VERSION ""

NS_ :

BS_:

BU_: SOBDM_BCCM GWM GENERIC BECM TSTR

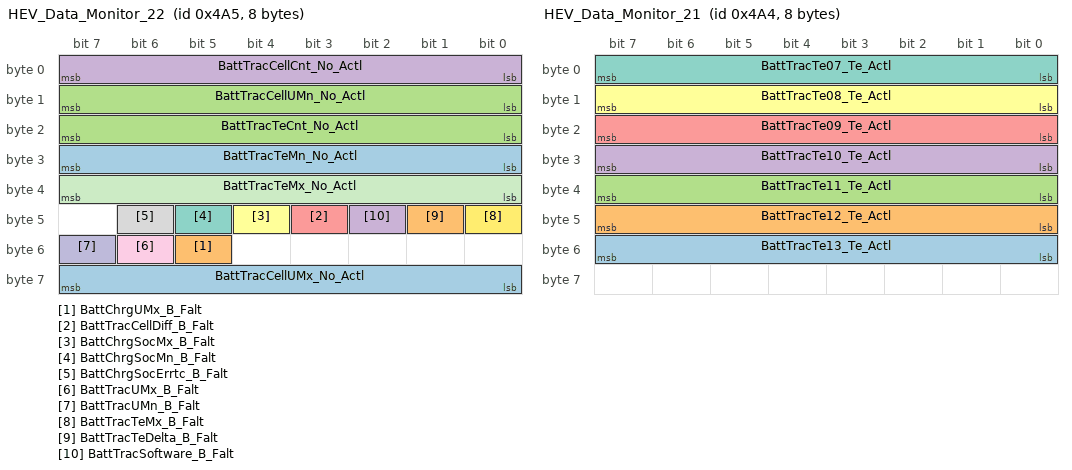
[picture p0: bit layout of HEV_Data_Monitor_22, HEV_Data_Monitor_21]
BO_ 1189 HEV_Data_Monitor_22: 8 BECM
 SG_ BattTracCellUMx_No_Actl : 63|8@0+ (1,0) [0|253] "Unitless"  GWM
 SG_ BattChrgUMx_B_Falt : 53|1@0+ (1,0) [0|1] "SED"  GWM
 SG_ BattTracCellUMn_No_Actl : 15|8@0+ (1,0) [0|253] "Unitless"  GWM
 SG_ BattTracCellCnt_No_Actl : 7|8@0+ (1,0) [0|253] "Unitless"  GWM
 SG_ BattTracCellDiff_B_Falt : 43|1@0+ (1,0) [0|1] "SED"  GWM
 SG_ BattChrgSocMx_B_Falt : 44|1@0+ (1,0) [0|1] "SED"  GWM
 SG_ BattChrgSocMn_B_Falt : 45|1@0+ (1,0) [0|1] "SED"  GWM
 SG_ BattChrgSocErrtc_B_Falt : 46|1@0+ (1,0) [0|1] "SED"  GWM
 SG_ BattTracUMx_B_Falt : 54|1@0+ (1,0) [0|1] "SED"  GWM
 SG_ BattTracUMn_B_Falt : 55|1@0+ (1,0) [0|1] "SED"  GWM
 SG_ BattTracTeMx_No_Actl : 39|8@0+ (1,0) [0|253] "Unitless"  GWM
 SG_ BattTracTeMx_B_Falt : 40|1@0+ (1,0) [0|1] "SED"  GWM
 SG_ BattTracTeMn_No_Actl : 31|8@0+ (1,0) [0|253] "Unitless"  GWM
 SG_ BattTracTeDelta_B_Falt : 41|1@0+ (1,0) [0|1] "SED"  GWM
 SG_ BattTracTeCnt_No_Actl : 23|8@0+ (1,0) [0|253] "Unitless"  GWM
 SG_ BattTracSoftware_B_Falt : 42|1@0+ (1,0) [0|1] "SED"  GWM

BO_ 1188 HEV_Data_Monitor_21: 8 BECM
 SG_ BattTracTe13_Te_Actl : 55|8@0+ (1,-50) [-50|203] "degC"  GWM
 SG_ BattTracTe12_Te_Actl : 47|8@0+ (1,-50) [-50|203] "degC"  GWM
 SG_ BattTracTe11_Te_Actl : 39|8@0+ (1,-50) [-50|203] "degC"  GWM
 SG_ BattTracTe10_Te_Actl : 31|8@0+ (1,-50) [-50|203] "degC"  GWM
 SG_ BattTracTe09_Te_Actl : 23|8@0+ (1,-50) [-50|203] "degC"  GWM
 SG_ BattTracTe08_Te_Actl : 15|8@0+ (1,-50) [-50|203] "degC"  GWM
 SG_ BattTracTe07_Te_Actl : 7|8@0+ (1,-50) [-50|203] "degC"  GWM

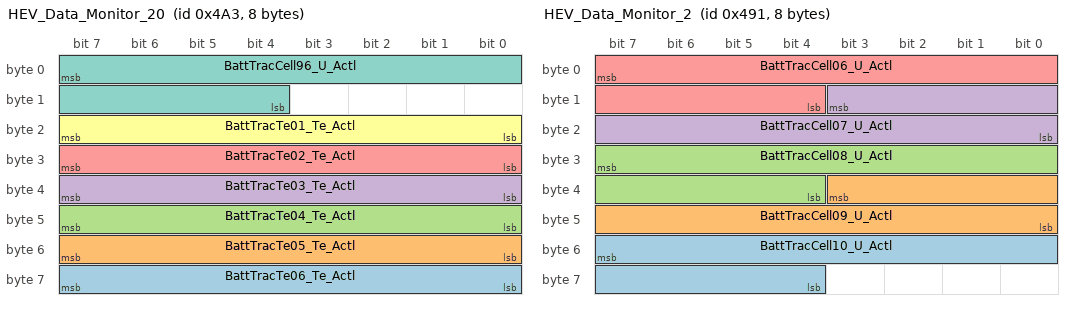
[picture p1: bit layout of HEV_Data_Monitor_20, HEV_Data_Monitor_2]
BO_ 1187 HEV_Data_Monitor_20: 8 BECM
 SG_ BattTracTe06_Te_Actl : 63|8@0+ (1,-50) [-50|203] "degC"  GWM
 SG_ BattTracTe05_Te_Actl : 55|8@0+ (1,-50) [-50|203] "degC"  GWM
 SG_ BattTracTe04_Te_Actl : 47|8@0+ (1,-50) [-50|203] "degC"  GWM
 SG_ BattTracTe03_Te_Actl : 39|8@0+ (1,-50) [-50|203] "degC"  GWM
 SG_ BattTracTe02_Te_Actl : 31|8@0+ (1,-50) [-50|203] "degC"  GWM
 SG_ BattTracTe01_Te_Actl : 23|8@0+ (1,-50) [-50|203] "degC"  GWM
 SG_ BattTracCell96_U_Actl : 7|12@0+ (0.001,1) [1|5.093] "volt"  GWM

BO_ 1169 HEV_Data_Monitor_2: 8 BECM
 SG_ BattTracCell10_U_Actl : 55|12@0+ (0.001,1) [1|5.093] "volt"  GWM
 SG_ BattTracCell09_U_Actl : 35|12@0+ (0.001,1) [1|5.093] "volt"  GWM
 SG_ BattTracCell08_U_Actl : 31|12@0+ (0.001,1) [1|5.093] "volt"  GWM
 SG_ BattTracCell07_U_Actl : 11|12@0+ (0.001,1) [1|5.093] "volt"  GWM
 SG_ BattTracCell06_U_Actl : 7|12@0+ (0.001,1) [1|5.093] "volt"  GWM

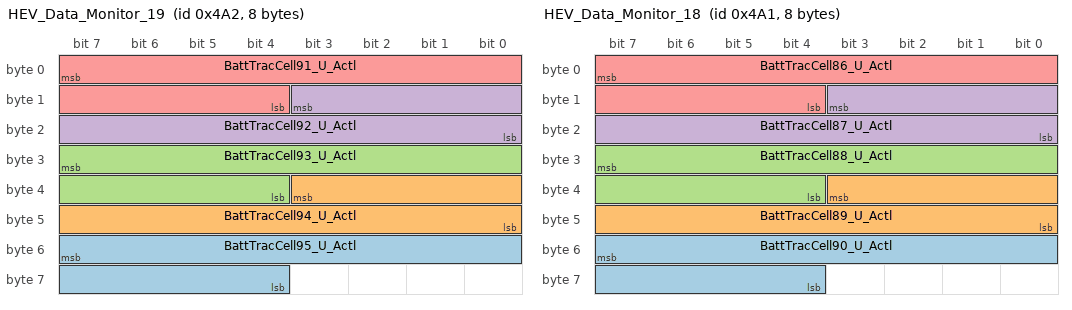
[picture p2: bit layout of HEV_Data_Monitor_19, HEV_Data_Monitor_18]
BO_ 1186 HEV_Data_Monitor_19: 8 BECM
 SG_ BattTracCell95_U_Actl : 55|12@0+ (0.001,1) [1|5.093] "volt"  GWM
 SG_ BattTracCell94_U_Actl : 35|12@0+ (0.001,1) [1|5.093] "volt"  GWM
 SG_ BattTracCell93_U_Actl : 31|12@0+ (0.001,1) [1|5.093] "volt"  GWM
 SG_ BattTracCell92_U_Actl : 11|12@0+ (0.001,1) [1|5.093] "volt"  GWM
 SG_ BattTracCell91_U_Actl : 7|12@0+ (0.001,1) [1|5.093] "volt"  GWM

BO_ 1185 HEV_Data_Monitor_18: 8 BECM
 SG_ BattTracCell90_U_Actl : 55|12@0+ (0.001,1) [1|5.093] "volt"  GWM
 SG_ BattTracCell89_U_Actl : 35|12@0+ (0.001,1) [1|5.093] "volt"  GWM
 SG_ BattTracCell88_U_Actl : 31|12@0+ (0.001,1) [1|5.093] "volt"  GWM
 SG_ BattTracCell87_U_Actl : 11|12@0+ (0.001,1) [1|5.093] "volt"  GWM
 SG_ BattTracCell86_U_Actl : 7|12@0+ (0.001,1) [1|5.093] "volt"  GWM

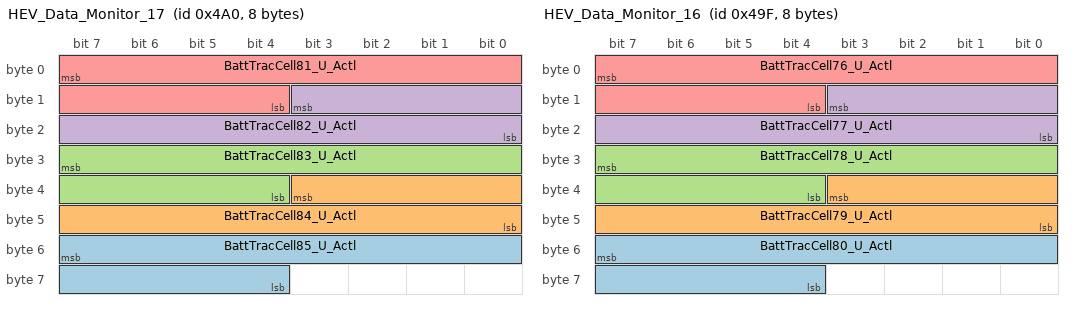
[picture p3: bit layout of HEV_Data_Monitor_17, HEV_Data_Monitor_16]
BO_ 1184 HEV_Data_Monitor_17: 8 BECM
 SG_ BattTracCell85_U_Actl : 55|12@0+ (0.001,1) [1|5.093] "volt"  GWM
 SG_ BattTracCell84_U_Actl : 35|12@0+ (0.001,1) [1|5.093] "volt"  GWM
 SG_ BattTracCell83_U_Actl : 31|12@0+ (0.001,1) [1|5.093] "volt"  GWM
 SG_ BattTracCell82_U_Actl : 11|12@0+ (0.001,1) [1|5.093] "volt"  GWM
 SG_ BattTracCell81_U_Actl : 7|12@0+ (0.001,1) [1|5.093] "volt"  GWM

BO_ 1183 HEV_Data_Monitor_16: 8 BECM
 SG_ BattTracCell80_U_Actl : 55|12@0+ (0.001,1) [1|5.093] "volt"  GWM
 SG_ BattTracCell79_U_Actl : 35|12@0+ (0.001,1) [1|5.093] "volt"  GWM
 SG_ BattTracCell78_U_Actl : 31|12@0+ (0.001,1) [1|5.093] "volt"  GWM
 SG_ BattTracCell77_U_Actl : 11|12@0+ (0.001,1) [1|5.093] "volt"  GWM
 SG_ BattTracCell76_U_Actl : 7|12@0+ (0.001,1) [1|5.093] "volt"  GWM

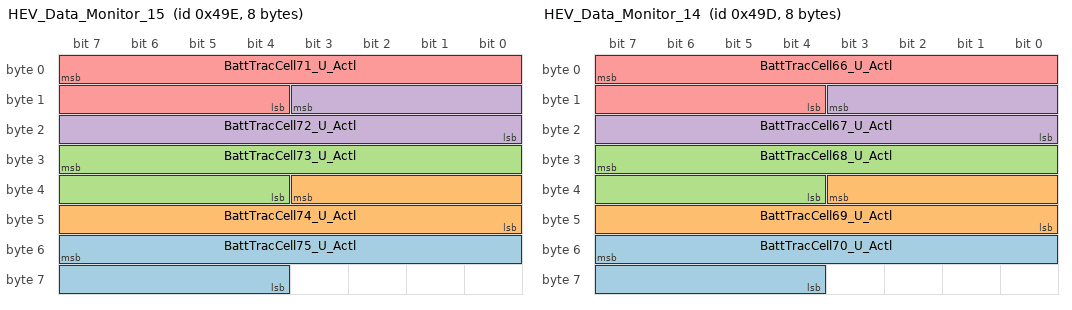
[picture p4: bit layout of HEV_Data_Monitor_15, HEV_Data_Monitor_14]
BO_ 1182 HEV_Data_Monitor_15: 8 BECM
 SG_ BattTracCell75_U_Actl : 55|12@0+ (0.001,1) [1|5.093] "volt"  GWM
 SG_ BattTracCell74_U_Actl : 35|12@0+ (0.001,1) [1|5.093] "volt"  GWM
 SG_ BattTracCell73_U_Actl : 31|12@0+ (0.001,1) [1|5.093] "volt"  GWM
 SG_ BattTracCell72_U_Actl : 11|12@0+ (0.001,1) [1|5.093] "volt"  GWM
 SG_ BattTracCell71_U_Actl : 7|12@0+ (0.001,1) [1|5.093] "volt"  GWM

BO_ 1181 HEV_Data_Monitor_14: 8 BECM
 SG_ BattTracCell70_U_Actl : 55|12@0+ (0.001,1) [1|5.093] "volt"  GWM
 SG_ BattTracCell69_U_Actl : 35|12@0+ (0.001,1) [1|5.093] "volt"  GWM
 SG_ BattTracCell68_U_Actl : 31|12@0+ (0.001,1) [1|5.093] "volt"  GWM
 SG_ BattTracCell67_U_Actl : 11|12@0+ (0.001,1) [1|5.093] "volt"  GWM
 SG_ BattTracCell66_U_Actl : 7|12@0+ (0.001,1) [1|5.093] "volt"  GWM

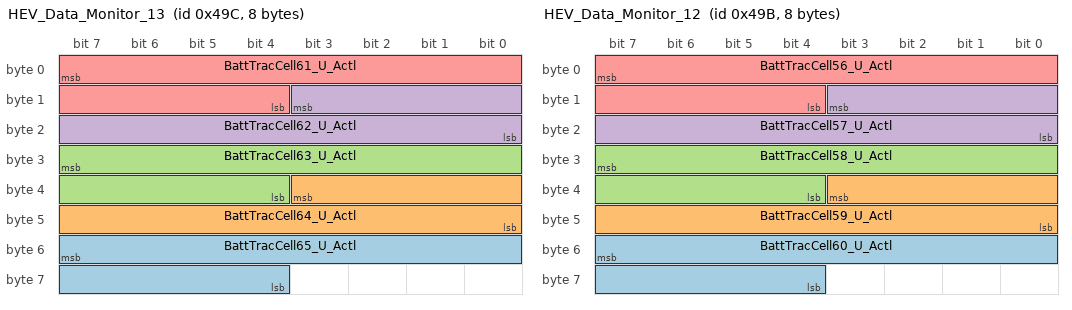
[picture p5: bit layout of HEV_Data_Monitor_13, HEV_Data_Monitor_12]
BO_ 1180 HEV_Data_Monitor_13: 8 BECM
 SG_ BattTracCell65_U_Actl : 55|12@0+ (0.001,1) [1|5.093] "volt"  GWM
 SG_ BattTracCell64_U_Actl : 35|12@0+ (0.001,1) [1|5.093] "volt"  GWM
 SG_ BattTracCell63_U_Actl : 31|12@0+ (0.001,1) [1|5.093] "volt"  GWM
 SG_ BattTracCell62_U_Actl : 11|12@0+ (0.001,1) [1|5.093] "volt"  GWM
 SG_ BattTracCell61_U_Actl : 7|12@0+ (0.001,1) [1|5.093] "volt"  GWM

BO_ 1179 HEV_Data_Monitor_12: 8 BECM
 SG_ BattTracCell60_U_Actl : 55|12@0+ (0.001,1) [1|5.093] "volt"  GWM
 SG_ BattTracCell59_U_Actl : 35|12@0+ (0.001,1) [1|5.093] "volt"  GWM
 SG_ BattTracCell58_U_Actl : 31|12@0+ (0.001,1) [1|5.093] "volt"  GWM
 SG_ BattTracCell57_U_Actl : 11|12@0+ (0.001,1) [1|5.093] "volt"  GWM
 SG_ BattTracCell56_U_Actl : 7|12@0+ (0.001,1) [1|5.093] "volt"  GWM

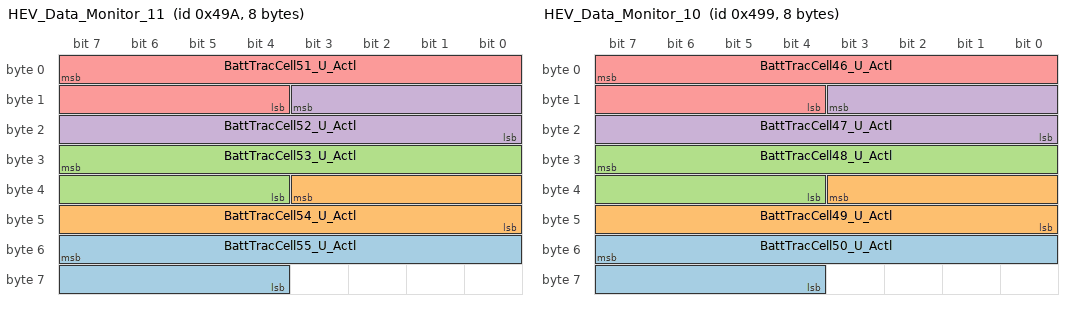
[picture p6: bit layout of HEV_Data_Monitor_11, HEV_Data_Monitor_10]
BO_ 1178 HEV_Data_Monitor_11: 8 BECM
 SG_ BattTracCell55_U_Actl : 55|12@0+ (0.001,1) [1|5.093] "volt"  GWM
 SG_ BattTracCell54_U_Actl : 35|12@0+ (0.001,1) [1|5.093] "volt"  GWM
 SG_ BattTracCell53_U_Actl : 31|12@0+ (0.001,1) [1|5.093] "volt"  GWM
 SG_ BattTracCell52_U_Actl : 11|12@0+ (0.001,1) [1|5.093] "volt"  GWM
 SG_ BattTracCell51_U_Actl : 7|12@0+ (0.001,1) [1|5.093] "volt"  GWM

BO_ 1177 HEV_Data_Monitor_10: 8 BECM
 SG_ BattTracCell50_U_Actl : 55|12@0+ (0.001,1) [1|5.093] "volt"  GWM
 SG_ BattTracCell49_U_Actl : 35|12@0+ (0.001,1) [1|5.093] "volt"  GWM
 SG_ BattTracCell48_U_Actl : 31|12@0+ (0.001,1) [1|5.093] "volt"  GWM
 SG_ BattTracCell47_U_Actl : 11|12@0+ (0.001,1) [1|5.093] "volt"  GWM
 SG_ BattTracCell46_U_Actl : 7|12@0+ (0.001,1) [1|5.093] "volt"  GWM

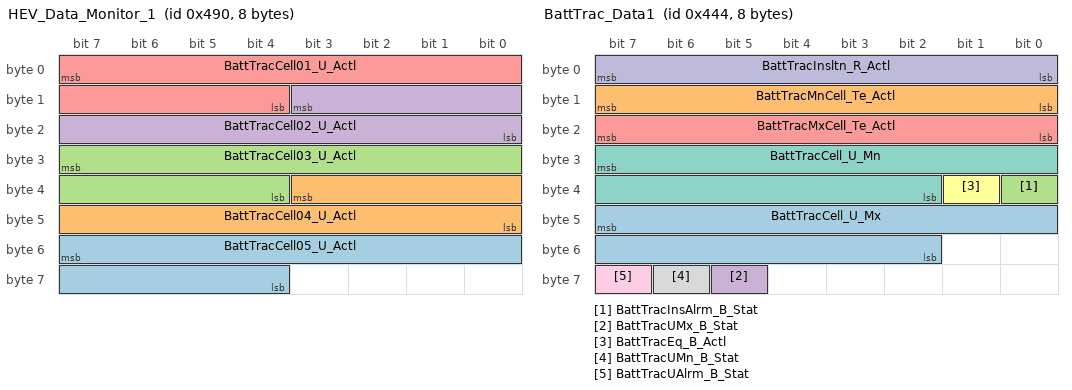
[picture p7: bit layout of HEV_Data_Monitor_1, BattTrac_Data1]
BO_ 1168 HEV_Data_Monitor_1: 8 BECM
 SG_ BattTracCell05_U_Actl : 55|12@0+ (0.001,1) [1|5.093] "volt"  GWM
 SG_ BattTracCell04_U_Actl : 35|12@0+ (0.001,1) [1|5.093] "volt"  GWM
 SG_ BattTracCell03_U_Actl : 31|12@0+ (0.001,1) [1|5.093] "volt"  GWM
 SG_ BattTracCell02_U_Actl : 11|12@0+ (0.001,1) [1|5.093] "volt"  GWM
 SG_ BattTracCell01_U_Actl : 7|12@0+ (0.001,1) [1|5.093] "volt"  GWM

BO_ 1092 BattTrac_Data1: 8 BECM
 SG_ BattTracCell_U_Mx : 47|14@0+ (0.001,0) [0|16.382] "volt"  GWM
 SG_ BattTracMnCell_Te_Actl : 15|8@0+ (1,-40) [-40|213] "degC"  GWM
 SG_ BattTracInsAlrm_B_Stat : 32|1@0+ (1,0) [0|1] "SED"  GWM
 SG_ BattTracUMx_B_Stat : 61|1@0+ (1,0) [0|1] "SED"  GWM
 SG_ BattTracMxCell_Te_Actl : 23|8@0+ (1,-40) [-40|213] "degC"  GWM
 SG_ BattTracEq_B_Actl : 33|1@0+ (1,0) [0|1] "SED"  GWM
 SG_ BattTracCell_U_Mn : 31|14@0+ (0.001,0) [0|16.382] "volt"  GWM
 SG_ BattTracUMn_B_Stat : 62|1@0+ (1,0) [0|1] "SED"  GWM
 SG_ BattTracUAlrm_B_Stat : 63|1@0+ (1,0) [0|1] "SED"  GWM
 SG_ BattTracInsltn_R_Actl : 7|8@0+ (6000,0) [0|1524000] "ohm"  GWM

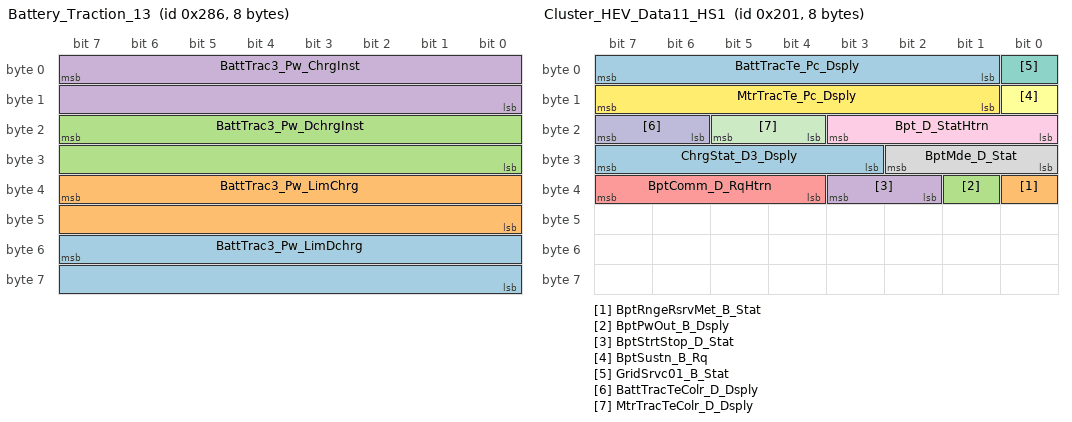
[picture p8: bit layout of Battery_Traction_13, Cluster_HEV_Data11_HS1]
BO_ 646 Battery_Traction_13: 8 BECM
 SG_ BattTrac3_Pw_LimDchrg : 55|16@0+ (50,0) [0|3276750] "watts"  GWM
 SG_ BattTrac3_Pw_LimChrg : 39|16@0+ (50,0) [0|3276750] "watts"  GWM
 SG_ BattTrac3_Pw_DchrgInst : 23|16@0+ (50,0) [0|3276750] "watts"  GWM
 SG_ BattTrac3_Pw_ChrgInst : 7|16@0+ (50,0) [0|3276750] "watts"  GWM

BO_ 513 Cluster_HEV_Data11_HS1: 8 GWM
 SG_ ChrgStat_D3_Dsply : 31|5@0+ (1,0) [0|31] "SED" Vector__XXX
 SG_ BptRngeRsrvMet_B_Stat : 32|1@0+ (1,0) [0|1] "SED" Vector__XXX
 SG_ BptPwOut_B_Dsply : 33|1@0+ (1,0) [0|1] "SED" Vector__XXX
 SG_ BptStrtStop_D_Stat : 35|2@0+ (1,0) [0|3] "SED" Vector__XXX
 SG_ BptComm_D_RqHtrn : 39|4@0+ (1,0) [0|15] "SED" Vector__XXX
 SG_ BptSustn_B_Rq : 8|1@0+ (1,0) [0|1] "SED"  BECM,SOBDM_BCCM
 SG_ GridSrvc01_B_Stat : 0|1@0+ (1,0) [0|1] "SED" Vector__XXX
 SG_ BptMde_D_Stat : 26|3@0+ (1,0) [0|7] "SED" Vector__XXX
 SG_ Bpt_D_StatHtrn : 19|4@0+ (1,0) [0|15] "SED"  BECM,SOBDM_BCCM
 SG_ BattTracTeColr_D_Dsply : 23|2@0+ (1,0) [0|3] "SED" Vector__XXX
 SG_ MtrTracTeColr_D_Dsply : 21|2@0+ (1,0) [0|3] "SED" Vector__XXX
 SG_ MtrTracTe_Pc_Dsply : 15|7@0+ (1,0) [0|127] "percent" Vector__XXX
 SG_ BattTracTe_Pc_Dsply : 7|7@0+ (1,0) [0|127] "percent" Vector__XXX

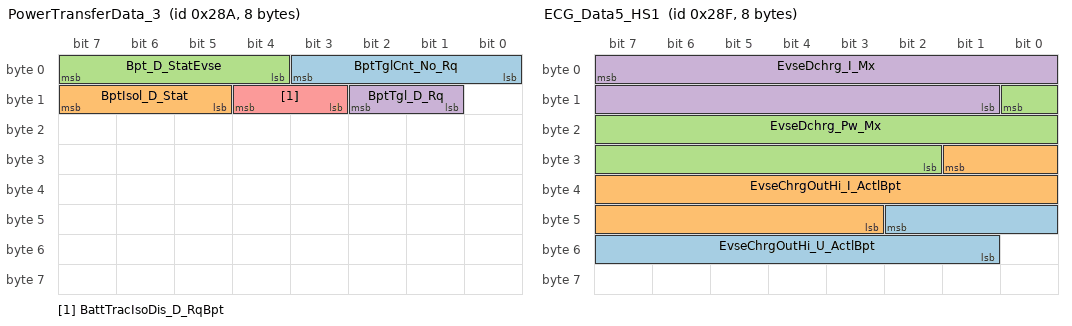
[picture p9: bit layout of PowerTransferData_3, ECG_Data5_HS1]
BO_ 650 PowerTransferData_3: 8 GWM
 SG_ BptTglCnt_No_Rq : 3|4@0+ (1,0) [0|13] "unitless"  SOBDM_BCCM
 SG_ BptIsol_D_Stat : 15|3@0+ (1,0) [0|7] "SED"  BECM
 SG_ Bpt_D_StatEvse : 7|4@0+ (1,0) [0|15] "SED"  BECM
 SG_ BptTgl_D_Rq : 10|2@0+ (1,0) [0|3] "SED"  SOBDM_BCCM
 SG_ BattTracIsoDis_D_RqBpt : 12|2@0+ (1,0) [0|3] "SED"  SOBDM_BCCM,BECM

BO_ 655 ECG_Data5_HS1: 8 GWM
 SG_ EvseChrgOutHi_U_ActlBpt : 42|10@0+ (0.5,0) [0|510.5] "volt"  SOBDM_BCCM
 SG_ EvseChrgOutHi_I_ActlBpt : 25|15@0+ (0.05,-750) [-750|888.25] "ampere"  SOBDM_BCCM
 SG_ EvseDchrg_Pw_Mx : 8|15@0+ (50,0) [0|1638250] "wattS"  SOBDM_BCCM
 SG_ EvseDchrg_I_Mx : 7|15@0+ (0.05,0) [0|1638.25] "ampere"  SOBDM_BCCM

BO_ 599 Battery_Traction_12: 8 BECM
 SG_ Bpt_D_StatBattTrac : 7|3@0+ (1,0) [0|7] "SED"  SOBDM_BCCM,GWM

BO_ 749 BatteryCharge_Data3: 8 SOBDM_BCCM
 SG_ ChrgrSysFalt18_D_Stat : 37|2@0+ (1,0) [0|3] "SED"  BECM,GWM
 SG_ ChrgrSysFalt17_D_Stat : 39|2@0+ (1,0) [0|3] "SED"  BECM,GWM
 SG_ ChrgrSysFalt16_D_Stat : 25|2@0+ (1,0) [0|3] "SED"  BECM,GWM
 SG_ ChrgrSysFalt15_D_Stat : 27|2@0+ (1,0) [0|3] "SED"  BECM,GWM
 SG_ ChrgrSysFalt14_D_Stat : 29|2@0+ (1,0) [0|3] "SED"  BECM,GWM
 SG_ ChrgrSysFalt13_D_Stat : 31|2@0+ (1,0) [0|3] "SED"  BECM,GWM
 SG_ ChrgrSysFalt12_D_Stat : 17|2@0+ (1,0) [0|3] "SED"  BECM,GWM
 SG_ ChrgrSysFalt11_D_Stat : 19|2@0+ (1,0) [0|3] "SED"  BECM,GWM
 SG_ ChrgrSysFalt9_D_Stat : 23|2@0+ (1,0) [0|3] "SED"  BECM,GWM
 SG_ ChrgrSysFalt8_D_Stat : 9|2@0+ (1,0) [0|3] "SED"  BECM,GWM
 SG_ ChrgrSysFalt7_D_Stat : 11|2@0+ (1,0) [0|3] "SED"  BECM,GWM
 SG_ ChrgrSysFalt6_D_Stat : 13|2@0+ (1,0) [0|3] "SED"  BECM,GWM
 SG_ ChrgrSysFalt5_D_Stat : 15|2@0+ (1,0) [0|3] "SED"  BECM,GWM
 SG_ ChrgrSysFalt4_D_Stat : 1|2@0+ (1,0) [0|3] "SED"  BECM,GWM
 SG_ ChrgrSysFalt3_D_Stat : 3|2@0+ (1,0) [0|3] "SED"  BECM,GWM
 SG_ ChrgrSysFalt2_D_Stat : 5|2@0+ (1,0) [0|3] "SED"  BECM,GWM
 SG_ ChrgrSysFalt1_D_Stat : 7|2@0+ (1,0) [0|3] "SED"  BECM,GWM
 SG_ ChrgrSysFalt10_D_Stat : 21|2@0+ (1,0) [0|3] "SED"  BECM,GWM

BO_ 580 Battery_Traction_11: 8 BECM
 SG_ BattTracVrtOck_B_Rq : 7|1@0+ (1,0) [0|1] "SED"  GWM

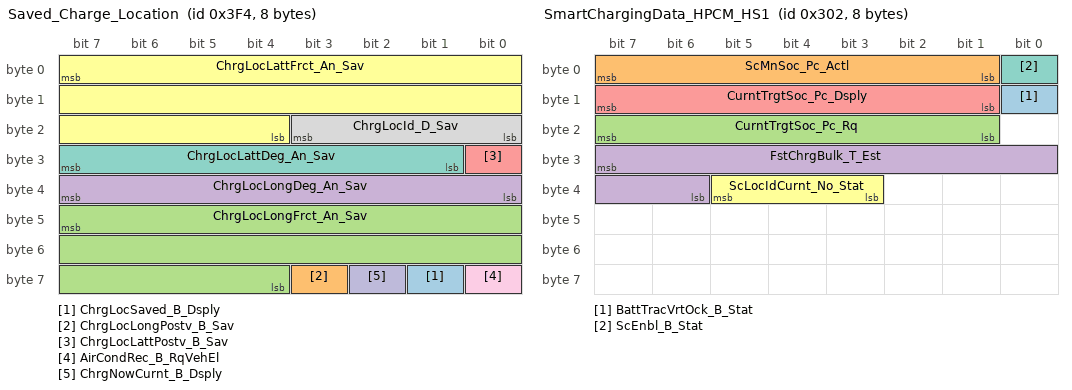
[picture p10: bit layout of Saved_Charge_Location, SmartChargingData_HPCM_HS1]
BO_ 1012 Saved_Charge_Location: 8 GWM
 SG_ ChrgLocSaved_B_Dsply : 57|1@0+ (1,0) [0|1] "SED" Vector__XXX
 SG_ ChrgLocLongPostv_B_Sav : 59|1@0+ (1,0) [0|1] "SED" Vector__XXX
 SG_ ChrgLocLongFrct_An_Sav : 47|20@0+ (1E-006,0) [0|1.048575] "degrees" Vector__XXX
 SG_ ChrgLocLongDeg_An_Sav : 39|8@0+ (1,0) [0|255] "degrees" Vector__XXX
 SG_ ChrgLocLattPostv_B_Sav : 24|1@0+ (1,0) [0|1] "SED" Vector__XXX
 SG_ ChrgLocLattFrct_An_Sav : 7|20@0+ (1E-006,0) [0|1.048575] "degrees" Vector__XXX
 SG_ ChrgLocLattDeg_An_Sav : 31|7@0+ (1,0) [0|127] "unitless" Vector__XXX
 SG_ ChrgLocId_D_Sav : 19|4@0+ (1,0) [0|15] "unitless" Vector__XXX
 SG_ AirCondRec_B_RqVehEl : 56|1@0+ (1,0) [0|1] "SED" Vector__XXX
 SG_ ChrgNowCurnt_B_Dsply : 58|1@0+ (1,0) [0|1] "SED"  SOBDM_BCCM

BO_ 1149 Battery_Traction_10: 8 BECM
 SG_ BattTracPerf_Pc_Dsply : 15|8@0+ (1,0) [0|253] "percent"  GWM
 SG_ BattTracPerf_Pc_Actl : 7|8@0+ (1,0) [0|253] "percent"  GWM

BO_ 1135 Battery_Traction_9: 8 BECM
 SG_ BattChrg_I2_Rq : 23|16@0+ (0.1,0) [0|6553.5] "ampere"  GWM,SOBDM_BCCM
 SG_ BattChrg_I2_Mx : 7|16@0+ (0.1,0) [0|6553.5] "ampere"  GWM

BO_ 770 SmartChargingData_HPCM_HS1: 8 GWM
 SG_ BattTracVrtOck_B_Stat : 8|1@0+ (1,0) [0|1] "SED" Vector__XXX
 SG_ ScMnSoc_Pc_Actl : 7|7@0+ (1,0) [0|127] "percent" Vector__XXX
 SG_ CurntTrgtSoc_Pc_Rq : 23|7@0+ (1,0) [0|127] "percent"  BECM
 SG_ FstChrgBulk_T_Est : 31|10@0+ (1,0) [0|1023] "minute" Vector__XXX
 SG_ CurntTrgtSoc_Pc_Dsply : 15|7@0+ (1,0) [0|127] "percent" Vector__XXX
 SG_ ScLocIdCurnt_No_Stat : 37|3@0+ (1,0) [0|7] "unitless" Vector__XXX
 SG_ ScEnbl_B_Stat : 0|1@0+ (1,0) [0|1] "SED" Vector__XXX

BO_ 123 Battery_Traction_2: 8 BECM
 SG_ BattTrac_U2_Actl : 21|12@0+ (0.5,0) [0|2046.5] "volt"  SOBDM_BCCM,GWM
 SG_ BattTrac_I2_Actl : 7|18@0+ (0.05,-6553.52) [-6553.52|6553.53] "ampere"  SOBDM_BCCM,GWM

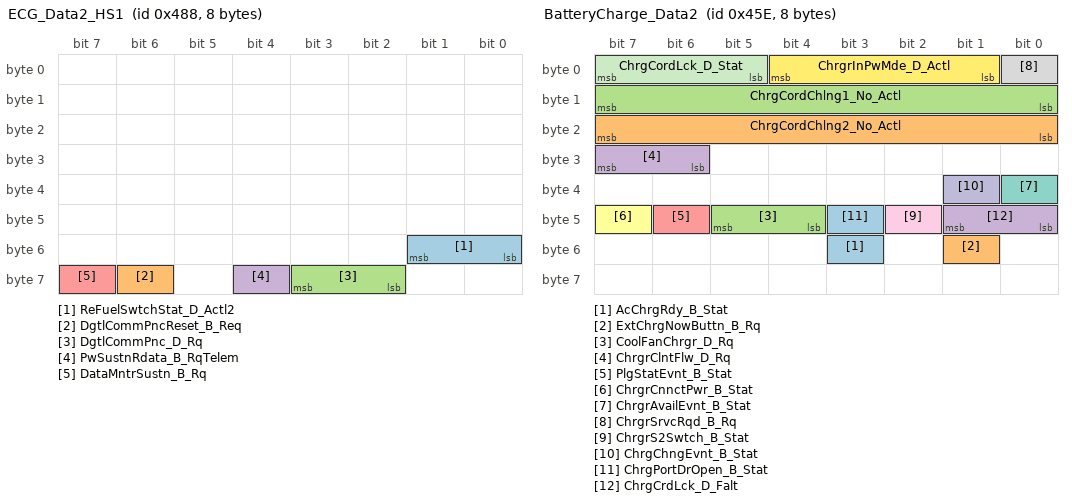
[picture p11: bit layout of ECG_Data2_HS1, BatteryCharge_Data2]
BO_ 1160 ECG_Data2_HS1: 8 GWM
 SG_ ReFuelSwtchStat_D_Actl2 : 49|2@0+ (1,0) [0|3] "SED" Vector__XXX
 SG_ DgtlCommPncReset_B_Req : 62|1@0+ (1,0) [0|1] "SED" Vector__XXX
 SG_ DgtlCommPnc_D_Rq : 59|2@0+ (1,0) [0|3] "SED" Vector__XXX
 SG_ PwSustnRdata_B_RqTelem : 60|1@0+ (1,0) [0|1] "SED"  BECM,SOBDM_BCCM
 SG_ DataMntrSustn_B_Rq : 63|1@0+ (1,0) [0|1] "SED"  BECM,SOBDM_BCCM

BO_ 1119 Voltage_Power_Data2: 8 GWM
 SG_ CoolFanDcdc_D_Rq : 5|2@0+ (1,0) [0|3] "SED"  BECM
 SG_ DcdcClntFlw_D_Rq : 7|2@0+ (1,0) [0|3] "SED"  BECM

BO_ 1152 HEV_Powertrain_Data6_HS1: 8 GWM
 SG_ PwOutlet8EnblScnd_B_Rq : 16|1@0+ (1,0) [0|1] "SED" Vector__XXX
 SG_ PwOutlet8Enbl_B_Rq : 17|1@0+ (1,0) [0|1] "SED" Vector__XXX
 SG_ PwOutlet7EnblScnd_B_Rq : 18|1@0+ (1,0) [0|1] "SED" Vector__XXX
 SG_ PwOutlet7Enbl_B_Rq : 19|1@0+ (1,0) [0|1] "SED" Vector__XXX
 SG_ PwOutlet6EnblScnd_B_Rq : 20|1@0+ (1,0) [0|1] "SED" Vector__XXX
 SG_ PwOutlet6Enbl_B_Rq : 21|1@0+ (1,0) [0|1] "SED" Vector__XXX
 SG_ PwCabinEnblScnd_B_Rq : 28|1@0+ (1,0) [0|1] "SED" Vector__XXX
 SG_ PwCabinEnbl_B_Rq : 29|1@0+ (1,0) [0|1] "SED" Vector__XXX
 SG_ PwTrnkFrntEnblScnd_B_Rq : 30|1@0+ (1,0) [0|1] "SED" Vector__XXX
 SG_ PwTrnkFrntEnbl_B_Rq : 31|1@0+ (1,0) [0|1] "SED" Vector__XXX
 SG_ OnePdlDrvLamp_B_Rq : 23|1@0+ (1,0) [0|1] "SED" Vector__XXX
 SG_ OnePdlDrv_D_Dsply : 4|2@0+ (1,0) [0|3] "SED" Vector__XXX
 SG_ HybPwULoLamp_B_Rq : 22|1@0+ (1,0) [0|1] "SED" Vector__XXX
 SG_ GrdAsstActv_B_Stat : 8|1@0+ (1,0) [0|1] "SED" Vector__XXX
 SG_ StopStrtVThres_D_Stat : 1|2@0+ (1,0) [0|3] "SED" Vector__XXX
 SG_ VehElEff_No_Avg : 15|7@0+ (10,-100) [-100|1150] "watt*hr/km" Vector__XXX
 SG_ EngTeHi_B_Actl : 5|1@0+ (1,0) [0|1] "SED" Vector__XXX
 SG_ DcdcOn_B_Rq : 6|1@0+ (1,0) [0|1] "SED" Vector__XXX
 SG_ BattTracDiagClr_B_Stat : 2|1@0+ (1,0) [0|1] "SED"  BECM
 SG_ ULoBattSpprtSustn_B_Rq : 7|1@0+ (1,0) [0|1] "SED"  BECM,SOBDM_BCCM

BO_ 1118 BatteryCharge_Data2: 8 SOBDM_BCCM
 SG_ AcChrgRdy_B_Stat : 51|1@0+ (1,0) [0|1] "SED"  GWM,BECM
 SG_ ExtChrgNowButtn_B_Rq : 49|1@0+ (1,0) [0|1] "SED"  GWM
 SG_ CoolFanChrgr_D_Rq : 45|2@0+ (1,0) [0|3] "SED"  BECM,GWM
 SG_ ChrgrClntFlw_D_Rq : 31|2@0+ (1,0) [0|3] "SED"  BECM,GWM
 SG_ PlgStatEvnt_B_Stat : 46|1@0+ (1,0) [0|1] "SED"  BECM,GWM
 SG_ ChrgrCnnctPwr_B_Stat : 47|1@0+ (1,0) [0|1] "SED"  BECM,GWM
 SG_ ChrgrAvailEvnt_B_Stat : 32|1@0+ (1,0) [0|1] "SED"  BECM,GWM
 SG_ ChrgrSrvcRqd_B_Rq : 0|1@0+ (1,0) [0|1] "SED"  GWM
 SG_ ChrgrS2Swtch_B_Stat : 42|1@0+ (1,0) [0|1] "SED"  GWM
 SG_ ChrgChngEvnt_B_Stat : 33|1@0+ (1,0) [0|1] "SED"  BECM,GWM
 SG_ ChrgCordLck_D_Stat : 7|3@0+ (1,0) [0|7] "SED"  GWM
 SG_ ChrgrInPwMde_D_Actl : 4|4@0+ (1,0) [0|15] "SED"  BECM,GWM
 SG_ ChrgPortDrOpen_B_Stat : 43|1@0+ (1,0) [0|1] "SED"  GWM
 SG_ ChrgCordChlng2_No_Actl : 23|8@0+ (1,0) [0|255] "unitless"  GWM
 SG_ ChrgCordChlng1_No_Actl : 15|8@0+ (1,0) [0|255] "unitless"  GWM
 SG_ ChrgCrdLck_D_Falt : 41|2@0+ (1,0) [0|3] "SED"  GWM

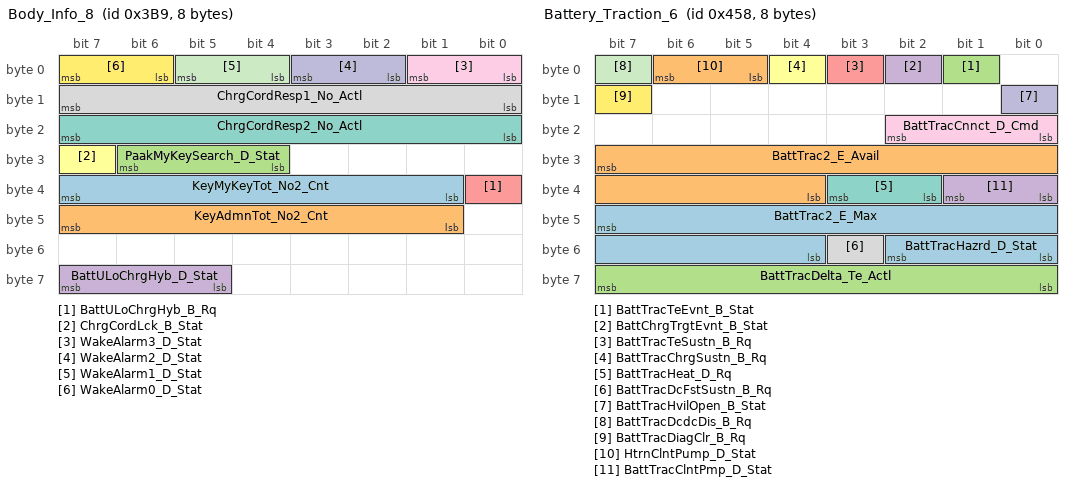
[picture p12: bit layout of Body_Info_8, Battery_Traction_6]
BO_ 953 Body_Info_8: 8 GWM
 SG_ KeyMyKeyTot_No2_Cnt : 39|7@0+ (1,0) [0|127] "unitless" Vector__XXX
 SG_ KeyAdmnTot_No2_Cnt : 47|7@0+ (1,0) [0|127] "unitless" Vector__XXX
 SG_ PaakMyKeySearch_D_Stat : 30|3@0+ (1,0) [0|7] "SED" Vector__XXX
 SG_ BattULoChrgHyb_D_Stat : 63|3@0+ (1,0) [0|7] "SED" Vector__XXX
 SG_ BattULoChrgHyb_B_Rq : 32|1@0+ (1,0) [0|1] "SED" Vector__XXX
 SG_ ChrgCordLck_B_Stat : 31|1@0+ (1,0) [0|1] "SED"  SOBDM_BCCM
 SG_ ChrgCordResp2_No_Actl : 23|8@0+ (1,0) [0|255] "unitless"  SOBDM_BCCM
 SG_ ChrgCordResp1_No_Actl : 15|8@0+ (1,0) [0|255] "unitless"  SOBDM_BCCM
 SG_ WakeAlarm3_D_Stat : 1|2@0+ (1,0) [0|3] "SED" Vector__XXX
 SG_ WakeAlarm2_D_Stat : 3|2@0+ (1,0) [0|3] "SED" Vector__XXX
 SG_ WakeAlarm1_D_Stat : 5|2@0+ (1,0) [0|3] "SED" Vector__XXX
 SG_ WakeAlarm0_D_Stat : 7|2@0+ (1,0) [0|3] "SED" Vector__XXX

BO_ 1112 Battery_Traction_6: 8 BECM
 SG_ BattTrac2_E_Max : 47|12@0+ (50,0) [0|204650] "watt*hour"  GWM
 SG_ BattTrac2_E_Avail : 31|12@0+ (50,0) [0|204650] "watt*hour"  GWM
 SG_ BattTracTeEvnt_B_Stat : 1|1@0+ (1,0) [0|1] "SED"  GWM,SOBDM_BCCM
 SG_ BattChrgTrgtEvnt_B_Stat : 2|1@0+ (1,0) [0|1] "SED"  GWM,SOBDM_BCCM
 SG_ BattTracTeSustn_B_Rq : 3|1@0+ (1,0) [0|1] "SED"  GWM
 SG_ BattTracChrgSustn_B_Rq : 4|1@0+ (1,0) [0|1] "SED"  GWM,SOBDM_BCCM
 SG_ BattTracHeat_D_Rq : 35|2@0+ (1,0) [0|3] "SED"  GWM
 SG_ BattTracDcFstSustn_B_Rq : 51|1@0+ (1,0) [0|1] "SED"  GWM
 SG_ BattTracCnnct_D_Cmd : 18|3@0+ (1,0) [0|7] "SED"  SOBDM_BCCM,GWM
 SG_ BattTracHvilOpen_B_Stat : 8|1@0+ (1,0) [0|1] "SED"  GWM
 SG_ BattTracDcdcDis_B_Rq : 7|1@0+ (1,0) [0|1] "SED"  GWM
 SG_ BattTracDiagClr_B_Rq : 15|1@0+ (1,0) [0|1] "SED"  GWM
 SG_ BattTracHazrd_D_Stat : 50|3@0+ (1,0) [0|7] "SED"  GWM
 SG_ HtrnClntPump_D_Stat : 6|2@0+ (1,0) [0|3] "SED"  GWM,SOBDM_BCCM
 SG_ BattTracDelta_Te_Actl : 63|8@0+ (0.5,-60) [-60|66.5] "degC"  GWM
 SG_ BattTracClntPmp_D_Stat : 33|2@0+ (1,0) [0|3] "SED"  GWM

BO_ 1144 MHT_EV_Wakeup: 8 GWM
 SG_ AwdLckMde_D_Stat : 59|3@0+ (1,0) [0|7] "SED" Vector__XXX
 SG_ BattTracCool_B_Actl : 60|1@0+ (1,0) [0|1] "SED" Vector__XXX
 SG_ BattChrgTrgtSoC_D_Rq : 35|3@0+ (1,0) [0|7] "Percent" Vector__XXX
 SG_ PreCondBatt_B_Actl : 32|1@0+ (1,0) [0|1] "SED" Vector__XXX
 SG_ CabnEvapSovFront_B_Rq : 38|1@0+ (1,0) [0|1] "SED" Vector__XXX
 SG_ HeatCoreSovRear_B_Rq : 36|1@0+ (1,0) [0|1] "SED" Vector__XXX
 SG_ BattChlrSov_B_Rq : 39|1@0+ (1,0) [0|1] "SED" Vector__XXX
 SG_ CabnEvapSovRear_B_Rq : 37|1@0+ (1,0) [0|1] "SED" Vector__XXX
 SG_ BrkAppl_D_RqPt : 25|2@0+ (1,0) [0|3] "SED" Vector__XXX
 SG_ BattClntVlvOvrrd_D_Rq : 31|2@0+ (1,0) [0|3] "SED" Vector__XXX
 SG_ BattTracChillerOn_B_Rq : 27|1@0+ (1,0) [0|1] "SED" Vector__XXX
 SG_ BattTracChiller_D_Stat : 29|2@0+ (1,0) [0|3] "SED" Vector__XXX
 SG_ FstChrgCmplt_T_Est : 41|10@0+ (1,0) [0|1023] "minute" Vector__XXX
 SG_ ULoBattTrnsfrSustn_B_Rq : 43|1@0+ (1,0) [0|1] "SED"  BECM,SOBDM_BCCM
 SG_ ULoBattTransfer_D_Stat : 46|3@0+ (1,0) [0|7] "SED" Vector__XXX
 SG_ HtrnDcdcDis_B_Rq : 26|1@0+ (1,0) [0|1] "SED" Vector__XXX
 SG_ HtrnCnnctPwr_B_Stat : 16|1@0+ (1,0) [0|1] "SED"  BECM,SOBDM_BCCM
 SG_ PtcHtr_D_Stat : 18|2@0+ (1,0) [0|3] "SED" Vector__XXX
 SG_ BattChrgInhbt_D2_Rq : 63|3@0+ (1,0) [0|7] "SED"  SOBDM_BCCM
 SG_ WakeAlarm0_B_Typ : 21|1@0+ (1,0) [0|1] "SED" Vector__XXX
 SG_ WakeAlarm0_T_Rq : 7|15@0+ (1,0) [0|32767] "minute" Vector__XXX
 SG_ BattTracClimtDis_B_Stat : 42|1@0+ (1,0) [0|1] "SED" Vector__XXX
 SG_ HtrnClntFlw_D_Rq : 20|2@0+ (1,0) [0|3] "SED"  BECM
 SG_ BattTracDrvSustn_B_Rq : 8|1@0+ (1,0) [0|1] "SED"  BECM,SOBDM_BCCM
 SG_ CabinDrvSustn_B_Rq : 23|1@0+ (1,0) [0|1] "SED"  BECM,SOBDM_BCCM
 SG_ BattTracClntVlv_B_Rq : 47|1@0+ (1,0) [0|1] "SED" Vector__XXX
 SG_ ChrgNowEvnt_B_Stat : 22|1@0+ (1,0) [0|1] "SED"  BECM,SOBDM_BCCM

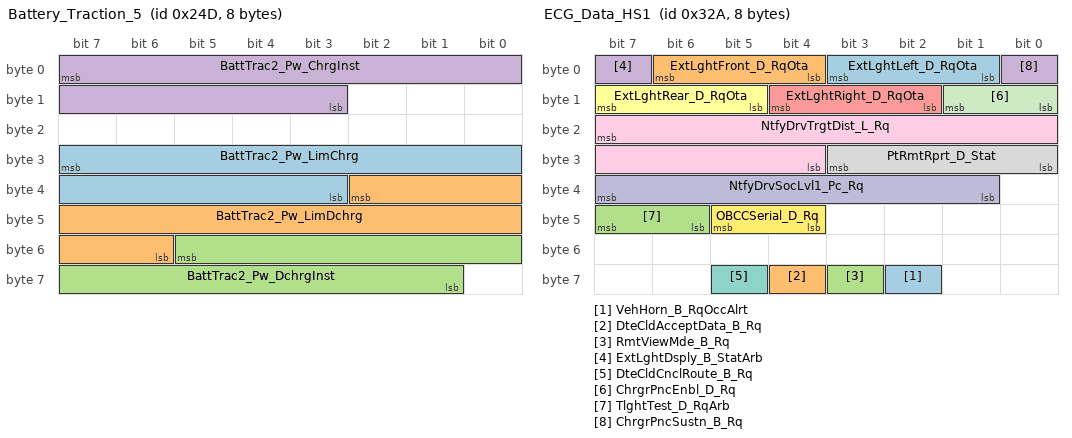
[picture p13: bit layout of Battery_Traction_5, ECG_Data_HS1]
BO_ 589 Battery_Traction_5: 8 BECM
 SG_ BattTrac2_Pw_LimChrg : 31|13@0+ (50,0) [0|409550] "watts"  GWM
 SG_ BattTrac2_Pw_LimDchrg : 34|13@0+ (50,0) [0|409550] "watts"  GWM
 SG_ BattTrac2_Pw_DchrgInst : 53|13@0+ (50,0) [0|409550] "watts"  GWM
 SG_ BattTrac2_Pw_ChrgInst : 7|13@0+ (50,0) [0|409550] "watts"  GWM

BO_ 1081 GatewayData7_HS1: 8 GWM
 SG_ ChirpRq_No_ActlTrlr_UB : 35|1@0+ (1,0) [0|1] "SED" Vector__XXX
 SG_ ChirpRq_No_ActlTrlr : 39|4@0+ (1,0) [0|15] "unitless" Vector__XXX
 SG_ Chirp_D_RqTrlr_UB : 24|1@0+ (1,0) [0|1] "SED" Vector__XXX
 SG_ Chirp_D_RqTrlr : 26|2@0+ (1,0) [0|3] "SED" Vector__XXX
 SG_ RearPassWindowPos_UB : 8|1@0+ (1,0) [0|1] "SED" Vector__XXX
 SG_ RearPassWindowPos : 11|3@0+ (1,0) [0|7] "SED" Vector__XXX
 SG_ RearDriverWindowPos_UB : 12|1@0+ (1,0) [0|1] "SED" Vector__XXX
 SG_ RearDriverWindowPos : 15|3@0+ (1,0) [0|7] "SED" Vector__XXX
 SG_ PassWindowPosition_UB : 0|1@0+ (1,0) [0|1] "SED" Vector__XXX
 SG_ PassWindowPosition : 3|3@0+ (1,0) [0|7] "SED" Vector__XXX
 SG_ DriverWindowPosition_UB : 4|1@0+ (1,0) [0|1] "SED" Vector__XXX
 SG_ DriverWindowPosition : 7|3@0+ (1,0) [0|7] "SED" Vector__XXX
 SG_ ChrgCrdLckEnbl_B_Stat : 21|1@0+ (1,0) [0|1] "SED"  SOBDM_BCCM
 SG_ ChrgCrdLckEnbl_B_Stat_UB : 23|1@0+ (1,0) [0|1] "SED"  SOBDM_BCCM
 SG_ EcoInhbt_B_RqHvac_UB : 30|1@0+ (1,0) [0|1] "SED" Vector__XXX
 SG_ EmgcyAsstActv_D_Stat_UB : 61|1@0+ (1,0) [0|1] "SED" Vector__XXX
 SG_ EmgcyAsstActv_D_Stat : 63|2@0+ (1,0) [0|3] "SED" Vector__XXX
 SG_ TrlrHitchLamp_D_Rq2_UB : 46|1@0+ (1,0) [0|1] "SED" Vector__XXX
 SG_ TrlrHitchLamp_D_Rq2 : 47|1@0+ (1,0) [0|1] "SED" Vector__XXX
 SG_ EcoInhbt_B_RqHvac : 31|1@0+ (1,0) [0|1] "SED" Vector__XXX

BO_ 810 ECG_Data_HS1: 8 GWM
 SG_ VehHorn_B_RqOccAlrt : 58|1@0+ (1,0) [0|1] "SED" Vector__XXX
 SG_ DteCldAcceptData_B_Rq : 60|1@0+ (1,0) [0|1] "SED" Vector__XXX
 SG_ RmtViewMde_B_Rq : 59|1@0+ (1,0) [0|1] "SED" Vector__XXX
 SG_ ExtLghtDsply_B_StatArb : 7|1@0+ (1,0) [0|1] "SED" Vector__XXX
 SG_ ExtLghtRight_D_RqOta : 12|3@0+ (1,0) [0|7] "SED" Vector__XXX
 SG_ ExtLghtRear_D_RqOta : 15|3@0+ (1,0) [0|7] "SED" Vector__XXX
 SG_ DteCldCnclRoute_B_Rq : 61|1@0+ (1,0) [0|1] "SED" Vector__XXX
 SG_ PtRmtRprt_D_Stat : 27|4@0+ (1,0) [0|15] "SED" Vector__XXX
 SG_ NtfyDrvTrgtDist_L_Rq : 23|12@0+ (0.1,0) [0|409.5] "Km" Vector__XXX
 SG_ NtfyDrvSocLvl1_Pc_Rq : 39|7@0+ (1,0) [0|127] "%" Vector__XXX
 SG_ ChrgrPncEnbl_D_Rq : 9|2@0+ (1,0) [0|3] "SED"  SOBDM_BCCM
 SG_ OBCCSerial_D_Rq : 45|2@0+ (1,0) [0|3] "SED" Vector__XXX
 SG_ ExtLghtLeft_D_RqOta : 3|3@0+ (1,0) [0|7] "SED" Vector__XXX
 SG_ ExtLghtFront_D_RqOta : 6|3@0+ (1,0) [0|7] "SED" Vector__XXX
 SG_ TlghtTest_D_RqArb : 47|2@0+ (1,0) [0|3] "SED" Vector__XXX
 SG_ ChrgrPncSustn_B_Rq : 0|1@0+ (1,0) [0|1] "SED"  SOBDM_BCCM

BO_ 1082 GatewayData3_HS1: 8 GWM
 SG_ VdmSustnActv_B_Rq_UB : 8|1@0+ (1,0) [0|1] "SED" Vector__XXX
 SG_ VdmSustnActv_B_Rq : 9|1@0+ (1,0) [0|1] "SED" Vector__XXX
 SG_ ChrgStatDsply_D_Rq_UB : 48|1@0+ (1,0) [0|1] "SED"  SOBDM_BCCM
 SG_ ChrgStatDsply_D_Rq : 63|2@0+ (1,0) [0|3] "SED"  SOBDM_BCCM
 SG_ ChrgCordUnlock_B_Rq_UB : 39|1@0+ (1,0) [0|1] "SED"  SOBDM_BCCM
 SG_ ChrgCordUnlock_B_Rq : 24|1@0+ (1,0) [0|1] "SED"  SOBDM_BCCM
 SG_ FldngSeatPwOffOk_B_Stat_UB : 47|1@0+ (1,0) [0|1] "SED" Vector__XXX
 SG_ FldngSeatPwOffOk_B_Stat : 32|1@0+ (1,0) [0|1] "SED" Vector__XXX
 SG_ EngAirFilt_B_RqReset_UB : 33|1@0+ (1,0) [0|1] "SED" Vector__XXX
 SG_ EngAirFilt_B_RqReset : 34|1@0+ (1,0) [0|1] "SED" Vector__XXX
 SG_ TrailCtl_D_Stat_UB : 49|1@0+ (1,0) [0|1] "SED" Vector__XXX
 SG_ TrailCtl_D_Stat : 52|3@0+ (1,0) [0|7] "SED" Vector__XXX
 SG_ DrLckActv_B_RqBalrr_UB : 53|1@0+ (1,0) [0|1] "SED" Vector__XXX
 SG_ DrLckActv_B_RqBalrl_UB : 54|1@0+ (1,0) [0|1] "SED" Vector__XXX
 SG_ DrLckCnt_No_ActlBalrr : 42|3@0+ (1,0) [0|7] "unitless" Vector__XXX
 SG_ DrLckCnt_No_ActlBalrl : 45|3@0+ (1,0) [0|7] "unitless" Vector__XXX
 SG_ DrLckActv_B_RqBalrr : 55|1@0+ (1,0) [0|1] "SED" Vector__XXX
 SG_ DrLckActv_B_RqBalrl : 46|1@0+ (1,0) [0|1] "SED" Vector__XXX
 SG_ EmgcyCall_D_Stat : 38|3@0+ (1,0) [0|7] "SED" Vector__XXX
 SG_ EmgcyCall_D_Stat_UB : 35|1@0+ (1,0) [0|1] "SED" Vector__XXX
 SG_ EmPrflNo_D_Rq_UB : 10|1@0+ (1,0) [0|1] "SED" Vector__XXX
 SG_ EmPrflKeyAssoc_D_Rq_UB : 11|1@0+ (1,0) [0|1] "SED" Vector__XXX
 SG_ EmPrflNo_D_Rq : 2|3@0+ (1,0) [0|7] "SED" Vector__XXX
 SG_ EmPrflKeyAssoc_D_Rq : 5|3@0+ (1,0) [0|7] "SED" Vector__XXX
 SG_ CamraViewSplit_B_Rq_UB : 6|1@0+ (1,0) [0|1] "SED" Vector__XXX
 SG_ HMI_HMIMode_St : 15|3@0+ (1,0) [0|7] "SED" Vector__XXX
 SG_ CamraViewSplit_B_Rq : 7|1@0+ (1,0) [0|1] "SED" Vector__XXX
 SG_ HMI_HMIMode_St_UB : 12|1@0+ (1,0) [0|1] "SED" Vector__XXX

CM_ BO_ 1160 "some signals from HS4 0x22A TCU_EM in CGEA1.3";
CM_ SG_ 1112 BattTracClntPmp_D_Stat "48V mHEV: ECM_HEVDSL is Tx,  MHT HEV: PCM_HEV is Tx,  Powersplit HEV: SOBDMC_HPCM is Tx";
CM_ SG_ 810 PtRmtRprt_D_Stat "Object.RemoteDataReport_St
";
CM_ SG_ 810 NtfyDrvTrgtDist_L_Rq "Object.SetTripRangeAlert_Rq
This signal is meant to provide the customer settings for the target distance remote notification";
CM_ SG_ 810 NtfyDrvSocLvl1_Pc_Rq "Object.SetCustomerLevelAlert_Rq
This signal is meant to provide the customer settings for the SOC remote notification.";
CM_ SG_ 1082 HMI_HMIMode_St "Object ACU System Master.HMIMode
OR
Object NAV System Master.HMIMode

Refer Method HMIAudioMode in the SPSS";
BA_DEF_ BO_  "FrameRouting" STRING ;
BA_DEF_ BO_  "FrameGatewayNetwork" STRING ;
BA_DEF_ BO_  "NetworkInitialization" ENUM  "No","Yes";
BA_DEF_ BO_  "FrameGatewayId" HEX 0 1407;
BA_DEF_ BO_  "EventRateOfChange" INT 10 10000;
BA_DEF_ BO_  "GenMsgNrOfRepetition" INT 0 100;
BA_DEF_ BO_  "GenMsgDelayTime" INT 0 1000;
BA_DEF_ BO_  "GenMsgCycleTime" INT 0 100000;
BA_DEF_ BO_  "GenMsgSendType" ENUM  "FixedPeriodic","Event","EnabledPeriodic","NotUsed","NotUsed","EventPeriodic","NotUsed","NotUsed","NoMsgSendType";
BA_DEF_ SG_  "U_CD764_MY2022_Tx" ENUM  "No","Yes";
BA_DEF_ SG_  "U_U55X_MY2022_Tx" ENUM  "No","Yes";
BA_DEF_ SG_  "U_CD542_MY2021_Tx" ENUM  "No","Yes";
BA_DEF_ SG_  "ECGUsedTxSignal" ENUM  "No","Yes";
BA_DEF_ SG_  "U_T6_MCA_MY2020_Tx" ENUM  "No","Yes";
BA_DEF_ SG_  "U_P702_MY2021_Tx" ENUM  "No","Yes";
BA_DEF_ SG_  "U_CX727_MY2021_Tx" ENUM  "No","Yes";
BA_DEF_ SG_  "U_CD764_MY2022_Rx" ENUM  "No","Yes";
BA_DEF_ SG_  "U_U55X_MY2022_Rx" ENUM  "No","Yes";
BA_DEF_ SG_  "U_CD542_MY2021_Rx" ENUM  "No","Yes";
BA_DEF_ SG_  "ECGUsedRxSignal" ENUM  "No","Yes";
BA_DEF_ SG_  "U_T6_MCA_MY2020_Rx" ENUM  "No","Yes";
BA_DEF_ SG_  "U_P702_MY2021_Rx" ENUM  "No","Yes";
BA_DEF_ SG_  "U_CX727_MY2021_Rx" ENUM  "No","Yes";
BA_DEF_ SG_  "GenSigStartValue" HEX 0 268435455;
BA_DEF_ SG_  "MetaData" ENUM  "No","Yes";
BA_DEF_ SG_  "ContentDependant" ENUM  "No","Yes";
BA_DEF_ SG_  "GenSigStartValueInteger" INT 0 1000000000;
BA_DEF_ SG_  "UsedOnPgmDBC" ENUM  "No","Yes";
BA_DEF_ SG_  "WakeupSignal" ENUM  "No","Yes";
BA_DEF_ SG_  "GenSigInactiveValue" INT 0 100000;
BA_DEF_ SG_  "GenSigSendType" ENUM  "Cyclic","OnWrite","vector_leerstring","OnChange","vector_leerstring","IfActive","vector_leerstring","NoSigSendType";
BA_DEF_ BO_  "SCP_FreshnessValueLength" INT 0 512;
BA_DEF_ BO_  "SCP_FreshnessValueTxLength" INT 0 512;
BA_DEF_ BO_  "SCP_AuthInfoTxLength" INT 0 512;
BA_DEF_ BO_  "NmAsrMessage" ENUM  "No","Yes";
BA_DEF_ BO_  "DiagState" ENUM  "No","Yes";
BA_DEF_ BO_  "DiagRequest" ENUM  "No","Yes";
BA_DEF_ BO_  "DiagResponse" ENUM  "No","Yes";
BA_DEF_ BO_  "GenMsgILSupport" ENUM  "No","Yes";
BA_DEF_DEF_  "FrameRouting" "";
BA_DEF_DEF_  "FrameGatewayNetwork" "NONE";
BA_DEF_DEF_  "NetworkInitialization" "Yes";
BA_DEF_DEF_  "FrameGatewayId" 0;
BA_DEF_DEF_  "EventRateOfChange" 10000;
BA_DEF_DEF_  "GenMsgNrOfRepetition" 1;
BA_DEF_DEF_  "GenMsgDelayTime" 20;
BA_DEF_DEF_  "GenMsgCycleTime" 0;
BA_DEF_DEF_  "GenMsgSendType" "NoMsgSendType";
BA_DEF_DEF_  "U_CD764_MY2022_Tx" "No";
BA_DEF_DEF_  "U_U55X_MY2022_Tx" "No";
BA_DEF_DEF_  "U_CD542_MY2021_Tx" "No";
BA_DEF_DEF_  "ECGUsedTxSignal" "No";
BA_DEF_DEF_  "U_T6_MCA_MY2020_Tx" "No";
BA_DEF_DEF_  "U_P702_MY2021_Tx" "No";
BA_DEF_DEF_  "U_CX727_MY2021_Tx" "No";
BA_DEF_DEF_  "U_CD764_MY2022_Rx" "No";
BA_DEF_DEF_  "U_U55X_MY2022_Rx" "No";
BA_DEF_DEF_  "U_CD542_MY2021_Rx" "No";
BA_DEF_DEF_  "ECGUsedRxSignal" "No";
BA_DEF_DEF_  "U_T6_MCA_MY2020_Rx" "No";
BA_DEF_DEF_  "U_P702_MY2021_Rx" "No";
BA_DEF_DEF_  "U_CX727_MY2021_Rx" "No";
BA_DEF_DEF_  "GenSigStartValue" 0;
BA_DEF_DEF_  "MetaData" "No";
BA_DEF_DEF_  "ContentDependant" "No";
BA_DEF_DEF_  "GenSigStartValueInteger" 0;
BA_DEF_DEF_  "UsedOnPgmDBC" "Yes";
BA_DEF_DEF_  "WakeupSignal" "No";
BA_DEF_DEF_  "GenSigInactiveValue" 0;
BA_DEF_DEF_  "GenSigSendType" "NoSigSendType";
BA_DEF_DEF_  "SCP_FreshnessValueLength" 64;
BA_DEF_DEF_  "SCP_FreshnessValueTxLength" 11;
BA_DEF_DEF_  "SCP_AuthInfoTxLength" 53;
BA_DEF_DEF_  "NmAsrMessage" "No";
BA_DEF_DEF_  "DiagState" "No";
BA_DEF_DEF_  "DiagRequest" "No";
BA_DEF_DEF_  "DiagResponse" "No";
BA_DEF_DEF_  "GenMsgILSupport" "Yes";
BA_ "GenMsgCycleTime" BO_ 1189 1000;
BA_ "GenMsgSendType" BO_ 1189 0;
BA_ "GenMsgCycleTime" BO_ 1188 1000;
BA_ "GenMsgSendType" BO_ 1188 0;
BA_ "GenMsgCycleTime" BO_ 1187 1000;
BA_ "GenMsgSendType" BO_ 1187 0;
BA_ "GenMsgCycleTime" BO_ 1169 1000;
BA_ "GenMsgSendType" BO_ 1169 0;
BA_ "GenMsgCycleTime" BO_ 1186 1000;
BA_ "GenMsgSendType" BO_ 1186 0;
BA_ "GenMsgCycleTime" BO_ 1185 1000;
BA_ "GenMsgSendType" BO_ 1185 0;
BA_ "GenMsgCycleTime" BO_ 1184 1000;
BA_ "GenMsgSendType" BO_ 1184 0;
BA_ "GenMsgCycleTime" BO_ 1183 1000;
BA_ "GenMsgSendType" BO_ 1183 0;
BA_ "GenMsgCycleTime" BO_ 1182 1000;
BA_ "GenMsgSendType" BO_ 1182 0;
BA_ "GenMsgCycleTime" BO_ 1181 1000;
BA_ "GenMsgSendType" BO_ 1181 0;
BA_ "GenMsgCycleTime" BO_ 1180 1000;
BA_ "GenMsgSendType" BO_ 1180 0;
BA_ "GenMsgCycleTime" BO_ 1179 1000;
BA_ "GenMsgSendType" BO_ 1179 0;
BA_ "GenMsgCycleTime" BO_ 1178 1000;
BA_ "GenMsgSendType" BO_ 1178 0;
BA_ "GenMsgCycleTime" BO_ 1177 1000;
BA_ "GenMsgSendType" BO_ 1177 0;
BA_ "GenMsgCycleTime" BO_ 1168 1000;
BA_ "GenMsgSendType" BO_ 1168 0;
BA_ "GenMsgCycleTime" BO_ 1092 1000;
BA_ "GenMsgSendType" BO_ 1092 0;
BA_ "GenMsgSendType" BO_ 646 0;
BA_ "GenMsgCycleTime" BO_ 646 100;
BA_ "FrameGatewayId" BO_ 513 513;
BA_ "FrameGatewayNetwork" BO_ 513 "FD1_CAN";
BA_ "FrameRouting" BO_ 513 "FD1_CAN,0x201;";
BA_ "GenMsgSendType" BO_ 650 5;
BA_ "GenMsgCycleTime" BO_ 650 500;
BA_ "GenMsgSendType" BO_ 655 0;
BA_ "GenMsgCycleTime" BO_ 655 500;
BA_ "GenMsgSendType" BO_ 599 5;
BA_ "GenMsgCycleTime" BO_ 599 1000;
BA_ "GenMsgSendType" BO_ 749 5;
BA_ "GenMsgCycleTime" BO_ 749 1000;
BA_ "GenMsgSendType" BO_ 580 5;
BA_ "GenMsgCycleTime" BO_ 580 1000;
BA_ "FrameGatewayId" BO_ 1012 1012;
BA_ "FrameGatewayNetwork" BO_ 1012 "FD1_CAN";
BA_ "FrameRouting" BO_ 1012 "FD1_CAN,0x3F4;";
BA_ "GenMsgSendType" BO_ 1149 0;
BA_ "GenMsgCycleTime" BO_ 1149 1000;
BA_ "GenMsgSendType" BO_ 1135 0;
BA_ "GenMsgCycleTime" BO_ 1135 100;
BA_ "FrameGatewayId" BO_ 770 770;
BA_ "FrameGatewayNetwork" BO_ 770 "FD1_CAN";
BA_ "FrameRouting" BO_ 770 "FD1_CAN,0x302;";
BA_ "GenMsgSendType" BO_ 123 0;
BA_ "GenMsgCycleTime" BO_ 123 10;
BA_ "GenMsgDelayTime" BO_ 123 0;
BA_ "GenMsgSendType" BO_ 1160 5;
BA_ "GenMsgCycleTime" BO_ 1160 1000;
BA_ "FrameRouting" BO_ 1119 "HS1_CAN,0x45F";
BA_ "FrameGatewayId" BO_ 1119 1119;
BA_ "FrameGatewayNetwork" BO_ 1119 "HS1_CAN";
BA_ "FrameGatewayId" BO_ 1152 1152;
BA_ "FrameGatewayNetwork" BO_ 1152 "FD1_CAN";
BA_ "FrameRouting" BO_ 1152 "FD1_CAN,0x480;";
BA_ "GenMsgSendType" BO_ 1118 5;
BA_ "GenMsgCycleTime" BO_ 1118 1000;
BA_ "FrameRouting" BO_ 953 "HS1_CAN,0x3B9";
BA_ "FrameGatewayId" BO_ 953 953;
BA_ "FrameGatewayNetwork" BO_ 953 "HS1_CAN";
BA_ "GenMsgSendType" BO_ 1112 5;
BA_ "GenMsgCycleTime" BO_ 1112 1000;
BA_ "FrameGatewayId" BO_ 1144 1144;
BA_ "FrameGatewayNetwork" BO_ 1144 "FD1_CAN";
BA_ "FrameRouting" BO_ 1144 "FD1_CAN,0x478;";
BA_ "GenMsgSendType" BO_ 589 0;
BA_ "GenMsgCycleTime" BO_ 589 100;
BA_ "GenMsgSendType" BO_ 1081 5;
BA_ "GenMsgCycleTime" BO_ 1081 1000;
BA_ "GenMsgSendType" BO_ 810 5;
BA_ "GenMsgCycleTime" BO_ 810 1000;
BA_ "GenMsgSendType" BO_ 1082 5;
BA_ "GenMsgCycleTime" BO_ 1082 1000;
BA_ "U_CD542_MY2021_Tx" SG_ 1189 BattTracCellUMx_No_Actl 1;
BA_ "U_CX727_MY2021_Tx" SG_ 1189 BattTracCellUMx_No_Actl 1;
BA_ "U_U55X_MY2022_Rx" SG_ 1189 BattTracCellUMx_No_Actl 1;
BA_ "U_CD542_MY2021_Rx" SG_ 1189 BattTracCellUMx_No_Actl 1;
BA_ "ECGUsedRxSignal" SG_ 1189 BattTracCellUMx_No_Actl 1;
BA_ "GenSigStartValue" SG_ 1189 BattTracCellUMx_No_Actl 254;
BA_ "GenSigStartValueInteger" SG_ 1189 BattTracCellUMx_No_Actl 254;
BA_ "U_CD542_MY2021_Tx" SG_ 1189 BattChrgUMx_B_Falt 1;
BA_ "U_CX727_MY2021_Tx" SG_ 1189 BattChrgUMx_B_Falt 1;
BA_ "U_U55X_MY2022_Rx" SG_ 1189 BattChrgUMx_B_Falt 1;
BA_ "U_CD542_MY2021_Rx" SG_ 1189 BattChrgUMx_B_Falt 1;
BA_ "ECGUsedRxSignal" SG_ 1189 BattChrgUMx_B_Falt 1;
BA_ "U_CD542_MY2021_Tx" SG_ 1189 BattTracCellUMn_No_Actl 1;
BA_ "U_CX727_MY2021_Tx" SG_ 1189 BattTracCellUMn_No_Actl 1;
BA_ "U_U55X_MY2022_Rx" SG_ 1189 BattTracCellUMn_No_Actl 1;
BA_ "U_CD542_MY2021_Rx" SG_ 1189 BattTracCellUMn_No_Actl 1;
BA_ "ECGUsedRxSignal" SG_ 1189 BattTracCellUMn_No_Actl 1;
BA_ "GenSigStartValue" SG_ 1189 BattTracCellUMn_No_Actl 254;
BA_ "GenSigStartValueInteger" SG_ 1189 BattTracCellUMn_No_Actl 254;
BA_ "U_CD542_MY2021_Tx" SG_ 1189 BattTracCellCnt_No_Actl 1;
BA_ "U_CX727_MY2021_Tx" SG_ 1189 BattTracCellCnt_No_Actl 1;
BA_ "U_U55X_MY2022_Rx" SG_ 1189 BattTracCellCnt_No_Actl 1;
BA_ "U_CD542_MY2021_Rx" SG_ 1189 BattTracCellCnt_No_Actl 1;
BA_ "ECGUsedRxSignal" SG_ 1189 BattTracCellCnt_No_Actl 1;
BA_ "GenSigStartValue" SG_ 1189 BattTracCellCnt_No_Actl 254;
BA_ "GenSigStartValueInteger" SG_ 1189 BattTracCellCnt_No_Actl 254;
BA_ "U_CD542_MY2021_Tx" SG_ 1189 BattTracCellDiff_B_Falt 1;
BA_ "U_CX727_MY2021_Tx" SG_ 1189 BattTracCellDiff_B_Falt 1;
BA_ "U_U55X_MY2022_Rx" SG_ 1189 BattTracCellDiff_B_Falt 1;
BA_ "U_CD542_MY2021_Rx" SG_ 1189 BattTracCellDiff_B_Falt 1;
BA_ "ECGUsedRxSignal" SG_ 1189 BattTracCellDiff_B_Falt 1;
BA_ "U_CD542_MY2021_Tx" SG_ 1189 BattChrgSocMx_B_Falt 1;
BA_ "U_CX727_MY2021_Tx" SG_ 1189 BattChrgSocMx_B_Falt 1;
BA_ "U_U55X_MY2022_Rx" SG_ 1189 BattChrgSocMx_B_Falt 1;
BA_ "U_CD542_MY2021_Rx" SG_ 1189 BattChrgSocMx_B_Falt 1;
BA_ "ECGUsedRxSignal" SG_ 1189 BattChrgSocMx_B_Falt 1;
BA_ "U_CD542_MY2021_Tx" SG_ 1189 BattChrgSocMn_B_Falt 1;
BA_ "U_CX727_MY2021_Tx" SG_ 1189 BattChrgSocMn_B_Falt 1;
BA_ "U_U55X_MY2022_Rx" SG_ 1189 BattChrgSocMn_B_Falt 1;
BA_ "U_CD542_MY2021_Rx" SG_ 1189 BattChrgSocMn_B_Falt 1;
BA_ "ECGUsedRxSignal" SG_ 1189 BattChrgSocMn_B_Falt 1;
BA_ "U_CD542_MY2021_Tx" SG_ 1189 BattChrgSocErrtc_B_Falt 1;
BA_ "U_CX727_MY2021_Tx" SG_ 1189 BattChrgSocErrtc_B_Falt 1;
BA_ "U_U55X_MY2022_Rx" SG_ 1189 BattChrgSocErrtc_B_Falt 1;
BA_ "U_CD542_MY2021_Rx" SG_ 1189 BattChrgSocErrtc_B_Falt 1;
BA_ "ECGUsedRxSignal" SG_ 1189 BattChrgSocErrtc_B_Falt 1;
BA_ "U_CD542_MY2021_Tx" SG_ 1189 BattTracUMx_B_Falt 1;
BA_ "U_CX727_MY2021_Tx" SG_ 1189 BattTracUMx_B_Falt 1;
BA_ "U_U55X_MY2022_Rx" SG_ 1189 BattTracUMx_B_Falt 1;
BA_ "U_CD542_MY2021_Rx" SG_ 1189 BattTracUMx_B_Falt 1;
BA_ "ECGUsedRxSignal" SG_ 1189 BattTracUMx_B_Falt 1;
BA_ "U_CD542_MY2021_Tx" SG_ 1189 BattTracUMn_B_Falt 1;
BA_ "U_CX727_MY2021_Tx" SG_ 1189 BattTracUMn_B_Falt 1;
BA_ "U_U55X_MY2022_Rx" SG_ 1189 BattTracUMn_B_Falt 1;
BA_ "U_CD542_MY2021_Rx" SG_ 1189 BattTracUMn_B_Falt 1;
BA_ "ECGUsedRxSignal" SG_ 1189 BattTracUMn_B_Falt 1;
BA_ "U_CD542_MY2021_Tx" SG_ 1189 BattTracTeMx_No_Actl 1;
BA_ "U_CX727_MY2021_Tx" SG_ 1189 BattTracTeMx_No_Actl 1;
BA_ "U_U55X_MY2022_Rx" SG_ 1189 BattTracTeMx_No_Actl 1;
BA_ "U_CD542_MY2021_Rx" SG_ 1189 BattTracTeMx_No_Actl 1;
BA_ "ECGUsedRxSignal" SG_ 1189 BattTracTeMx_No_Actl 1;
BA_ "GenSigStartValue" SG_ 1189 BattTracTeMx_No_Actl 254;
BA_ "GenSigStartValueInteger" SG_ 1189 BattTracTeMx_No_Actl 254;
BA_ "U_CD542_MY2021_Tx" SG_ 1189 BattTracTeMx_B_Falt 1;
BA_ "U_CX727_MY2021_Tx" SG_ 1189 BattTracTeMx_B_Falt 1;
BA_ "U_U55X_MY2022_Rx" SG_ 1189 BattTracTeMx_B_Falt 1;
BA_ "U_CD542_MY2021_Rx" SG_ 1189 BattTracTeMx_B_Falt 1;
BA_ "ECGUsedRxSignal" SG_ 1189 BattTracTeMx_B_Falt 1;
BA_ "U_CD542_MY2021_Tx" SG_ 1189 BattTracTeMn_No_Actl 1;
BA_ "U_CX727_MY2021_Tx" SG_ 1189 BattTracTeMn_No_Actl 1;
BA_ "U_U55X_MY2022_Rx" SG_ 1189 BattTracTeMn_No_Actl 1;
BA_ "U_CD542_MY2021_Rx" SG_ 1189 BattTracTeMn_No_Actl 1;
BA_ "ECGUsedRxSignal" SG_ 1189 BattTracTeMn_No_Actl 1;
BA_ "GenSigStartValue" SG_ 1189 BattTracTeMn_No_Actl 254;
BA_ "GenSigStartValueInteger" SG_ 1189 BattTracTeMn_No_Actl 254;
BA_ "U_CD542_MY2021_Tx" SG_ 1189 BattTracTeDelta_B_Falt 1;
BA_ "U_CX727_MY2021_Tx" SG_ 1189 BattTracTeDelta_B_Falt 1;
BA_ "U_U55X_MY2022_Rx" SG_ 1189 BattTracTeDelta_B_Falt 1;
BA_ "U_CD542_MY2021_Rx" SG_ 1189 BattTracTeDelta_B_Falt 1;
BA_ "ECGUsedRxSignal" SG_ 1189 BattTracTeDelta_B_Falt 1;
BA_ "U_CD542_MY2021_Tx" SG_ 1189 BattTracTeCnt_No_Actl 1;
BA_ "U_CX727_MY2021_Tx" SG_ 1189 BattTracTeCnt_No_Actl 1;
BA_ "U_U55X_MY2022_Rx" SG_ 1189 BattTracTeCnt_No_Actl 1;
BA_ "U_CD542_MY2021_Rx" SG_ 1189 BattTracTeCnt_No_Actl 1;
BA_ "ECGUsedRxSignal" SG_ 1189 BattTracTeCnt_No_Actl 1;
BA_ "GenSigStartValue" SG_ 1189 BattTracTeCnt_No_Actl 254;
BA_ "GenSigStartValueInteger" SG_ 1189 BattTracTeCnt_No_Actl 254;
BA_ "U_CD542_MY2021_Tx" SG_ 1189 BattTracSoftware_B_Falt 1;
BA_ "U_CX727_MY2021_Tx" SG_ 1189 BattTracSoftware_B_Falt 1;
BA_ "U_U55X_MY2022_Rx" SG_ 1189 BattTracSoftware_B_Falt 1;
BA_ "U_CD542_MY2021_Rx" SG_ 1189 BattTracSoftware_B_Falt 1;
BA_ "ECGUsedRxSignal" SG_ 1189 BattTracSoftware_B_Falt 1;
BA_ "U_CD542_MY2021_Tx" SG_ 1188 BattTracTe13_Te_Actl 1;
BA_ "U_CX727_MY2021_Tx" SG_ 1188 BattTracTe13_Te_Actl 1;
BA_ "U_U55X_MY2022_Rx" SG_ 1188 BattTracTe13_Te_Actl 1;
BA_ "U_CD542_MY2021_Rx" SG_ 1188 BattTracTe13_Te_Actl 1;
BA_ "ECGUsedRxSignal" SG_ 1188 BattTracTe13_Te_Actl 1;
BA_ "GenSigStartValue" SG_ 1188 BattTracTe13_Te_Actl 254;
BA_ "GenSigStartValueInteger" SG_ 1188 BattTracTe13_Te_Actl 254;
BA_ "U_CD542_MY2021_Tx" SG_ 1188 BattTracTe12_Te_Actl 1;
BA_ "U_CX727_MY2021_Tx" SG_ 1188 BattTracTe12_Te_Actl 1;
BA_ "U_U55X_MY2022_Rx" SG_ 1188 BattTracTe12_Te_Actl 1;
BA_ "U_CD542_MY2021_Rx" SG_ 1188 BattTracTe12_Te_Actl 1;
BA_ "ECGUsedRxSignal" SG_ 1188 BattTracTe12_Te_Actl 1;
BA_ "GenSigStartValue" SG_ 1188 BattTracTe12_Te_Actl 254;
BA_ "GenSigStartValueInteger" SG_ 1188 BattTracTe12_Te_Actl 254;
BA_ "U_CD542_MY2021_Tx" SG_ 1188 BattTracTe11_Te_Actl 1;
BA_ "U_CX727_MY2021_Tx" SG_ 1188 BattTracTe11_Te_Actl 1;
BA_ "U_U55X_MY2022_Rx" SG_ 1188 BattTracTe11_Te_Actl 1;
BA_ "U_CD542_MY2021_Rx" SG_ 1188 BattTracTe11_Te_Actl 1;
BA_ "ECGUsedRxSignal" SG_ 1188 BattTracTe11_Te_Actl 1;
BA_ "GenSigStartValue" SG_ 1188 BattTracTe11_Te_Actl 254;
BA_ "GenSigStartValueInteger" SG_ 1188 BattTracTe11_Te_Actl 254;
BA_ "U_CD542_MY2021_Tx" SG_ 1188 BattTracTe10_Te_Actl 1;
BA_ "U_CX727_MY2021_Tx" SG_ 1188 BattTracTe10_Te_Actl 1;
BA_ "U_U55X_MY2022_Rx" SG_ 1188 BattTracTe10_Te_Actl 1;
BA_ "U_CD542_MY2021_Rx" SG_ 1188 BattTracTe10_Te_Actl 1;
BA_ "ECGUsedRxSignal" SG_ 1188 BattTracTe10_Te_Actl 1;
BA_ "GenSigStartValue" SG_ 1188 BattTracTe10_Te_Actl 254;
BA_ "GenSigStartValueInteger" SG_ 1188 BattTracTe10_Te_Actl 254;
BA_ "U_CD542_MY2021_Tx" SG_ 1188 BattTracTe09_Te_Actl 1;
BA_ "U_CX727_MY2021_Tx" SG_ 1188 BattTracTe09_Te_Actl 1;
BA_ "U_U55X_MY2022_Rx" SG_ 1188 BattTracTe09_Te_Actl 1;
BA_ "U_CD542_MY2021_Rx" SG_ 1188 BattTracTe09_Te_Actl 1;
BA_ "ECGUsedRxSignal" SG_ 1188 BattTracTe09_Te_Actl 1;
BA_ "GenSigStartValue" SG_ 1188 BattTracTe09_Te_Actl 254;
BA_ "GenSigStartValueInteger" SG_ 1188 BattTracTe09_Te_Actl 254;
BA_ "U_CD542_MY2021_Tx" SG_ 1188 BattTracTe08_Te_Actl 1;
BA_ "U_CX727_MY2021_Tx" SG_ 1188 BattTracTe08_Te_Actl 1;
BA_ "U_U55X_MY2022_Rx" SG_ 1188 BattTracTe08_Te_Actl 1;
BA_ "U_CD542_MY2021_Rx" SG_ 1188 BattTracTe08_Te_Actl 1;
BA_ "ECGUsedRxSignal" SG_ 1188 BattTracTe08_Te_Actl 1;
BA_ "GenSigStartValue" SG_ 1188 BattTracTe08_Te_Actl 254;
BA_ "GenSigStartValueInteger" SG_ 1188 BattTracTe08_Te_Actl 254;
BA_ "U_CD542_MY2021_Tx" SG_ 1188 BattTracTe07_Te_Actl 1;
BA_ "U_CX727_MY2021_Tx" SG_ 1188 BattTracTe07_Te_Actl 1;
BA_ "U_U55X_MY2022_Rx" SG_ 1188 BattTracTe07_Te_Actl 1;
BA_ "U_CD542_MY2021_Rx" SG_ 1188 BattTracTe07_Te_Actl 1;
BA_ "ECGUsedRxSignal" SG_ 1188 BattTracTe07_Te_Actl 1;
BA_ "GenSigStartValue" SG_ 1188 BattTracTe07_Te_Actl 254;
BA_ "GenSigStartValueInteger" SG_ 1188 BattTracTe07_Te_Actl 254;
BA_ "U_CD542_MY2021_Tx" SG_ 1187 BattTracTe06_Te_Actl 1;
BA_ "U_CX727_MY2021_Tx" SG_ 1187 BattTracTe06_Te_Actl 1;
BA_ "U_U55X_MY2022_Rx" SG_ 1187 BattTracTe06_Te_Actl 1;
BA_ "U_CD542_MY2021_Rx" SG_ 1187 BattTracTe06_Te_Actl 1;
BA_ "ECGUsedRxSignal" SG_ 1187 BattTracTe06_Te_Actl 1;
BA_ "GenSigStartValue" SG_ 1187 BattTracTe06_Te_Actl 254;
BA_ "GenSigStartValueInteger" SG_ 1187 BattTracTe06_Te_Actl 254;
BA_ "U_CD542_MY2021_Tx" SG_ 1187 BattTracTe05_Te_Actl 1;
BA_ "U_CX727_MY2021_Tx" SG_ 1187 BattTracTe05_Te_Actl 1;
BA_ "U_U55X_MY2022_Rx" SG_ 1187 BattTracTe05_Te_Actl 1;
BA_ "U_CD542_MY2021_Rx" SG_ 1187 BattTracTe05_Te_Actl 1;
BA_ "ECGUsedRxSignal" SG_ 1187 BattTracTe05_Te_Actl 1;
BA_ "GenSigStartValue" SG_ 1187 BattTracTe05_Te_Actl 254;
BA_ "GenSigStartValueInteger" SG_ 1187 BattTracTe05_Te_Actl 254;
BA_ "U_CD542_MY2021_Tx" SG_ 1187 BattTracTe04_Te_Actl 1;
BA_ "U_CX727_MY2021_Tx" SG_ 1187 BattTracTe04_Te_Actl 1;
BA_ "U_U55X_MY2022_Rx" SG_ 1187 BattTracTe04_Te_Actl 1;
BA_ "U_CD542_MY2021_Rx" SG_ 1187 BattTracTe04_Te_Actl 1;
BA_ "ECGUsedRxSignal" SG_ 1187 BattTracTe04_Te_Actl 1;
BA_ "GenSigStartValue" SG_ 1187 BattTracTe04_Te_Actl 254;
BA_ "GenSigStartValueInteger" SG_ 1187 BattTracTe04_Te_Actl 254;
BA_ "U_CD542_MY2021_Tx" SG_ 1187 BattTracTe03_Te_Actl 1;
BA_ "U_CX727_MY2021_Tx" SG_ 1187 BattTracTe03_Te_Actl 1;
BA_ "U_U55X_MY2022_Rx" SG_ 1187 BattTracTe03_Te_Actl 1;
BA_ "U_CD542_MY2021_Rx" SG_ 1187 BattTracTe03_Te_Actl 1;
BA_ "ECGUsedRxSignal" SG_ 1187 BattTracTe03_Te_Actl 1;
BA_ "GenSigStartValue" SG_ 1187 BattTracTe03_Te_Actl 254;
BA_ "GenSigStartValueInteger" SG_ 1187 BattTracTe03_Te_Actl 254;
BA_ "U_CD542_MY2021_Tx" SG_ 1187 BattTracTe02_Te_Actl 1;
BA_ "U_CX727_MY2021_Tx" SG_ 1187 BattTracTe02_Te_Actl 1;
BA_ "U_U55X_MY2022_Rx" SG_ 1187 BattTracTe02_Te_Actl 1;
BA_ "U_CD542_MY2021_Rx" SG_ 1187 BattTracTe02_Te_Actl 1;
BA_ "ECGUsedRxSignal" SG_ 1187 BattTracTe02_Te_Actl 1;
BA_ "GenSigStartValue" SG_ 1187 BattTracTe02_Te_Actl 254;
BA_ "GenSigStartValueInteger" SG_ 1187 BattTracTe02_Te_Actl 254;
BA_ "U_CD542_MY2021_Tx" SG_ 1187 BattTracTe01_Te_Actl 1;
BA_ "U_CX727_MY2021_Tx" SG_ 1187 BattTracTe01_Te_Actl 1;
BA_ "U_U55X_MY2022_Rx" SG_ 1187 BattTracTe01_Te_Actl 1;
BA_ "U_CD542_MY2021_Rx" SG_ 1187 BattTracTe01_Te_Actl 1;
BA_ "ECGUsedRxSignal" SG_ 1187 BattTracTe01_Te_Actl 1;
BA_ "GenSigStartValue" SG_ 1187 BattTracTe01_Te_Actl 254;
BA_ "GenSigStartValueInteger" SG_ 1187 BattTracTe01_Te_Actl 254;
BA_ "U_CD542_MY2021_Tx" SG_ 1187 BattTracCell96_U_Actl 1;
BA_ "U_CX727_MY2021_Tx" SG_ 1187 BattTracCell96_U_Actl 1;
BA_ "U_U55X_MY2022_Rx" SG_ 1187 BattTracCell96_U_Actl 1;
BA_ "U_CD542_MY2021_Rx" SG_ 1187 BattTracCell96_U_Actl 1;
BA_ "ECGUsedRxSignal" SG_ 1187 BattTracCell96_U_Actl 1;
BA_ "GenSigStartValue" SG_ 1187 BattTracCell96_U_Actl 4094;
BA_ "GenSigStartValueInteger" SG_ 1187 BattTracCell96_U_Actl 4094;
BA_ "U_CD542_MY2021_Tx" SG_ 1169 BattTracCell10_U_Actl 1;
BA_ "U_CX727_MY2021_Tx" SG_ 1169 BattTracCell10_U_Actl 1;
BA_ "U_U55X_MY2022_Rx" SG_ 1169 BattTracCell10_U_Actl 1;
BA_ "U_CD542_MY2021_Rx" SG_ 1169 BattTracCell10_U_Actl 1;
BA_ "ECGUsedRxSignal" SG_ 1169 BattTracCell10_U_Actl 1;
BA_ "GenSigStartValue" SG_ 1169 BattTracCell10_U_Actl 4094;
BA_ "GenSigStartValueInteger" SG_ 1169 BattTracCell10_U_Actl 4094;
BA_ "U_CD542_MY2021_Tx" SG_ 1169 BattTracCell09_U_Actl 1;
BA_ "U_CX727_MY2021_Tx" SG_ 1169 BattTracCell09_U_Actl 1;
BA_ "U_U55X_MY2022_Rx" SG_ 1169 BattTracCell09_U_Actl 1;
BA_ "U_CD542_MY2021_Rx" SG_ 1169 BattTracCell09_U_Actl 1;
BA_ "ECGUsedRxSignal" SG_ 1169 BattTracCell09_U_Actl 1;
BA_ "GenSigStartValue" SG_ 1169 BattTracCell09_U_Actl 4094;
BA_ "GenSigStartValueInteger" SG_ 1169 BattTracCell09_U_Actl 4094;
BA_ "U_CD542_MY2021_Tx" SG_ 1169 BattTracCell08_U_Actl 1;
BA_ "U_CX727_MY2021_Tx" SG_ 1169 BattTracCell08_U_Actl 1;
BA_ "U_U55X_MY2022_Rx" SG_ 1169 BattTracCell08_U_Actl 1;
BA_ "U_CD542_MY2021_Rx" SG_ 1169 BattTracCell08_U_Actl 1;
BA_ "ECGUsedRxSignal" SG_ 1169 BattTracCell08_U_Actl 1;
BA_ "GenSigStartValue" SG_ 1169 BattTracCell08_U_Actl 4094;
BA_ "GenSigStartValueInteger" SG_ 1169 BattTracCell08_U_Actl 4094;
BA_ "U_CD542_MY2021_Tx" SG_ 1169 BattTracCell07_U_Actl 1;
BA_ "U_CX727_MY2021_Tx" SG_ 1169 BattTracCell07_U_Actl 1;
BA_ "U_U55X_MY2022_Rx" SG_ 1169 BattTracCell07_U_Actl 1;
BA_ "U_CD542_MY2021_Rx" SG_ 1169 BattTracCell07_U_Actl 1;
BA_ "ECGUsedRxSignal" SG_ 1169 BattTracCell07_U_Actl 1;
BA_ "GenSigStartValue" SG_ 1169 BattTracCell07_U_Actl 4094;
BA_ "GenSigStartValueInteger" SG_ 1169 BattTracCell07_U_Actl 4094;
BA_ "U_CD542_MY2021_Tx" SG_ 1169 BattTracCell06_U_Actl 1;
BA_ "U_CX727_MY2021_Tx" SG_ 1169 BattTracCell06_U_Actl 1;
BA_ "U_U55X_MY2022_Rx" SG_ 1169 BattTracCell06_U_Actl 1;
BA_ "U_CD542_MY2021_Rx" SG_ 1169 BattTracCell06_U_Actl 1;
BA_ "ECGUsedRxSignal" SG_ 1169 BattTracCell06_U_Actl 1;
BA_ "GenSigStartValue" SG_ 1169 BattTracCell06_U_Actl 4094;
BA_ "GenSigStartValueInteger" SG_ 1169 BattTracCell06_U_Actl 4094;
BA_ "U_CD542_MY2021_Tx" SG_ 1186 BattTracCell95_U_Actl 1;
BA_ "U_CX727_MY2021_Tx" SG_ 1186 BattTracCell95_U_Actl 1;
BA_ "U_U55X_MY2022_Rx" SG_ 1186 BattTracCell95_U_Actl 1;
BA_ "U_CD542_MY2021_Rx" SG_ 1186 BattTracCell95_U_Actl 1;
BA_ "ECGUsedRxSignal" SG_ 1186 BattTracCell95_U_Actl 1;
BA_ "GenSigStartValue" SG_ 1186 BattTracCell95_U_Actl 4094;
BA_ "GenSigStartValueInteger" SG_ 1186 BattTracCell95_U_Actl 4094;
BA_ "U_CD542_MY2021_Tx" SG_ 1186 BattTracCell94_U_Actl 1;
BA_ "U_CX727_MY2021_Tx" SG_ 1186 BattTracCell94_U_Actl 1;
BA_ "U_U55X_MY2022_Rx" SG_ 1186 BattTracCell94_U_Actl 1;
BA_ "U_CD542_MY2021_Rx" SG_ 1186 BattTracCell94_U_Actl 1;
BA_ "ECGUsedRxSignal" SG_ 1186 BattTracCell94_U_Actl 1;
BA_ "GenSigStartValue" SG_ 1186 BattTracCell94_U_Actl 4094;
BA_ "GenSigStartValueInteger" SG_ 1186 BattTracCell94_U_Actl 4094;
BA_ "U_CD542_MY2021_Tx" SG_ 1186 BattTracCell93_U_Actl 1;
BA_ "U_CX727_MY2021_Tx" SG_ 1186 BattTracCell93_U_Actl 1;
BA_ "U_U55X_MY2022_Rx" SG_ 1186 BattTracCell93_U_Actl 1;
BA_ "U_CD542_MY2021_Rx" SG_ 1186 BattTracCell93_U_Actl 1;
BA_ "ECGUsedRxSignal" SG_ 1186 BattTracCell93_U_Actl 1;
BA_ "GenSigStartValue" SG_ 1186 BattTracCell93_U_Actl 4094;
BA_ "GenSigStartValueInteger" SG_ 1186 BattTracCell93_U_Actl 4094;
BA_ "U_CD542_MY2021_Tx" SG_ 1186 BattTracCell92_U_Actl 1;
BA_ "U_CX727_MY2021_Tx" SG_ 1186 BattTracCell92_U_Actl 1;
BA_ "U_U55X_MY2022_Rx" SG_ 1186 BattTracCell92_U_Actl 1;
BA_ "U_CD542_MY2021_Rx" SG_ 1186 BattTracCell92_U_Actl 1;
BA_ "ECGUsedRxSignal" SG_ 1186 BattTracCell92_U_Actl 1;
BA_ "GenSigStartValue" SG_ 1186 BattTracCell92_U_Actl 4094;
BA_ "GenSigStartValueInteger" SG_ 1186 BattTracCell92_U_Actl 4094;
BA_ "U_CD542_MY2021_Tx" SG_ 1186 BattTracCell91_U_Actl 1;
BA_ "U_CX727_MY2021_Tx" SG_ 1186 BattTracCell91_U_Actl 1;
BA_ "U_U55X_MY2022_Rx" SG_ 1186 BattTracCell91_U_Actl 1;
BA_ "U_CD542_MY2021_Rx" SG_ 1186 BattTracCell91_U_Actl 1;
BA_ "ECGUsedRxSignal" SG_ 1186 BattTracCell91_U_Actl 1;
BA_ "GenSigStartValue" SG_ 1186 BattTracCell91_U_Actl 4094;
BA_ "GenSigStartValueInteger" SG_ 1186 BattTracCell91_U_Actl 4094;
BA_ "U_CD542_MY2021_Tx" SG_ 1185 BattTracCell90_U_Actl 1;
BA_ "U_CX727_MY2021_Tx" SG_ 1185 BattTracCell90_U_Actl 1;
BA_ "U_U55X_MY2022_Rx" SG_ 1185 BattTracCell90_U_Actl 1;
BA_ "U_CD542_MY2021_Rx" SG_ 1185 BattTracCell90_U_Actl 1;
BA_ "ECGUsedRxSignal" SG_ 1185 BattTracCell90_U_Actl 1;
BA_ "GenSigStartValue" SG_ 1185 BattTracCell90_U_Actl 4094;
BA_ "GenSigStartValueInteger" SG_ 1185 BattTracCell90_U_Actl 4094;
BA_ "U_CD542_MY2021_Tx" SG_ 1185 BattTracCell89_U_Actl 1;
BA_ "U_CX727_MY2021_Tx" SG_ 1185 BattTracCell89_U_Actl 1;
BA_ "U_U55X_MY2022_Rx" SG_ 1185 BattTracCell89_U_Actl 1;
BA_ "U_CD542_MY2021_Rx" SG_ 1185 BattTracCell89_U_Actl 1;
BA_ "ECGUsedRxSignal" SG_ 1185 BattTracCell89_U_Actl 1;
BA_ "GenSigStartValue" SG_ 1185 BattTracCell89_U_Actl 4094;
BA_ "GenSigStartValueInteger" SG_ 1185 BattTracCell89_U_Actl 4094;
BA_ "U_CD542_MY2021_Tx" SG_ 1185 BattTracCell88_U_Actl 1;
BA_ "U_CX727_MY2021_Tx" SG_ 1185 BattTracCell88_U_Actl 1;
BA_ "U_U55X_MY2022_Rx" SG_ 1185 BattTracCell88_U_Actl 1;
BA_ "U_CD542_MY2021_Rx" SG_ 1185 BattTracCell88_U_Actl 1;
BA_ "ECGUsedRxSignal" SG_ 1185 BattTracCell88_U_Actl 1;
BA_ "GenSigStartValue" SG_ 1185 BattTracCell88_U_Actl 4094;
BA_ "GenSigStartValueInteger" SG_ 1185 BattTracCell88_U_Actl 4094;
BA_ "U_CD542_MY2021_Tx" SG_ 1185 BattTracCell87_U_Actl 1;
BA_ "U_CX727_MY2021_Tx" SG_ 1185 BattTracCell87_U_Actl 1;
BA_ "U_U55X_MY2022_Rx" SG_ 1185 BattTracCell87_U_Actl 1;
BA_ "U_CD542_MY2021_Rx" SG_ 1185 BattTracCell87_U_Actl 1;
BA_ "ECGUsedRxSignal" SG_ 1185 BattTracCell87_U_Actl 1;
BA_ "GenSigStartValue" SG_ 1185 BattTracCell87_U_Actl 4094;
BA_ "GenSigStartValueInteger" SG_ 1185 BattTracCell87_U_Actl 4094;
BA_ "U_CD542_MY2021_Tx" SG_ 1185 BattTracCell86_U_Actl 1;
BA_ "U_CX727_MY2021_Tx" SG_ 1185 BattTracCell86_U_Actl 1;
BA_ "U_U55X_MY2022_Rx" SG_ 1185 BattTracCell86_U_Actl 1;
BA_ "U_CD542_MY2021_Rx" SG_ 1185 BattTracCell86_U_Actl 1;
BA_ "ECGUsedRxSignal" SG_ 1185 BattTracCell86_U_Actl 1;
BA_ "GenSigStartValue" SG_ 1185 BattTracCell86_U_Actl 4094;
BA_ "GenSigStartValueInteger" SG_ 1185 BattTracCell86_U_Actl 4094;
BA_ "U_CD542_MY2021_Tx" SG_ 1184 BattTracCell85_U_Actl 1;
BA_ "U_CX727_MY2021_Tx" SG_ 1184 BattTracCell85_U_Actl 1;
BA_ "U_U55X_MY2022_Rx" SG_ 1184 BattTracCell85_U_Actl 1;
BA_ "U_CD542_MY2021_Rx" SG_ 1184 BattTracCell85_U_Actl 1;
BA_ "ECGUsedRxSignal" SG_ 1184 BattTracCell85_U_Actl 1;
BA_ "GenSigStartValue" SG_ 1184 BattTracCell85_U_Actl 4094;
BA_ "GenSigStartValueInteger" SG_ 1184 BattTracCell85_U_Actl 4094;
BA_ "U_CD542_MY2021_Tx" SG_ 1184 BattTracCell84_U_Actl 1;
BA_ "U_CX727_MY2021_Tx" SG_ 1184 BattTracCell84_U_Actl 1;
BA_ "U_U55X_MY2022_Rx" SG_ 1184 BattTracCell84_U_Actl 1;
BA_ "U_CD542_MY2021_Rx" SG_ 1184 BattTracCell84_U_Actl 1;
BA_ "ECGUsedRxSignal" SG_ 1184 BattTracCell84_U_Actl 1;
BA_ "GenSigStartValue" SG_ 1184 BattTracCell84_U_Actl 4094;
BA_ "GenSigStartValueInteger" SG_ 1184 BattTracCell84_U_Actl 4094;
BA_ "U_CD542_MY2021_Tx" SG_ 1184 BattTracCell83_U_Actl 1;
BA_ "U_CX727_MY2021_Tx" SG_ 1184 BattTracCell83_U_Actl 1;
BA_ "U_U55X_MY2022_Rx" SG_ 1184 BattTracCell83_U_Actl 1;
BA_ "U_CD542_MY2021_Rx" SG_ 1184 BattTracCell83_U_Actl 1;
BA_ "ECGUsedRxSignal" SG_ 1184 BattTracCell83_U_Actl 1;
BA_ "GenSigStartValue" SG_ 1184 BattTracCell83_U_Actl 4094;
BA_ "GenSigStartValueInteger" SG_ 1184 BattTracCell83_U_Actl 4094;
BA_ "U_CD542_MY2021_Tx" SG_ 1184 BattTracCell82_U_Actl 1;
BA_ "U_CX727_MY2021_Tx" SG_ 1184 BattTracCell82_U_Actl 1;
BA_ "U_U55X_MY2022_Rx" SG_ 1184 BattTracCell82_U_Actl 1;
BA_ "U_CD542_MY2021_Rx" SG_ 1184 BattTracCell82_U_Actl 1;
BA_ "ECGUsedRxSignal" SG_ 1184 BattTracCell82_U_Actl 1;
BA_ "GenSigStartValue" SG_ 1184 BattTracCell82_U_Actl 4094;
BA_ "GenSigStartValueInteger" SG_ 1184 BattTracCell82_U_Actl 4094;
BA_ "U_CD542_MY2021_Tx" SG_ 1184 BattTracCell81_U_Actl 1;
BA_ "U_CX727_MY2021_Tx" SG_ 1184 BattTracCell81_U_Actl 1;
BA_ "U_U55X_MY2022_Rx" SG_ 1184 BattTracCell81_U_Actl 1;
BA_ "U_CD542_MY2021_Rx" SG_ 1184 BattTracCell81_U_Actl 1;
BA_ "ECGUsedRxSignal" SG_ 1184 BattTracCell81_U_Actl 1;
BA_ "GenSigStartValue" SG_ 1184 BattTracCell81_U_Actl 4094;
BA_ "GenSigStartValueInteger" SG_ 1184 BattTracCell81_U_Actl 4094;
BA_ "U_CD542_MY2021_Tx" SG_ 1183 BattTracCell80_U_Actl 1;
BA_ "U_CX727_MY2021_Tx" SG_ 1183 BattTracCell80_U_Actl 1;
BA_ "U_U55X_MY2022_Rx" SG_ 1183 BattTracCell80_U_Actl 1;
BA_ "U_CD542_MY2021_Rx" SG_ 1183 BattTracCell80_U_Actl 1;
BA_ "ECGUsedRxSignal" SG_ 1183 BattTracCell80_U_Actl 1;
BA_ "GenSigStartValue" SG_ 1183 BattTracCell80_U_Actl 4094;
BA_ "GenSigStartValueInteger" SG_ 1183 BattTracCell80_U_Actl 4094;
BA_ "U_CD542_MY2021_Tx" SG_ 1183 BattTracCell79_U_Actl 1;
BA_ "U_CX727_MY2021_Tx" SG_ 1183 BattTracCell79_U_Actl 1;
BA_ "U_U55X_MY2022_Rx" SG_ 1183 BattTracCell79_U_Actl 1;
BA_ "U_CD542_MY2021_Rx" SG_ 1183 BattTracCell79_U_Actl 1;
BA_ "ECGUsedRxSignal" SG_ 1183 BattTracCell79_U_Actl 1;
BA_ "GenSigStartValue" SG_ 1183 BattTracCell79_U_Actl 4094;
BA_ "GenSigStartValueInteger" SG_ 1183 BattTracCell79_U_Actl 4094;
BA_ "U_CD542_MY2021_Tx" SG_ 1183 BattTracCell78_U_Actl 1;
BA_ "U_CX727_MY2021_Tx" SG_ 1183 BattTracCell78_U_Actl 1;
BA_ "U_U55X_MY2022_Rx" SG_ 1183 BattTracCell78_U_Actl 1;
BA_ "U_CD542_MY2021_Rx" SG_ 1183 BattTracCell78_U_Actl 1;
BA_ "ECGUsedRxSignal" SG_ 1183 BattTracCell78_U_Actl 1;
BA_ "GenSigStartValue" SG_ 1183 BattTracCell78_U_Actl 4094;
BA_ "GenSigStartValueInteger" SG_ 1183 BattTracCell78_U_Actl 4094;
BA_ "U_CD542_MY2021_Tx" SG_ 1183 BattTracCell77_U_Actl 1;
BA_ "U_CX727_MY2021_Tx" SG_ 1183 BattTracCell77_U_Actl 1;
BA_ "U_U55X_MY2022_Rx" SG_ 1183 BattTracCell77_U_Actl 1;
BA_ "U_CD542_MY2021_Rx" SG_ 1183 BattTracCell77_U_Actl 1;
BA_ "ECGUsedRxSignal" SG_ 1183 BattTracCell77_U_Actl 1;
BA_ "GenSigStartValue" SG_ 1183 BattTracCell77_U_Actl 4094;
BA_ "GenSigStartValueInteger" SG_ 1183 BattTracCell77_U_Actl 4094;
BA_ "U_CD542_MY2021_Tx" SG_ 1183 BattTracCell76_U_Actl 1;
BA_ "U_CX727_MY2021_Tx" SG_ 1183 BattTracCell76_U_Actl 1;
BA_ "U_U55X_MY2022_Rx" SG_ 1183 BattTracCell76_U_Actl 1;
BA_ "U_CD542_MY2021_Rx" SG_ 1183 BattTracCell76_U_Actl 1;
BA_ "ECGUsedRxSignal" SG_ 1183 BattTracCell76_U_Actl 1;
BA_ "GenSigStartValue" SG_ 1183 BattTracCell76_U_Actl 4094;
BA_ "GenSigStartValueInteger" SG_ 1183 BattTracCell76_U_Actl 4094;
BA_ "U_CD542_MY2021_Tx" SG_ 1182 BattTracCell75_U_Actl 1;
BA_ "U_CX727_MY2021_Tx" SG_ 1182 BattTracCell75_U_Actl 1;
BA_ "U_U55X_MY2022_Rx" SG_ 1182 BattTracCell75_U_Actl 1;
BA_ "U_CD542_MY2021_Rx" SG_ 1182 BattTracCell75_U_Actl 1;
BA_ "ECGUsedRxSignal" SG_ 1182 BattTracCell75_U_Actl 1;
BA_ "GenSigStartValue" SG_ 1182 BattTracCell75_U_Actl 4094;
BA_ "GenSigStartValueInteger" SG_ 1182 BattTracCell75_U_Actl 4094;
BA_ "U_CD542_MY2021_Tx" SG_ 1182 BattTracCell74_U_Actl 1;
BA_ "U_CX727_MY2021_Tx" SG_ 1182 BattTracCell74_U_Actl 1;
BA_ "U_U55X_MY2022_Rx" SG_ 1182 BattTracCell74_U_Actl 1;
BA_ "U_CD542_MY2021_Rx" SG_ 1182 BattTracCell74_U_Actl 1;
BA_ "ECGUsedRxSignal" SG_ 1182 BattTracCell74_U_Actl 1;
BA_ "GenSigStartValue" SG_ 1182 BattTracCell74_U_Actl 4094;
BA_ "GenSigStartValueInteger" SG_ 1182 BattTracCell74_U_Actl 4094;
BA_ "U_CD542_MY2021_Tx" SG_ 1182 BattTracCell73_U_Actl 1;
BA_ "U_CX727_MY2021_Tx" SG_ 1182 BattTracCell73_U_Actl 1;
BA_ "U_U55X_MY2022_Rx" SG_ 1182 BattTracCell73_U_Actl 1;
BA_ "U_CD542_MY2021_Rx" SG_ 1182 BattTracCell73_U_Actl 1;
BA_ "ECGUsedRxSignal" SG_ 1182 BattTracCell73_U_Actl 1;
BA_ "GenSigStartValue" SG_ 1182 BattTracCell73_U_Actl 4094;
BA_ "GenSigStartValueInteger" SG_ 1182 BattTracCell73_U_Actl 4094;
BA_ "U_CD542_MY2021_Tx" SG_ 1182 BattTracCell72_U_Actl 1;
BA_ "U_CX727_MY2021_Tx" SG_ 1182 BattTracCell72_U_Actl 1;
BA_ "U_U55X_MY2022_Rx" SG_ 1182 BattTracCell72_U_Actl 1;
BA_ "U_CD542_MY2021_Rx" SG_ 1182 BattTracCell72_U_Actl 1;
BA_ "ECGUsedRxSignal" SG_ 1182 BattTracCell72_U_Actl 1;
BA_ "GenSigStartValue" SG_ 1182 BattTracCell72_U_Actl 4094;
BA_ "GenSigStartValueInteger" SG_ 1182 BattTracCell72_U_Actl 4094;
BA_ "U_CD542_MY2021_Tx" SG_ 1182 BattTracCell71_U_Actl 1;
BA_ "U_CX727_MY2021_Tx" SG_ 1182 BattTracCell71_U_Actl 1;
BA_ "U_U55X_MY2022_Rx" SG_ 1182 BattTracCell71_U_Actl 1;
BA_ "U_CD542_MY2021_Rx" SG_ 1182 BattTracCell71_U_Actl 1;
BA_ "ECGUsedRxSignal" SG_ 1182 BattTracCell71_U_Actl 1;
BA_ "GenSigStartValue" SG_ 1182 BattTracCell71_U_Actl 4094;
BA_ "GenSigStartValueInteger" SG_ 1182 BattTracCell71_U_Actl 4094;
BA_ "U_CD542_MY2021_Tx" SG_ 1181 BattTracCell70_U_Actl 1;
BA_ "U_CX727_MY2021_Tx" SG_ 1181 BattTracCell70_U_Actl 1;
BA_ "U_U55X_MY2022_Rx" SG_ 1181 BattTracCell70_U_Actl 1;
BA_ "U_CD542_MY2021_Rx" SG_ 1181 BattTracCell70_U_Actl 1;
BA_ "ECGUsedRxSignal" SG_ 1181 BattTracCell70_U_Actl 1;
BA_ "GenSigStartValue" SG_ 1181 BattTracCell70_U_Actl 4094;
BA_ "GenSigStartValueInteger" SG_ 1181 BattTracCell70_U_Actl 4094;
BA_ "U_CD542_MY2021_Tx" SG_ 1181 BattTracCell69_U_Actl 1;
BA_ "U_CX727_MY2021_Tx" SG_ 1181 BattTracCell69_U_Actl 1;
BA_ "U_U55X_MY2022_Rx" SG_ 1181 BattTracCell69_U_Actl 1;
BA_ "U_CD542_MY2021_Rx" SG_ 1181 BattTracCell69_U_Actl 1;
BA_ "ECGUsedRxSignal" SG_ 1181 BattTracCell69_U_Actl 1;
BA_ "GenSigStartValue" SG_ 1181 BattTracCell69_U_Actl 4094;
BA_ "GenSigStartValueInteger" SG_ 1181 BattTracCell69_U_Actl 4094;
BA_ "U_CD542_MY2021_Tx" SG_ 1181 BattTracCell68_U_Actl 1;
BA_ "U_CX727_MY2021_Tx" SG_ 1181 BattTracCell68_U_Actl 1;
BA_ "U_U55X_MY2022_Rx" SG_ 1181 BattTracCell68_U_Actl 1;
BA_ "U_CD542_MY2021_Rx" SG_ 1181 BattTracCell68_U_Actl 1;
BA_ "ECGUsedRxSignal" SG_ 1181 BattTracCell68_U_Actl 1;
BA_ "GenSigStartValue" SG_ 1181 BattTracCell68_U_Actl 4094;
BA_ "GenSigStartValueInteger" SG_ 1181 BattTracCell68_U_Actl 4094;
BA_ "U_CD542_MY2021_Tx" SG_ 1181 BattTracCell67_U_Actl 1;
BA_ "U_CX727_MY2021_Tx" SG_ 1181 BattTracCell67_U_Actl 1;
BA_ "U_U55X_MY2022_Rx" SG_ 1181 BattTracCell67_U_Actl 1;
BA_ "U_CD542_MY2021_Rx" SG_ 1181 BattTracCell67_U_Actl 1;
BA_ "ECGUsedRxSignal" SG_ 1181 BattTracCell67_U_Actl 1;
BA_ "GenSigStartValue" SG_ 1181 BattTracCell67_U_Actl 4094;
BA_ "GenSigStartValueInteger" SG_ 1181 BattTracCell67_U_Actl 4094;
BA_ "U_CD542_MY2021_Tx" SG_ 1181 BattTracCell66_U_Actl 1;
BA_ "U_CX727_MY2021_Tx" SG_ 1181 BattTracCell66_U_Actl 1;
BA_ "U_U55X_MY2022_Rx" SG_ 1181 BattTracCell66_U_Actl 1;
BA_ "U_CD542_MY2021_Rx" SG_ 1181 BattTracCell66_U_Actl 1;
BA_ "ECGUsedRxSignal" SG_ 1181 BattTracCell66_U_Actl 1;
BA_ "GenSigStartValue" SG_ 1181 BattTracCell66_U_Actl 4094;
BA_ "GenSigStartValueInteger" SG_ 1181 BattTracCell66_U_Actl 4094;
BA_ "U_CD542_MY2021_Tx" SG_ 1180 BattTracCell65_U_Actl 1;
BA_ "U_CX727_MY2021_Tx" SG_ 1180 BattTracCell65_U_Actl 1;
BA_ "U_U55X_MY2022_Rx" SG_ 1180 BattTracCell65_U_Actl 1;
BA_ "U_CD542_MY2021_Rx" SG_ 1180 BattTracCell65_U_Actl 1;
BA_ "ECGUsedRxSignal" SG_ 1180 BattTracCell65_U_Actl 1;
BA_ "GenSigStartValue" SG_ 1180 BattTracCell65_U_Actl 4094;
BA_ "GenSigStartValueInteger" SG_ 1180 BattTracCell65_U_Actl 4094;
BA_ "U_CD542_MY2021_Tx" SG_ 1180 BattTracCell64_U_Actl 1;
BA_ "U_CX727_MY2021_Tx" SG_ 1180 BattTracCell64_U_Actl 1;
BA_ "U_U55X_MY2022_Rx" SG_ 1180 BattTracCell64_U_Actl 1;
BA_ "U_CD542_MY2021_Rx" SG_ 1180 BattTracCell64_U_Actl 1;
BA_ "ECGUsedRxSignal" SG_ 1180 BattTracCell64_U_Actl 1;
BA_ "GenSigStartValue" SG_ 1180 BattTracCell64_U_Actl 4094;
BA_ "GenSigStartValueInteger" SG_ 1180 BattTracCell64_U_Actl 4094;
BA_ "U_CD542_MY2021_Tx" SG_ 1180 BattTracCell63_U_Actl 1;
BA_ "U_CX727_MY2021_Tx" SG_ 1180 BattTracCell63_U_Actl 1;
BA_ "U_U55X_MY2022_Rx" SG_ 1180 BattTracCell63_U_Actl 1;
BA_ "U_CD542_MY2021_Rx" SG_ 1180 BattTracCell63_U_Actl 1;
BA_ "ECGUsedRxSignal" SG_ 1180 BattTracCell63_U_Actl 1;
BA_ "GenSigStartValue" SG_ 1180 BattTracCell63_U_Actl 4094;
BA_ "GenSigStartValueInteger" SG_ 1180 BattTracCell63_U_Actl 4094;
BA_ "U_CD542_MY2021_Tx" SG_ 1180 BattTracCell62_U_Actl 1;
BA_ "U_CX727_MY2021_Tx" SG_ 1180 BattTracCell62_U_Actl 1;
BA_ "U_U55X_MY2022_Rx" SG_ 1180 BattTracCell62_U_Actl 1;
BA_ "U_CD542_MY2021_Rx" SG_ 1180 BattTracCell62_U_Actl 1;
BA_ "ECGUsedRxSignal" SG_ 1180 BattTracCell62_U_Actl 1;
BA_ "GenSigStartValue" SG_ 1180 BattTracCell62_U_Actl 4094;
BA_ "GenSigStartValueInteger" SG_ 1180 BattTracCell62_U_Actl 4094;
BA_ "U_CD542_MY2021_Tx" SG_ 1180 BattTracCell61_U_Actl 1;
BA_ "U_CX727_MY2021_Tx" SG_ 1180 BattTracCell61_U_Actl 1;
BA_ "U_U55X_MY2022_Rx" SG_ 1180 BattTracCell61_U_Actl 1;
BA_ "U_CD542_MY2021_Rx" SG_ 1180 BattTracCell61_U_Actl 1;
BA_ "ECGUsedRxSignal" SG_ 1180 BattTracCell61_U_Actl 1;
BA_ "GenSigStartValue" SG_ 1180 BattTracCell61_U_Actl 4094;
BA_ "GenSigStartValueInteger" SG_ 1180 BattTracCell61_U_Actl 4094;
BA_ "U_CD542_MY2021_Tx" SG_ 1179 BattTracCell60_U_Actl 1;
BA_ "U_CX727_MY2021_Tx" SG_ 1179 BattTracCell60_U_Actl 1;
BA_ "U_U55X_MY2022_Rx" SG_ 1179 BattTracCell60_U_Actl 1;
BA_ "U_CD542_MY2021_Rx" SG_ 1179 BattTracCell60_U_Actl 1;
BA_ "ECGUsedRxSignal" SG_ 1179 BattTracCell60_U_Actl 1;
BA_ "GenSigStartValue" SG_ 1179 BattTracCell60_U_Actl 4094;
BA_ "GenSigStartValueInteger" SG_ 1179 BattTracCell60_U_Actl 4094;
BA_ "U_CD542_MY2021_Tx" SG_ 1179 BattTracCell59_U_Actl 1;
BA_ "U_CX727_MY2021_Tx" SG_ 1179 BattTracCell59_U_Actl 1;
BA_ "U_U55X_MY2022_Rx" SG_ 1179 BattTracCell59_U_Actl 1;
BA_ "U_CD542_MY2021_Rx" SG_ 1179 BattTracCell59_U_Actl 1;
BA_ "ECGUsedRxSignal" SG_ 1179 BattTracCell59_U_Actl 1;
BA_ "GenSigStartValue" SG_ 1179 BattTracCell59_U_Actl 4094;
BA_ "GenSigStartValueInteger" SG_ 1179 BattTracCell59_U_Actl 4094;
BA_ "U_CD542_MY2021_Tx" SG_ 1179 BattTracCell58_U_Actl 1;
BA_ "U_CX727_MY2021_Tx" SG_ 1179 BattTracCell58_U_Actl 1;
BA_ "U_U55X_MY2022_Rx" SG_ 1179 BattTracCell58_U_Actl 1;
BA_ "U_CD542_MY2021_Rx" SG_ 1179 BattTracCell58_U_Actl 1;
BA_ "ECGUsedRxSignal" SG_ 1179 BattTracCell58_U_Actl 1;
BA_ "GenSigStartValue" SG_ 1179 BattTracCell58_U_Actl 4094;
BA_ "GenSigStartValueInteger" SG_ 1179 BattTracCell58_U_Actl 4094;
BA_ "U_CD542_MY2021_Tx" SG_ 1179 BattTracCell57_U_Actl 1;
BA_ "U_CX727_MY2021_Tx" SG_ 1179 BattTracCell57_U_Actl 1;
BA_ "U_U55X_MY2022_Rx" SG_ 1179 BattTracCell57_U_Actl 1;
BA_ "U_CD542_MY2021_Rx" SG_ 1179 BattTracCell57_U_Actl 1;
BA_ "ECGUsedRxSignal" SG_ 1179 BattTracCell57_U_Actl 1;
BA_ "GenSigStartValue" SG_ 1179 BattTracCell57_U_Actl 4094;
BA_ "GenSigStartValueInteger" SG_ 1179 BattTracCell57_U_Actl 4094;
BA_ "U_CD542_MY2021_Tx" SG_ 1179 BattTracCell56_U_Actl 1;
BA_ "U_CX727_MY2021_Tx" SG_ 1179 BattTracCell56_U_Actl 1;
BA_ "U_U55X_MY2022_Rx" SG_ 1179 BattTracCell56_U_Actl 1;
BA_ "U_CD542_MY2021_Rx" SG_ 1179 BattTracCell56_U_Actl 1;
BA_ "ECGUsedRxSignal" SG_ 1179 BattTracCell56_U_Actl 1;
BA_ "GenSigStartValue" SG_ 1179 BattTracCell56_U_Actl 4094;
BA_ "GenSigStartValueInteger" SG_ 1179 BattTracCell56_U_Actl 4094;
BA_ "U_CD542_MY2021_Tx" SG_ 1178 BattTracCell55_U_Actl 1;
BA_ "U_CX727_MY2021_Tx" SG_ 1178 BattTracCell55_U_Actl 1;
BA_ "U_U55X_MY2022_Rx" SG_ 1178 BattTracCell55_U_Actl 1;
BA_ "U_CD542_MY2021_Rx" SG_ 1178 BattTracCell55_U_Actl 1;
BA_ "ECGUsedRxSignal" SG_ 1178 BattTracCell55_U_Actl 1;
BA_ "GenSigStartValue" SG_ 1178 BattTracCell55_U_Actl 4094;
BA_ "GenSigStartValueInteger" SG_ 1178 BattTracCell55_U_Actl 4094;
BA_ "U_CD542_MY2021_Tx" SG_ 1178 BattTracCell54_U_Actl 1;
BA_ "U_CX727_MY2021_Tx" SG_ 1178 BattTracCell54_U_Actl 1;
BA_ "U_U55X_MY2022_Rx" SG_ 1178 BattTracCell54_U_Actl 1;
BA_ "U_CD542_MY2021_Rx" SG_ 1178 BattTracCell54_U_Actl 1;
BA_ "ECGUsedRxSignal" SG_ 1178 BattTracCell54_U_Actl 1;
BA_ "GenSigStartValue" SG_ 1178 BattTracCell54_U_Actl 4094;
BA_ "GenSigStartValueInteger" SG_ 1178 BattTracCell54_U_Actl 4094;
BA_ "U_CD542_MY2021_Tx" SG_ 1178 BattTracCell53_U_Actl 1;
BA_ "U_CX727_MY2021_Tx" SG_ 1178 BattTracCell53_U_Actl 1;
BA_ "U_U55X_MY2022_Rx" SG_ 1178 BattTracCell53_U_Actl 1;
BA_ "U_CD542_MY2021_Rx" SG_ 1178 BattTracCell53_U_Actl 1;
BA_ "ECGUsedRxSignal" SG_ 1178 BattTracCell53_U_Actl 1;
BA_ "GenSigStartValue" SG_ 1178 BattTracCell53_U_Actl 4094;
BA_ "GenSigStartValueInteger" SG_ 1178 BattTracCell53_U_Actl 4094;
BA_ "U_CD542_MY2021_Tx" SG_ 1178 BattTracCell52_U_Actl 1;
BA_ "U_CX727_MY2021_Tx" SG_ 1178 BattTracCell52_U_Actl 1;
BA_ "U_U55X_MY2022_Rx" SG_ 1178 BattTracCell52_U_Actl 1;
BA_ "U_CD542_MY2021_Rx" SG_ 1178 BattTracCell52_U_Actl 1;
BA_ "ECGUsedRxSignal" SG_ 1178 BattTracCell52_U_Actl 1;
BA_ "GenSigStartValue" SG_ 1178 BattTracCell52_U_Actl 4094;
BA_ "GenSigStartValueInteger" SG_ 1178 BattTracCell52_U_Actl 4094;
BA_ "U_CD542_MY2021_Tx" SG_ 1178 BattTracCell51_U_Actl 1;
BA_ "U_CX727_MY2021_Tx" SG_ 1178 BattTracCell51_U_Actl 1;
BA_ "U_U55X_MY2022_Rx" SG_ 1178 BattTracCell51_U_Actl 1;
BA_ "U_CD542_MY2021_Rx" SG_ 1178 BattTracCell51_U_Actl 1;
BA_ "ECGUsedRxSignal" SG_ 1178 BattTracCell51_U_Actl 1;
BA_ "GenSigStartValue" SG_ 1178 BattTracCell51_U_Actl 4094;
BA_ "GenSigStartValueInteger" SG_ 1178 BattTracCell51_U_Actl 4094;
BA_ "U_CD542_MY2021_Tx" SG_ 1177 BattTracCell50_U_Actl 1;
BA_ "U_CX727_MY2021_Tx" SG_ 1177 BattTracCell50_U_Actl 1;
BA_ "U_U55X_MY2022_Rx" SG_ 1177 BattTracCell50_U_Actl 1;
BA_ "U_CD542_MY2021_Rx" SG_ 1177 BattTracCell50_U_Actl 1;
BA_ "ECGUsedRxSignal" SG_ 1177 BattTracCell50_U_Actl 1;
BA_ "GenSigStartValue" SG_ 1177 BattTracCell50_U_Actl 4094;
BA_ "GenSigStartValueInteger" SG_ 1177 BattTracCell50_U_Actl 4094;
BA_ "U_CD542_MY2021_Tx" SG_ 1177 BattTracCell49_U_Actl 1;
BA_ "U_CX727_MY2021_Tx" SG_ 1177 BattTracCell49_U_Actl 1;
BA_ "U_U55X_MY2022_Rx" SG_ 1177 BattTracCell49_U_Actl 1;
BA_ "U_CD542_MY2021_Rx" SG_ 1177 BattTracCell49_U_Actl 1;
BA_ "ECGUsedRxSignal" SG_ 1177 BattTracCell49_U_Actl 1;
BA_ "GenSigStartValue" SG_ 1177 BattTracCell49_U_Actl 4094;
BA_ "GenSigStartValueInteger" SG_ 1177 BattTracCell49_U_Actl 4094;
BA_ "U_CD542_MY2021_Tx" SG_ 1177 BattTracCell48_U_Actl 1;
BA_ "U_CX727_MY2021_Tx" SG_ 1177 BattTracCell48_U_Actl 1;
BA_ "U_U55X_MY2022_Rx" SG_ 1177 BattTracCell48_U_Actl 1;
BA_ "U_CD542_MY2021_Rx" SG_ 1177 BattTracCell48_U_Actl 1;
BA_ "ECGUsedRxSignal" SG_ 1177 BattTracCell48_U_Actl 1;
BA_ "GenSigStartValue" SG_ 1177 BattTracCell48_U_Actl 4094;
BA_ "GenSigStartValueInteger" SG_ 1177 BattTracCell48_U_Actl 4094;
BA_ "U_CD542_MY2021_Tx" SG_ 1177 BattTracCell47_U_Actl 1;
BA_ "U_CX727_MY2021_Tx" SG_ 1177 BattTracCell47_U_Actl 1;
BA_ "U_U55X_MY2022_Rx" SG_ 1177 BattTracCell47_U_Actl 1;
BA_ "U_CD542_MY2021_Rx" SG_ 1177 BattTracCell47_U_Actl 1;
BA_ "ECGUsedRxSignal" SG_ 1177 BattTracCell47_U_Actl 1;
BA_ "GenSigStartValue" SG_ 1177 BattTracCell47_U_Actl 4094;
BA_ "GenSigStartValueInteger" SG_ 1177 BattTracCell47_U_Actl 4094;
BA_ "U_CD542_MY2021_Tx" SG_ 1177 BattTracCell46_U_Actl 1;
BA_ "U_CX727_MY2021_Tx" SG_ 1177 BattTracCell46_U_Actl 1;
BA_ "U_U55X_MY2022_Rx" SG_ 1177 BattTracCell46_U_Actl 1;
BA_ "U_CD542_MY2021_Rx" SG_ 1177 BattTracCell46_U_Actl 1;
BA_ "ECGUsedRxSignal" SG_ 1177 BattTracCell46_U_Actl 1;
BA_ "GenSigStartValue" SG_ 1177 BattTracCell46_U_Actl 4094;
BA_ "GenSigStartValueInteger" SG_ 1177 BattTracCell46_U_Actl 4094;
BA_ "U_CD542_MY2021_Tx" SG_ 1168 BattTracCell05_U_Actl 1;
BA_ "U_CX727_MY2021_Tx" SG_ 1168 BattTracCell05_U_Actl 1;
BA_ "U_U55X_MY2022_Rx" SG_ 1168 BattTracCell05_U_Actl 1;
BA_ "U_CD542_MY2021_Rx" SG_ 1168 BattTracCell05_U_Actl 1;
BA_ "ECGUsedRxSignal" SG_ 1168 BattTracCell05_U_Actl 1;
BA_ "GenSigStartValue" SG_ 1168 BattTracCell05_U_Actl 4094;
BA_ "GenSigStartValueInteger" SG_ 1168 BattTracCell05_U_Actl 4094;
BA_ "U_CD542_MY2021_Tx" SG_ 1168 BattTracCell04_U_Actl 1;
BA_ "U_CX727_MY2021_Tx" SG_ 1168 BattTracCell04_U_Actl 1;
BA_ "U_U55X_MY2022_Rx" SG_ 1168 BattTracCell04_U_Actl 1;
BA_ "U_CD542_MY2021_Rx" SG_ 1168 BattTracCell04_U_Actl 1;
BA_ "ECGUsedRxSignal" SG_ 1168 BattTracCell04_U_Actl 1;
BA_ "GenSigStartValue" SG_ 1168 BattTracCell04_U_Actl 4094;
BA_ "GenSigStartValueInteger" SG_ 1168 BattTracCell04_U_Actl 4094;
BA_ "U_CD542_MY2021_Tx" SG_ 1168 BattTracCell03_U_Actl 1;
BA_ "U_CX727_MY2021_Tx" SG_ 1168 BattTracCell03_U_Actl 1;
BA_ "U_U55X_MY2022_Rx" SG_ 1168 BattTracCell03_U_Actl 1;
BA_ "U_CD542_MY2021_Rx" SG_ 1168 BattTracCell03_U_Actl 1;
BA_ "ECGUsedRxSignal" SG_ 1168 BattTracCell03_U_Actl 1;
BA_ "GenSigStartValue" SG_ 1168 BattTracCell03_U_Actl 4094;
BA_ "GenSigStartValueInteger" SG_ 1168 BattTracCell03_U_Actl 4094;
BA_ "U_CD542_MY2021_Tx" SG_ 1168 BattTracCell02_U_Actl 1;
BA_ "U_CX727_MY2021_Tx" SG_ 1168 BattTracCell02_U_Actl 1;
BA_ "U_U55X_MY2022_Rx" SG_ 1168 BattTracCell02_U_Actl 1;
BA_ "U_CD542_MY2021_Rx" SG_ 1168 BattTracCell02_U_Actl 1;
BA_ "ECGUsedRxSignal" SG_ 1168 BattTracCell02_U_Actl 1;
BA_ "GenSigStartValue" SG_ 1168 BattTracCell02_U_Actl 4094;
BA_ "GenSigStartValueInteger" SG_ 1168 BattTracCell02_U_Actl 4094;
BA_ "U_CD542_MY2021_Tx" SG_ 1168 BattTracCell01_U_Actl 1;
BA_ "U_CX727_MY2021_Tx" SG_ 1168 BattTracCell01_U_Actl 1;
BA_ "U_U55X_MY2022_Rx" SG_ 1168 BattTracCell01_U_Actl 1;
BA_ "U_CD542_MY2021_Rx" SG_ 1168 BattTracCell01_U_Actl 1;
BA_ "ECGUsedRxSignal" SG_ 1168 BattTracCell01_U_Actl 1;
BA_ "GenSigStartValue" SG_ 1168 BattTracCell01_U_Actl 4094;
BA_ "GenSigStartValueInteger" SG_ 1168 BattTracCell01_U_Actl 4094;
BA_ "U_CD542_MY2021_Tx" SG_ 1092 BattTracCell_U_Mx 1;
BA_ "U_CX727_MY2021_Tx" SG_ 1092 BattTracCell_U_Mx 1;
BA_ "U_U55X_MY2022_Rx" SG_ 1092 BattTracCell_U_Mx 1;
BA_ "U_CD542_MY2021_Rx" SG_ 1092 BattTracCell_U_Mx 1;
BA_ "ECGUsedRxSignal" SG_ 1092 BattTracCell_U_Mx 1;
BA_ "U_CD542_MY2021_Tx" SG_ 1092 BattTracMnCell_Te_Actl 1;
BA_ "U_CX727_MY2021_Tx" SG_ 1092 BattTracMnCell_Te_Actl 1;
BA_ "U_U55X_MY2022_Rx" SG_ 1092 BattTracMnCell_Te_Actl 1;
BA_ "U_CD542_MY2021_Rx" SG_ 1092 BattTracMnCell_Te_Actl 1;
BA_ "ECGUsedRxSignal" SG_ 1092 BattTracMnCell_Te_Actl 1;
BA_ "GenSigStartValue" SG_ 1092 BattTracMnCell_Te_Actl 254;
BA_ "GenSigStartValueInteger" SG_ 1092 BattTracMnCell_Te_Actl 254;
BA_ "U_CD542_MY2021_Tx" SG_ 1092 BattTracInsAlrm_B_Stat 1;
BA_ "U_CX727_MY2021_Tx" SG_ 1092 BattTracInsAlrm_B_Stat 1;
BA_ "U_U55X_MY2022_Rx" SG_ 1092 BattTracInsAlrm_B_Stat 1;
BA_ "U_CD542_MY2021_Rx" SG_ 1092 BattTracInsAlrm_B_Stat 1;
BA_ "ECGUsedRxSignal" SG_ 1092 BattTracInsAlrm_B_Stat 1;
BA_ "U_CD542_MY2021_Tx" SG_ 1092 BattTracUMx_B_Stat 1;
BA_ "U_CX727_MY2021_Tx" SG_ 1092 BattTracUMx_B_Stat 1;
BA_ "U_U55X_MY2022_Rx" SG_ 1092 BattTracUMx_B_Stat 1;
BA_ "U_CD542_MY2021_Rx" SG_ 1092 BattTracUMx_B_Stat 1;
BA_ "ECGUsedRxSignal" SG_ 1092 BattTracUMx_B_Stat 1;
BA_ "U_CD542_MY2021_Tx" SG_ 1092 BattTracMxCell_Te_Actl 1;
BA_ "U_CX727_MY2021_Tx" SG_ 1092 BattTracMxCell_Te_Actl 1;
BA_ "U_U55X_MY2022_Rx" SG_ 1092 BattTracMxCell_Te_Actl 1;
BA_ "U_CD542_MY2021_Rx" SG_ 1092 BattTracMxCell_Te_Actl 1;
BA_ "ECGUsedRxSignal" SG_ 1092 BattTracMxCell_Te_Actl 1;
BA_ "GenSigStartValue" SG_ 1092 BattTracMxCell_Te_Actl 254;
BA_ "GenSigStartValueInteger" SG_ 1092 BattTracMxCell_Te_Actl 254;
BA_ "U_CD542_MY2021_Tx" SG_ 1092 BattTracEq_B_Actl 1;
BA_ "U_CX727_MY2021_Tx" SG_ 1092 BattTracEq_B_Actl 1;
BA_ "U_U55X_MY2022_Rx" SG_ 1092 BattTracEq_B_Actl 1;
BA_ "U_CD542_MY2021_Rx" SG_ 1092 BattTracEq_B_Actl 1;
BA_ "ECGUsedRxSignal" SG_ 1092 BattTracEq_B_Actl 1;
BA_ "U_CD542_MY2021_Tx" SG_ 1092 BattTracCell_U_Mn 1;
BA_ "U_CX727_MY2021_Tx" SG_ 1092 BattTracCell_U_Mn 1;
BA_ "U_U55X_MY2022_Rx" SG_ 1092 BattTracCell_U_Mn 1;
BA_ "U_CD542_MY2021_Rx" SG_ 1092 BattTracCell_U_Mn 1;
BA_ "ECGUsedRxSignal" SG_ 1092 BattTracCell_U_Mn 1;
BA_ "U_CD542_MY2021_Tx" SG_ 1092 BattTracUMn_B_Stat 1;
BA_ "U_CX727_MY2021_Tx" SG_ 1092 BattTracUMn_B_Stat 1;
BA_ "U_U55X_MY2022_Rx" SG_ 1092 BattTracUMn_B_Stat 1;
BA_ "U_CD542_MY2021_Rx" SG_ 1092 BattTracUMn_B_Stat 1;
BA_ "ECGUsedRxSignal" SG_ 1092 BattTracUMn_B_Stat 1;
BA_ "U_CD542_MY2021_Tx" SG_ 1092 BattTracUAlrm_B_Stat 1;
BA_ "U_CX727_MY2021_Tx" SG_ 1092 BattTracUAlrm_B_Stat 1;
BA_ "U_U55X_MY2022_Rx" SG_ 1092 BattTracUAlrm_B_Stat 1;
BA_ "U_CD542_MY2021_Rx" SG_ 1092 BattTracUAlrm_B_Stat 1;
BA_ "ECGUsedRxSignal" SG_ 1092 BattTracUAlrm_B_Stat 1;
BA_ "U_CD542_MY2021_Tx" SG_ 1092 BattTracInsltn_R_Actl 1;
BA_ "U_CX727_MY2021_Tx" SG_ 1092 BattTracInsltn_R_Actl 1;
BA_ "U_U55X_MY2022_Rx" SG_ 1092 BattTracInsltn_R_Actl 1;
BA_ "U_CD542_MY2021_Rx" SG_ 1092 BattTracInsltn_R_Actl 1;
BA_ "ECGUsedRxSignal" SG_ 1092 BattTracInsltn_R_Actl 1;
BA_ "GenSigStartValue" SG_ 1092 BattTracInsltn_R_Actl 255;
BA_ "GenSigStartValueInteger" SG_ 1092 BattTracInsltn_R_Actl 255;
BA_ "WakeupSignal" SG_ 513 ChrgStat_D3_Dsply 1;
BA_ "GenSigStartValue" SG_ 650 BptTglCnt_No_Rq 14;
BA_ "GenSigSendType" SG_ 650 BptTglCnt_No_Rq 3;
BA_ "ECGUsedTxSignal" SG_ 650 BptTglCnt_No_Rq 1;
BA_ "GenSigStartValueInteger" SG_ 650 BptIsol_D_Stat 6;
BA_ "GenSigStartValue" SG_ 650 BptIsol_D_Stat 6;
BA_ "GenSigSendType" SG_ 650 BptIsol_D_Stat 3;
BA_ "ECGUsedTxSignal" SG_ 650 BptIsol_D_Stat 1;
BA_ "GenSigSendType" SG_ 650 Bpt_D_StatEvse 3;
BA_ "ECGUsedTxSignal" SG_ 650 Bpt_D_StatEvse 1;
BA_ "GenSigStartValue" SG_ 650 BptTgl_D_Rq 2;
BA_ "GenSigSendType" SG_ 650 BptTgl_D_Rq 3;
BA_ "ECGUsedTxSignal" SG_ 650 BptTgl_D_Rq 1;
BA_ "GenSigStartValue" SG_ 650 BattTracIsoDis_D_RqBpt 2;
BA_ "GenSigSendType" SG_ 650 BattTracIsoDis_D_RqBpt 3;
BA_ "ECGUsedTxSignal" SG_ 650 BattTracIsoDis_D_RqBpt 1;
BA_ "GenSigStartValue" SG_ 655 EvseChrgOutHi_U_ActlBpt 1022;
BA_ "ECGUsedTxSignal" SG_ 655 EvseChrgOutHi_U_ActlBpt 1;
BA_ "GenSigStartValue" SG_ 655 EvseChrgOutHi_I_ActlBpt 32766;
BA_ "ECGUsedTxSignal" SG_ 655 EvseChrgOutHi_I_ActlBpt 1;
BA_ "GenSigStartValue" SG_ 655 EvseDchrg_Pw_Mx 32766;
BA_ "ECGUsedTxSignal" SG_ 655 EvseDchrg_Pw_Mx 1;
BA_ "GenSigStartValue" SG_ 655 EvseDchrg_I_Mx 32766;
BA_ "ECGUsedTxSignal" SG_ 655 EvseDchrg_I_Mx 1;
BA_ "GenSigSendType" SG_ 599 Bpt_D_StatBattTrac 3;
BA_ "GenSigSendType" SG_ 749 ChrgrSysFalt18_D_Stat 3;
BA_ "U_CX727_MY2021_Rx" SG_ 749 ChrgrSysFalt18_D_Stat 1;
BA_ "U_CD542_MY2021_Rx" SG_ 749 ChrgrSysFalt18_D_Stat 1;
BA_ "U_CX727_MY2021_Tx" SG_ 749 ChrgrSysFalt18_D_Stat 1;
BA_ "U_CD542_MY2021_Tx" SG_ 749 ChrgrSysFalt18_D_Stat 1;
BA_ "GenSigSendType" SG_ 749 ChrgrSysFalt17_D_Stat 3;
BA_ "U_CX727_MY2021_Rx" SG_ 749 ChrgrSysFalt17_D_Stat 1;
BA_ "U_CD542_MY2021_Rx" SG_ 749 ChrgrSysFalt17_D_Stat 1;
BA_ "U_CX727_MY2021_Tx" SG_ 749 ChrgrSysFalt17_D_Stat 1;
BA_ "U_CD542_MY2021_Tx" SG_ 749 ChrgrSysFalt17_D_Stat 1;
BA_ "GenSigSendType" SG_ 749 ChrgrSysFalt16_D_Stat 3;
BA_ "U_CX727_MY2021_Rx" SG_ 749 ChrgrSysFalt16_D_Stat 1;
BA_ "U_CD542_MY2021_Rx" SG_ 749 ChrgrSysFalt16_D_Stat 1;
BA_ "U_CX727_MY2021_Tx" SG_ 749 ChrgrSysFalt16_D_Stat 1;
BA_ "U_CD542_MY2021_Tx" SG_ 749 ChrgrSysFalt16_D_Stat 1;
BA_ "GenSigSendType" SG_ 749 ChrgrSysFalt15_D_Stat 3;
BA_ "U_CX727_MY2021_Rx" SG_ 749 ChrgrSysFalt15_D_Stat 1;
BA_ "U_CD542_MY2021_Rx" SG_ 749 ChrgrSysFalt15_D_Stat 1;
BA_ "U_CX727_MY2021_Tx" SG_ 749 ChrgrSysFalt15_D_Stat 1;
BA_ "U_CD542_MY2021_Tx" SG_ 749 ChrgrSysFalt15_D_Stat 1;
BA_ "GenSigSendType" SG_ 749 ChrgrSysFalt14_D_Stat 3;
BA_ "U_CX727_MY2021_Rx" SG_ 749 ChrgrSysFalt14_D_Stat 1;
BA_ "U_CD542_MY2021_Rx" SG_ 749 ChrgrSysFalt14_D_Stat 1;
BA_ "U_CX727_MY2021_Tx" SG_ 749 ChrgrSysFalt14_D_Stat 1;
BA_ "U_CD542_MY2021_Tx" SG_ 749 ChrgrSysFalt14_D_Stat 1;
BA_ "GenSigSendType" SG_ 749 ChrgrSysFalt13_D_Stat 3;
BA_ "U_CX727_MY2021_Rx" SG_ 749 ChrgrSysFalt13_D_Stat 1;
BA_ "U_CD542_MY2021_Rx" SG_ 749 ChrgrSysFalt13_D_Stat 1;
BA_ "U_CX727_MY2021_Tx" SG_ 749 ChrgrSysFalt13_D_Stat 1;
BA_ "U_CD542_MY2021_Tx" SG_ 749 ChrgrSysFalt13_D_Stat 1;
BA_ "GenSigSendType" SG_ 749 ChrgrSysFalt12_D_Stat 3;
BA_ "U_CX727_MY2021_Rx" SG_ 749 ChrgrSysFalt12_D_Stat 1;
BA_ "U_CD542_MY2021_Rx" SG_ 749 ChrgrSysFalt12_D_Stat 1;
BA_ "U_CX727_MY2021_Tx" SG_ 749 ChrgrSysFalt12_D_Stat 1;
BA_ "U_CD542_MY2021_Tx" SG_ 749 ChrgrSysFalt12_D_Stat 1;
BA_ "GenSigSendType" SG_ 749 ChrgrSysFalt11_D_Stat 3;
BA_ "U_CX727_MY2021_Rx" SG_ 749 ChrgrSysFalt11_D_Stat 1;
BA_ "U_CD542_MY2021_Rx" SG_ 749 ChrgrSysFalt11_D_Stat 1;
BA_ "U_CX727_MY2021_Tx" SG_ 749 ChrgrSysFalt11_D_Stat 1;
BA_ "U_CD542_MY2021_Tx" SG_ 749 ChrgrSysFalt11_D_Stat 1;
BA_ "GenSigSendType" SG_ 749 ChrgrSysFalt9_D_Stat 3;
BA_ "U_CX727_MY2021_Rx" SG_ 749 ChrgrSysFalt9_D_Stat 1;
BA_ "U_CD542_MY2021_Rx" SG_ 749 ChrgrSysFalt9_D_Stat 1;
BA_ "U_CX727_MY2021_Tx" SG_ 749 ChrgrSysFalt9_D_Stat 1;
BA_ "U_CD542_MY2021_Tx" SG_ 749 ChrgrSysFalt9_D_Stat 1;
BA_ "GenSigSendType" SG_ 749 ChrgrSysFalt8_D_Stat 3;
BA_ "U_CX727_MY2021_Rx" SG_ 749 ChrgrSysFalt8_D_Stat 1;
BA_ "U_CD542_MY2021_Rx" SG_ 749 ChrgrSysFalt8_D_Stat 1;
BA_ "U_CX727_MY2021_Tx" SG_ 749 ChrgrSysFalt8_D_Stat 1;
BA_ "U_CD542_MY2021_Tx" SG_ 749 ChrgrSysFalt8_D_Stat 1;
BA_ "GenSigSendType" SG_ 749 ChrgrSysFalt7_D_Stat 3;
BA_ "U_CX727_MY2021_Rx" SG_ 749 ChrgrSysFalt7_D_Stat 1;
BA_ "U_CD542_MY2021_Rx" SG_ 749 ChrgrSysFalt7_D_Stat 1;
BA_ "U_CX727_MY2021_Tx" SG_ 749 ChrgrSysFalt7_D_Stat 1;
BA_ "U_CD542_MY2021_Tx" SG_ 749 ChrgrSysFalt7_D_Stat 1;
BA_ "GenSigSendType" SG_ 749 ChrgrSysFalt6_D_Stat 3;
BA_ "U_CX727_MY2021_Rx" SG_ 749 ChrgrSysFalt6_D_Stat 1;
BA_ "U_CD542_MY2021_Rx" SG_ 749 ChrgrSysFalt6_D_Stat 1;
BA_ "U_CX727_MY2021_Tx" SG_ 749 ChrgrSysFalt6_D_Stat 1;
BA_ "U_CD542_MY2021_Tx" SG_ 749 ChrgrSysFalt6_D_Stat 1;
BA_ "GenSigSendType" SG_ 749 ChrgrSysFalt5_D_Stat 3;
BA_ "U_CX727_MY2021_Rx" SG_ 749 ChrgrSysFalt5_D_Stat 1;
BA_ "U_CD542_MY2021_Rx" SG_ 749 ChrgrSysFalt5_D_Stat 1;
BA_ "U_CX727_MY2021_Tx" SG_ 749 ChrgrSysFalt5_D_Stat 1;
BA_ "U_CD542_MY2021_Tx" SG_ 749 ChrgrSysFalt5_D_Stat 1;
BA_ "GenSigSendType" SG_ 749 ChrgrSysFalt4_D_Stat 3;
BA_ "U_CX727_MY2021_Rx" SG_ 749 ChrgrSysFalt4_D_Stat 1;
BA_ "U_CD542_MY2021_Rx" SG_ 749 ChrgrSysFalt4_D_Stat 1;
BA_ "U_CX727_MY2021_Tx" SG_ 749 ChrgrSysFalt4_D_Stat 1;
BA_ "U_CD542_MY2021_Tx" SG_ 749 ChrgrSysFalt4_D_Stat 1;
BA_ "GenSigSendType" SG_ 749 ChrgrSysFalt3_D_Stat 3;
BA_ "U_CX727_MY2021_Rx" SG_ 749 ChrgrSysFalt3_D_Stat 1;
BA_ "U_CD542_MY2021_Rx" SG_ 749 ChrgrSysFalt3_D_Stat 1;
BA_ "U_CX727_MY2021_Tx" SG_ 749 ChrgrSysFalt3_D_Stat 1;
BA_ "U_CD542_MY2021_Tx" SG_ 749 ChrgrSysFalt3_D_Stat 1;
BA_ "GenSigSendType" SG_ 749 ChrgrSysFalt2_D_Stat 3;
BA_ "U_CX727_MY2021_Rx" SG_ 749 ChrgrSysFalt2_D_Stat 1;
BA_ "U_CD542_MY2021_Rx" SG_ 749 ChrgrSysFalt2_D_Stat 1;
BA_ "U_CX727_MY2021_Tx" SG_ 749 ChrgrSysFalt2_D_Stat 1;
BA_ "U_CD542_MY2021_Tx" SG_ 749 ChrgrSysFalt2_D_Stat 1;
BA_ "GenSigSendType" SG_ 749 ChrgrSysFalt1_D_Stat 3;
BA_ "U_CX727_MY2021_Rx" SG_ 749 ChrgrSysFalt1_D_Stat 1;
BA_ "U_CD542_MY2021_Rx" SG_ 749 ChrgrSysFalt1_D_Stat 1;
BA_ "U_CD542_MY2021_Tx" SG_ 749 ChrgrSysFalt1_D_Stat 1;
BA_ "GenSigSendType" SG_ 749 ChrgrSysFalt10_D_Stat 3;
BA_ "U_CX727_MY2021_Rx" SG_ 749 ChrgrSysFalt10_D_Stat 1;
BA_ "U_CD542_MY2021_Rx" SG_ 749 ChrgrSysFalt10_D_Stat 1;
BA_ "U_CX727_MY2021_Tx" SG_ 749 ChrgrSysFalt10_D_Stat 1;
BA_ "U_CD542_MY2021_Tx" SG_ 749 ChrgrSysFalt10_D_Stat 1;
BA_ "GenSigSendType" SG_ 580 BattTracVrtOck_B_Rq 3;
BA_ "GenSigStartValueInteger" SG_ 1012 ChrgLocLongFrct_An_Sav 1048575;
BA_ "GenSigStartValue" SG_ 1012 ChrgLocLongFrct_An_Sav 1048575;
BA_ "GenSigStartValueInteger" SG_ 1012 ChrgLocLattFrct_An_Sav 1048575;
BA_ "GenSigStartValue" SG_ 1012 ChrgLocLattFrct_An_Sav 1048575;
BA_ "U_CX727_MY2021_Rx" SG_ 1012 ChrgNowCurnt_B_Dsply 1;
BA_ "U_CD542_MY2021_Rx" SG_ 1012 ChrgNowCurnt_B_Dsply 1;
BA_ "GenSigStartValue" SG_ 1149 BattTracPerf_Pc_Dsply 254;
BA_ "GenSigStartValue" SG_ 1149 BattTracPerf_Pc_Actl 254;
BA_ "GenSigStartValue" SG_ 770 ScMnSoc_Pc_Actl 100;
BA_ "GenSigStartValue" SG_ 770 CurntTrgtSoc_Pc_Rq 100;
BA_ "GenSigStartValue" SG_ 770 CurntTrgtSoc_Pc_Dsply 100;
BA_ "GenSigStartValueInteger" SG_ 123 BattTrac_U2_Actl 1022;
BA_ "GenSigStartValue" SG_ 123 BattTrac_U2_Actl 4094;
BA_ "ECGUsedRxSignal" SG_ 123 BattTrac_U2_Actl 1;
BA_ "U_CD542_MY2021_Rx" SG_ 123 BattTrac_U2_Actl 1;
BA_ "U_U55X_MY2022_Rx" SG_ 123 BattTrac_U2_Actl 1;
BA_ "GenSigStartValueInteger" SG_ 123 BattTrac_I2_Actl 15000;
BA_ "GenSigStartValue" SG_ 123 BattTrac_I2_Actl 262142;
BA_ "ECGUsedRxSignal" SG_ 123 BattTrac_I2_Actl 1;
BA_ "U_CD542_MY2021_Rx" SG_ 123 BattTrac_I2_Actl 1;
BA_ "U_U55X_MY2022_Rx" SG_ 123 BattTrac_I2_Actl 1;
BA_ "WakeupSignal" SG_ 1160 ReFuelSwtchStat_D_Actl2 1;
BA_ "GenSigSendType" SG_ 1160 ReFuelSwtchStat_D_Actl2 3;
BA_ "ECGUsedTxSignal" SG_ 1160 ReFuelSwtchStat_D_Actl2 1;
BA_ "U_CD764_MY2022_Tx" SG_ 1160 ReFuelSwtchStat_D_Actl2 1;
BA_ "GenSigSendType" SG_ 1160 DgtlCommPncReset_B_Req 3;
BA_ "ECGUsedTxSignal" SG_ 1160 DgtlCommPncReset_B_Req 1;
BA_ "U_CD542_MY2021_Tx" SG_ 1160 DgtlCommPncReset_B_Req 1;
BA_ "U_U55X_MY2022_Tx" SG_ 1160 DgtlCommPncReset_B_Req 1;
BA_ "U_CD764_MY2022_Tx" SG_ 1160 DgtlCommPncReset_B_Req 1;
BA_ "GenSigSendType" SG_ 1160 DgtlCommPnc_D_Rq 3;
BA_ "ECGUsedTxSignal" SG_ 1160 DgtlCommPnc_D_Rq 1;
BA_ "U_CD542_MY2021_Tx" SG_ 1160 DgtlCommPnc_D_Rq 1;
BA_ "U_U55X_MY2022_Tx" SG_ 1160 DgtlCommPnc_D_Rq 1;
BA_ "U_CD764_MY2022_Tx" SG_ 1160 DgtlCommPnc_D_Rq 1;
BA_ "GenSigSendType" SG_ 1160 PwSustnRdata_B_RqTelem 3;
BA_ "U_CD542_MY2021_Rx" SG_ 1160 PwSustnRdata_B_RqTelem 1;
BA_ "ECGUsedTxSignal" SG_ 1160 PwSustnRdata_B_RqTelem 1;
BA_ "U_CD542_MY2021_Tx" SG_ 1160 PwSustnRdata_B_RqTelem 1;
BA_ "U_U55X_MY2022_Tx" SG_ 1160 PwSustnRdata_B_RqTelem 1;
BA_ "U_CD764_MY2022_Tx" SG_ 1160 PwSustnRdata_B_RqTelem 1;
BA_ "GenSigSendType" SG_ 1160 DataMntrSustn_B_Rq 3;
BA_ "U_CD542_MY2021_Rx" SG_ 1160 DataMntrSustn_B_Rq 1;
BA_ "ECGUsedTxSignal" SG_ 1160 DataMntrSustn_B_Rq 1;
BA_ "U_CD542_MY2021_Tx" SG_ 1160 DataMntrSustn_B_Rq 1;
BA_ "U_U55X_MY2022_Tx" SG_ 1160 DataMntrSustn_B_Rq 1;
BA_ "U_CD764_MY2022_Tx" SG_ 1160 DataMntrSustn_B_Rq 1;
BA_ "GenSigSendType" SG_ 1119 CoolFanDcdc_D_Rq 3;
BA_ "U_CX727_MY2021_Rx" SG_ 1119 CoolFanDcdc_D_Rq 1;
BA_ "U_P702_MY2021_Rx" SG_ 1119 CoolFanDcdc_D_Rq 1;
BA_ "U_CD542_MY2021_Rx" SG_ 1119 CoolFanDcdc_D_Rq 1;
BA_ "U_CX727_MY2021_Tx" SG_ 1119 CoolFanDcdc_D_Rq 1;
BA_ "U_P702_MY2021_Tx" SG_ 1119 CoolFanDcdc_D_Rq 1;
BA_ "U_CD542_MY2021_Tx" SG_ 1119 CoolFanDcdc_D_Rq 1;
BA_ "GenSigSendType" SG_ 1119 DcdcClntFlw_D_Rq 3;
BA_ "U_CX727_MY2021_Rx" SG_ 1119 DcdcClntFlw_D_Rq 1;
BA_ "U_P702_MY2021_Rx" SG_ 1119 DcdcClntFlw_D_Rq 1;
BA_ "U_CD542_MY2021_Rx" SG_ 1119 DcdcClntFlw_D_Rq 1;
BA_ "U_CX727_MY2021_Tx" SG_ 1119 DcdcClntFlw_D_Rq 1;
BA_ "U_P702_MY2021_Tx" SG_ 1119 DcdcClntFlw_D_Rq 1;
BA_ "U_CD542_MY2021_Tx" SG_ 1119 DcdcClntFlw_D_Rq 1;
BA_ "GenSigStartValueInteger" SG_ 1152 StopStrtVThres_D_Stat 1;
BA_ "GenSigStartValue" SG_ 1152 StopStrtVThres_D_Stat 1;
BA_ "GenSigStartValueInteger" SG_ 1152 VehElEff_No_Avg 126;
BA_ "GenSigStartValue" SG_ 1152 VehElEff_No_Avg 126;
BA_ "U_CX727_MY2021_Rx" SG_ 1152 DcdcOn_B_Rq 1;
BA_ "U_P702_MY2021_Rx" SG_ 1152 DcdcOn_B_Rq 1;
BA_ "U_CD542_MY2021_Rx" SG_ 1152 DcdcOn_B_Rq 1;
BA_ "U_P702_MY2021_Rx" SG_ 1152 BattTracDiagClr_B_Stat 1;
BA_ "U_CD542_MY2021_Rx" SG_ 1152 BattTracDiagClr_B_Stat 1;
BA_ "U_CX727_MY2021_Rx" SG_ 1152 ULoBattSpprtSustn_B_Rq 1;
BA_ "U_CD542_MY2021_Rx" SG_ 1152 ULoBattSpprtSustn_B_Rq 1;
BA_ "U_P702_MY2021_Rx" SG_ 1152 ULoBattSpprtSustn_B_Rq 1;
BA_ "U_T6_MCA_MY2020_Rx" SG_ 1152 ULoBattSpprtSustn_B_Rq 1;
BA_ "U_U55X_MY2022_Rx" SG_ 1152 ULoBattSpprtSustn_B_Rq 1;
BA_ "U_CD764_MY2022_Rx" SG_ 1152 ULoBattSpprtSustn_B_Rq 1;
BA_ "GenSigSendType" SG_ 1118 AcChrgRdy_B_Stat 3;
BA_ "GenSigSendType" SG_ 1118 ExtChrgNowButtn_B_Rq 3;
BA_ "U_CX727_MY2021_Tx" SG_ 1118 ExtChrgNowButtn_B_Rq 1;
BA_ "U_CD542_MY2021_Tx" SG_ 1118 ExtChrgNowButtn_B_Rq 1;
BA_ "GenSigSendType" SG_ 1118 CoolFanChrgr_D_Rq 3;
BA_ "U_CX727_MY2021_Rx" SG_ 1118 CoolFanChrgr_D_Rq 1;
BA_ "U_CD542_MY2021_Rx" SG_ 1118 CoolFanChrgr_D_Rq 1;
BA_ "U_CX727_MY2021_Tx" SG_ 1118 CoolFanChrgr_D_Rq 1;
BA_ "U_CD542_MY2021_Tx" SG_ 1118 CoolFanChrgr_D_Rq 1;
BA_ "GenSigSendType" SG_ 1118 ChrgrClntFlw_D_Rq 3;
BA_ "U_CX727_MY2021_Rx" SG_ 1118 ChrgrClntFlw_D_Rq 1;
BA_ "U_CD542_MY2021_Rx" SG_ 1118 ChrgrClntFlw_D_Rq 1;
BA_ "U_CX727_MY2021_Tx" SG_ 1118 ChrgrClntFlw_D_Rq 1;
BA_ "U_CD542_MY2021_Tx" SG_ 1118 ChrgrClntFlw_D_Rq 1;
BA_ "GenSigSendType" SG_ 1118 PlgStatEvnt_B_Stat 3;
BA_ "U_CX727_MY2021_Rx" SG_ 1118 PlgStatEvnt_B_Stat 1;
BA_ "U_CD542_MY2021_Rx" SG_ 1118 PlgStatEvnt_B_Stat 1;
BA_ "U_CX727_MY2021_Tx" SG_ 1118 PlgStatEvnt_B_Stat 1;
BA_ "U_CD542_MY2021_Tx" SG_ 1118 PlgStatEvnt_B_Stat 1;
BA_ "GenSigSendType" SG_ 1118 ChrgrCnnctPwr_B_Stat 3;
BA_ "U_CX727_MY2021_Rx" SG_ 1118 ChrgrCnnctPwr_B_Stat 1;
BA_ "U_CD542_MY2021_Rx" SG_ 1118 ChrgrCnnctPwr_B_Stat 1;
BA_ "U_CX727_MY2021_Tx" SG_ 1118 ChrgrCnnctPwr_B_Stat 1;
BA_ "U_CD542_MY2021_Tx" SG_ 1118 ChrgrCnnctPwr_B_Stat 1;
BA_ "GenSigSendType" SG_ 1118 ChrgrAvailEvnt_B_Stat 3;
BA_ "U_CX727_MY2021_Rx" SG_ 1118 ChrgrAvailEvnt_B_Stat 1;
BA_ "U_CD542_MY2021_Rx" SG_ 1118 ChrgrAvailEvnt_B_Stat 1;
BA_ "U_CX727_MY2021_Tx" SG_ 1118 ChrgrAvailEvnt_B_Stat 1;
BA_ "U_CD542_MY2021_Tx" SG_ 1118 ChrgrAvailEvnt_B_Stat 1;
BA_ "GenSigSendType" SG_ 1118 ChrgrSrvcRqd_B_Rq 3;
BA_ "ECGUsedRxSignal" SG_ 1118 ChrgrSrvcRqd_B_Rq 1;
BA_ "U_CD542_MY2021_Rx" SG_ 1118 ChrgrSrvcRqd_B_Rq 1;
BA_ "U_CD764_MY2022_Rx" SG_ 1118 ChrgrSrvcRqd_B_Rq 1;
BA_ "U_CX727_MY2021_Tx" SG_ 1118 ChrgrSrvcRqd_B_Rq 1;
BA_ "U_CD542_MY2021_Tx" SG_ 1118 ChrgrSrvcRqd_B_Rq 1;
BA_ "GenSigSendType" SG_ 1118 ChrgrS2Swtch_B_Stat 3;
BA_ "U_CX727_MY2021_Tx" SG_ 1118 ChrgrS2Swtch_B_Stat 1;
BA_ "U_CD542_MY2021_Tx" SG_ 1118 ChrgrS2Swtch_B_Stat 1;
BA_ "GenSigSendType" SG_ 1118 ChrgChngEvnt_B_Stat 3;
BA_ "U_CX727_MY2021_Rx" SG_ 1118 ChrgChngEvnt_B_Stat 1;
BA_ "U_CD542_MY2021_Rx" SG_ 1118 ChrgChngEvnt_B_Stat 1;
BA_ "U_CX727_MY2021_Tx" SG_ 1118 ChrgChngEvnt_B_Stat 1;
BA_ "U_CD542_MY2021_Tx" SG_ 1118 ChrgChngEvnt_B_Stat 1;
BA_ "GenSigSendType" SG_ 1118 ChrgCordLck_D_Stat 3;
BA_ "U_CX727_MY2021_Tx" SG_ 1118 ChrgCordLck_D_Stat 1;
BA_ "U_CD542_MY2021_Tx" SG_ 1118 ChrgCordLck_D_Stat 1;
BA_ "GenSigSendType" SG_ 1118 ChrgrInPwMde_D_Actl 3;
BA_ "U_CX727_MY2021_Rx" SG_ 1118 ChrgrInPwMde_D_Actl 1;
BA_ "U_CD542_MY2021_Rx" SG_ 1118 ChrgrInPwMde_D_Actl 1;
BA_ "ECGUsedRxSignal" SG_ 1118 ChrgrInPwMde_D_Actl 1;
BA_ "U_CD764_MY2022_Rx" SG_ 1118 ChrgrInPwMde_D_Actl 1;
BA_ "U_CX727_MY2021_Tx" SG_ 1118 ChrgrInPwMde_D_Actl 1;
BA_ "U_CD542_MY2021_Tx" SG_ 1118 ChrgrInPwMde_D_Actl 1;
BA_ "GenSigSendType" SG_ 1118 ChrgPortDrOpen_B_Stat 3;
BA_ "U_CX727_MY2021_Tx" SG_ 1118 ChrgPortDrOpen_B_Stat 1;
BA_ "U_CD542_MY2021_Tx" SG_ 1118 ChrgPortDrOpen_B_Stat 1;
BA_ "GenSigSendType" SG_ 1118 ChrgCordChlng2_No_Actl 3;
BA_ "U_CX727_MY2021_Rx" SG_ 1118 ChrgCordChlng2_No_Actl 1;
BA_ "U_P702_MY2021_Rx" SG_ 1118 ChrgCordChlng2_No_Actl 1;
BA_ "U_T6_MCA_MY2020_Rx" SG_ 1118 ChrgCordChlng2_No_Actl 1;
BA_ "U_CD542_MY2021_Rx" SG_ 1118 ChrgCordChlng2_No_Actl 1;
BA_ "U_U55X_MY2022_Rx" SG_ 1118 ChrgCordChlng2_No_Actl 1;
BA_ "U_CD764_MY2022_Rx" SG_ 1118 ChrgCordChlng2_No_Actl 1;
BA_ "U_CX727_MY2021_Tx" SG_ 1118 ChrgCordChlng2_No_Actl 1;
BA_ "U_CD542_MY2021_Tx" SG_ 1118 ChrgCordChlng2_No_Actl 1;
BA_ "GenSigSendType" SG_ 1118 ChrgCordChlng1_No_Actl 3;
BA_ "U_CX727_MY2021_Rx" SG_ 1118 ChrgCordChlng1_No_Actl 1;
BA_ "U_P702_MY2021_Rx" SG_ 1118 ChrgCordChlng1_No_Actl 1;
BA_ "U_T6_MCA_MY2020_Rx" SG_ 1118 ChrgCordChlng1_No_Actl 1;
BA_ "U_CD542_MY2021_Rx" SG_ 1118 ChrgCordChlng1_No_Actl 1;
BA_ "U_U55X_MY2022_Rx" SG_ 1118 ChrgCordChlng1_No_Actl 1;
BA_ "U_CD764_MY2022_Rx" SG_ 1118 ChrgCordChlng1_No_Actl 1;
BA_ "U_CX727_MY2021_Tx" SG_ 1118 ChrgCordChlng1_No_Actl 1;
BA_ "U_CD542_MY2021_Tx" SG_ 1118 ChrgCordChlng1_No_Actl 1;
BA_ "GenSigSendType" SG_ 1118 ChrgCrdLck_D_Falt 3;
BA_ "U_CD542_MY2021_Tx" SG_ 1118 ChrgCrdLck_D_Falt 1;
BA_ "U_CX727_MY2021_Tx" SG_ 953 KeyMyKeyTot_No2_Cnt 1;
BA_ "U_P702_MY2021_Tx" SG_ 953 KeyMyKeyTot_No2_Cnt 1;
BA_ "U_T6_MCA_MY2020_Tx" SG_ 953 KeyMyKeyTot_No2_Cnt 1;
BA_ "U_CD542_MY2021_Tx" SG_ 953 KeyMyKeyTot_No2_Cnt 1;
BA_ "U_U55X_MY2022_Tx" SG_ 953 KeyMyKeyTot_No2_Cnt 1;
BA_ "U_CD764_MY2022_Tx" SG_ 953 KeyMyKeyTot_No2_Cnt 1;
BA_ "U_CX727_MY2021_Tx" SG_ 953 KeyAdmnTot_No2_Cnt 1;
BA_ "U_P702_MY2021_Tx" SG_ 953 KeyAdmnTot_No2_Cnt 1;
BA_ "U_T6_MCA_MY2020_Tx" SG_ 953 KeyAdmnTot_No2_Cnt 1;
BA_ "U_CD542_MY2021_Tx" SG_ 953 KeyAdmnTot_No2_Cnt 1;
BA_ "U_U55X_MY2022_Tx" SG_ 953 KeyAdmnTot_No2_Cnt 1;
BA_ "U_CD764_MY2022_Tx" SG_ 953 KeyAdmnTot_No2_Cnt 1;
BA_ "GenSigSendType" SG_ 953 PaakMyKeySearch_D_Stat 3;
BA_ "U_CX727_MY2021_Tx" SG_ 953 PaakMyKeySearch_D_Stat 1;
BA_ "U_P702_MY2021_Tx" SG_ 953 PaakMyKeySearch_D_Stat 1;
BA_ "U_T6_MCA_MY2020_Tx" SG_ 953 PaakMyKeySearch_D_Stat 1;
BA_ "U_CD542_MY2021_Tx" SG_ 953 PaakMyKeySearch_D_Stat 1;
BA_ "U_U55X_MY2022_Tx" SG_ 953 PaakMyKeySearch_D_Stat 1;
BA_ "U_CD764_MY2022_Tx" SG_ 953 PaakMyKeySearch_D_Stat 1;
BA_ "GenSigSendType" SG_ 953 BattULoChrgHyb_D_Stat 3;
BA_ "U_T6_MCA_MY2020_Rx" SG_ 953 BattULoChrgHyb_D_Stat 1;
BA_ "ECGUsedRxSignal" SG_ 953 BattULoChrgHyb_D_Stat 1;
BA_ "U_CD542_MY2021_Rx" SG_ 953 BattULoChrgHyb_D_Stat 1;
BA_ "U_U55X_MY2022_Rx" SG_ 953 BattULoChrgHyb_D_Stat 1;
BA_ "U_CD764_MY2022_Rx" SG_ 953 BattULoChrgHyb_D_Stat 1;
BA_ "U_T6_MCA_MY2020_Tx" SG_ 953 BattULoChrgHyb_D_Stat 1;
BA_ "U_CD542_MY2021_Tx" SG_ 953 BattULoChrgHyb_D_Stat 1;
BA_ "U_CD764_MY2022_Tx" SG_ 953 BattULoChrgHyb_D_Stat 1;
BA_ "GenSigSendType" SG_ 953 BattULoChrgHyb_B_Rq 3;
BA_ "U_T6_MCA_MY2020_Tx" SG_ 953 BattULoChrgHyb_B_Rq 1;
BA_ "U_CD542_MY2021_Tx" SG_ 953 BattULoChrgHyb_B_Rq 1;
BA_ "U_CD764_MY2022_Tx" SG_ 953 BattULoChrgHyb_B_Rq 1;
BA_ "GenSigSendType" SG_ 953 ChrgCordLck_B_Stat 3;
BA_ "U_CX727_MY2021_Rx" SG_ 953 ChrgCordLck_B_Stat 1;
BA_ "U_CD542_MY2021_Rx" SG_ 953 ChrgCordLck_B_Stat 1;
BA_ "U_T6_MCA_MY2020_Rx" SG_ 953 ChrgCordLck_B_Stat 1;
BA_ "ECGUsedRxSignal" SG_ 953 ChrgCordLck_B_Stat 1;
BA_ "U_U55X_MY2022_Rx" SG_ 953 ChrgCordLck_B_Stat 1;
BA_ "U_CD764_MY2022_Rx" SG_ 953 ChrgCordLck_B_Stat 1;
BA_ "U_CX727_MY2021_Tx" SG_ 953 ChrgCordLck_B_Stat 1;
BA_ "U_P702_MY2021_Tx" SG_ 953 ChrgCordLck_B_Stat 1;
BA_ "U_T6_MCA_MY2020_Tx" SG_ 953 ChrgCordLck_B_Stat 1;
BA_ "U_CD542_MY2021_Tx" SG_ 953 ChrgCordLck_B_Stat 1;
BA_ "U_U55X_MY2022_Tx" SG_ 953 ChrgCordLck_B_Stat 1;
BA_ "U_CD764_MY2022_Tx" SG_ 953 ChrgCordLck_B_Stat 1;
BA_ "U_CX727_MY2021_Rx" SG_ 953 ChrgCordResp2_No_Actl 1;
BA_ "U_CD542_MY2021_Rx" SG_ 953 ChrgCordResp2_No_Actl 1;
BA_ "U_CX727_MY2021_Tx" SG_ 953 ChrgCordResp2_No_Actl 1;
BA_ "U_P702_MY2021_Tx" SG_ 953 ChrgCordResp2_No_Actl 1;
BA_ "U_T6_MCA_MY2020_Tx" SG_ 953 ChrgCordResp2_No_Actl 1;
BA_ "U_CD542_MY2021_Tx" SG_ 953 ChrgCordResp2_No_Actl 1;
BA_ "U_U55X_MY2022_Tx" SG_ 953 ChrgCordResp2_No_Actl 1;
BA_ "U_CD764_MY2022_Tx" SG_ 953 ChrgCordResp2_No_Actl 1;
BA_ "U_CX727_MY2021_Rx" SG_ 953 ChrgCordResp1_No_Actl 1;
BA_ "U_CD542_MY2021_Rx" SG_ 953 ChrgCordResp1_No_Actl 1;
BA_ "U_CX727_MY2021_Tx" SG_ 953 ChrgCordResp1_No_Actl 1;
BA_ "U_P702_MY2021_Tx" SG_ 953 ChrgCordResp1_No_Actl 1;
BA_ "U_T6_MCA_MY2020_Tx" SG_ 953 ChrgCordResp1_No_Actl 1;
BA_ "U_CD542_MY2021_Tx" SG_ 953 ChrgCordResp1_No_Actl 1;
BA_ "U_U55X_MY2022_Tx" SG_ 953 ChrgCordResp1_No_Actl 1;
BA_ "U_CD764_MY2022_Tx" SG_ 953 ChrgCordResp1_No_Actl 1;
BA_ "GenSigStartValueInteger" SG_ 953 WakeAlarm3_D_Stat 3;
BA_ "GenSigStartValue" SG_ 953 WakeAlarm3_D_Stat 3;
BA_ "GenSigSendType" SG_ 953 WakeAlarm3_D_Stat 3;
BA_ "U_CX727_MY2021_Tx" SG_ 953 WakeAlarm3_D_Stat 1;
BA_ "U_P702_MY2021_Tx" SG_ 953 WakeAlarm3_D_Stat 1;
BA_ "U_T6_MCA_MY2020_Tx" SG_ 953 WakeAlarm3_D_Stat 1;
BA_ "U_CD542_MY2021_Tx" SG_ 953 WakeAlarm3_D_Stat 1;
BA_ "U_U55X_MY2022_Tx" SG_ 953 WakeAlarm3_D_Stat 1;
BA_ "U_CD764_MY2022_Tx" SG_ 953 WakeAlarm3_D_Stat 1;
BA_ "GenSigStartValueInteger" SG_ 953 WakeAlarm2_D_Stat 3;
BA_ "GenSigStartValue" SG_ 953 WakeAlarm2_D_Stat 3;
BA_ "GenSigSendType" SG_ 953 WakeAlarm2_D_Stat 3;
BA_ "U_CX727_MY2021_Tx" SG_ 953 WakeAlarm2_D_Stat 1;
BA_ "U_P702_MY2021_Tx" SG_ 953 WakeAlarm2_D_Stat 1;
BA_ "U_T6_MCA_MY2020_Tx" SG_ 953 WakeAlarm2_D_Stat 1;
BA_ "U_CD542_MY2021_Tx" SG_ 953 WakeAlarm2_D_Stat 1;
BA_ "U_U55X_MY2022_Tx" SG_ 953 WakeAlarm2_D_Stat 1;
BA_ "U_CD764_MY2022_Tx" SG_ 953 WakeAlarm2_D_Stat 1;
BA_ "GenSigStartValueInteger" SG_ 953 WakeAlarm1_D_Stat 3;
BA_ "GenSigStartValue" SG_ 953 WakeAlarm1_D_Stat 3;
BA_ "GenSigSendType" SG_ 953 WakeAlarm1_D_Stat 3;
BA_ "U_CX727_MY2021_Tx" SG_ 953 WakeAlarm1_D_Stat 1;
BA_ "U_P702_MY2021_Tx" SG_ 953 WakeAlarm1_D_Stat 1;
BA_ "U_T6_MCA_MY2020_Tx" SG_ 953 WakeAlarm1_D_Stat 1;
BA_ "U_CD542_MY2021_Tx" SG_ 953 WakeAlarm1_D_Stat 1;
BA_ "U_U55X_MY2022_Tx" SG_ 953 WakeAlarm1_D_Stat 1;
BA_ "U_CD764_MY2022_Tx" SG_ 953 WakeAlarm1_D_Stat 1;
BA_ "GenSigStartValueInteger" SG_ 953 WakeAlarm0_D_Stat 3;
BA_ "GenSigStartValue" SG_ 953 WakeAlarm0_D_Stat 3;
BA_ "GenSigSendType" SG_ 953 WakeAlarm0_D_Stat 3;
BA_ "U_CX727_MY2021_Tx" SG_ 953 WakeAlarm0_D_Stat 1;
BA_ "U_P702_MY2021_Tx" SG_ 953 WakeAlarm0_D_Stat 1;
BA_ "U_T6_MCA_MY2020_Tx" SG_ 953 WakeAlarm0_D_Stat 1;
BA_ "U_CD542_MY2021_Tx" SG_ 953 WakeAlarm0_D_Stat 1;
BA_ "U_U55X_MY2022_Tx" SG_ 953 WakeAlarm0_D_Stat 1;
BA_ "U_CD764_MY2022_Tx" SG_ 953 WakeAlarm0_D_Stat 1;
BA_ "GenSigStartValueInteger" SG_ 1112 BattTrac2_E_Max 4094;
BA_ "GenSigStartValue" SG_ 1112 BattTrac2_E_Max 4094;
BA_ "ECGUsedRxSignal" SG_ 1112 BattTrac2_E_Max 1;
BA_ "U_CD542_MY2021_Rx" SG_ 1112 BattTrac2_E_Max 1;
BA_ "U_U55X_MY2022_Rx" SG_ 1112 BattTrac2_E_Max 1;
BA_ "U_CD764_MY2022_Rx" SG_ 1112 BattTrac2_E_Max 1;
BA_ "U_CX727_MY2021_Tx" SG_ 1112 BattTrac2_E_Max 1;
BA_ "U_CD542_MY2021_Tx" SG_ 1112 BattTrac2_E_Max 1;
BA_ "ECGUsedRxSignal" SG_ 1112 BattTrac2_E_Avail 1;
BA_ "U_CD542_MY2021_Rx" SG_ 1112 BattTrac2_E_Avail 1;
BA_ "U_U55X_MY2022_Rx" SG_ 1112 BattTrac2_E_Avail 1;
BA_ "U_CD764_MY2022_Rx" SG_ 1112 BattTrac2_E_Avail 1;
BA_ "U_CX727_MY2021_Tx" SG_ 1112 BattTrac2_E_Avail 1;
BA_ "U_CD542_MY2021_Tx" SG_ 1112 BattTrac2_E_Avail 1;
BA_ "GenSigSendType" SG_ 1112 BattTracTeEvnt_B_Stat 3;
BA_ "U_CX727_MY2021_Rx" SG_ 1112 BattTracTeEvnt_B_Stat 1;
BA_ "U_CD542_MY2021_Rx" SG_ 1112 BattTracTeEvnt_B_Stat 1;
BA_ "U_CX727_MY2021_Tx" SG_ 1112 BattTracTeEvnt_B_Stat 1;
BA_ "U_CD542_MY2021_Tx" SG_ 1112 BattTracTeEvnt_B_Stat 1;
BA_ "GenSigSendType" SG_ 1112 BattChrgTrgtEvnt_B_Stat 3;
BA_ "U_CX727_MY2021_Rx" SG_ 1112 BattChrgTrgtEvnt_B_Stat 1;
BA_ "U_CD542_MY2021_Rx" SG_ 1112 BattChrgTrgtEvnt_B_Stat 1;
BA_ "U_CX727_MY2021_Tx" SG_ 1112 BattChrgTrgtEvnt_B_Stat 1;
BA_ "U_CD542_MY2021_Tx" SG_ 1112 BattChrgTrgtEvnt_B_Stat 1;
BA_ "GenSigSendType" SG_ 1112 BattTracTeSustn_B_Rq 3;
BA_ "U_CX727_MY2021_Rx" SG_ 1112 BattTracTeSustn_B_Rq 1;
BA_ "U_P702_MY2021_Rx" SG_ 1112 BattTracTeSustn_B_Rq 1;
BA_ "U_T6_MCA_MY2020_Rx" SG_ 1112 BattTracTeSustn_B_Rq 1;
BA_ "U_CD542_MY2021_Rx" SG_ 1112 BattTracTeSustn_B_Rq 1;
BA_ "U_U55X_MY2022_Rx" SG_ 1112 BattTracTeSustn_B_Rq 1;
BA_ "U_CD764_MY2022_Rx" SG_ 1112 BattTracTeSustn_B_Rq 1;
BA_ "GenSigSendType" SG_ 1112 BattTracChrgSustn_B_Rq 3;
BA_ "U_CX727_MY2021_Rx" SG_ 1112 BattTracChrgSustn_B_Rq 1;
BA_ "U_CD542_MY2021_Rx" SG_ 1112 BattTracChrgSustn_B_Rq 1;
BA_ "U_P702_MY2021_Rx" SG_ 1112 BattTracChrgSustn_B_Rq 1;
BA_ "U_T6_MCA_MY2020_Rx" SG_ 1112 BattTracChrgSustn_B_Rq 1;
BA_ "U_U55X_MY2022_Rx" SG_ 1112 BattTracChrgSustn_B_Rq 1;
BA_ "U_CD764_MY2022_Rx" SG_ 1112 BattTracChrgSustn_B_Rq 1;
BA_ "U_CX727_MY2021_Tx" SG_ 1112 BattTracChrgSustn_B_Rq 1;
BA_ "U_CD542_MY2021_Tx" SG_ 1112 BattTracChrgSustn_B_Rq 1;
BA_ "GenSigSendType" SG_ 1112 BattTracHeat_D_Rq 3;
BA_ "GenSigSendType" SG_ 1112 BattTracCnnct_D_Cmd 3;
BA_ "U_CX727_MY2021_Rx" SG_ 1112 BattTracCnnct_D_Cmd 1;
BA_ "U_CD542_MY2021_Rx" SG_ 1112 BattTracCnnct_D_Cmd 1;
BA_ "U_CX727_MY2021_Tx" SG_ 1112 BattTracCnnct_D_Cmd 1;
BA_ "U_P702_MY2021_Tx" SG_ 1112 BattTracCnnct_D_Cmd 1;
BA_ "U_CD542_MY2021_Tx" SG_ 1112 BattTracCnnct_D_Cmd 1;
BA_ "GenSigSendType" SG_ 1112 BattTracHvilOpen_B_Stat 3;
BA_ "U_CX727_MY2021_Tx" SG_ 1112 BattTracHvilOpen_B_Stat 1;
BA_ "U_P702_MY2021_Tx" SG_ 1112 BattTracHvilOpen_B_Stat 1;
BA_ "U_CD542_MY2021_Tx" SG_ 1112 BattTracHvilOpen_B_Stat 1;
BA_ "GenSigSendType" SG_ 1112 BattTracDcdcDis_B_Rq 3;
BA_ "U_CX727_MY2021_Tx" SG_ 1112 BattTracDcdcDis_B_Rq 1;
BA_ "U_P702_MY2021_Tx" SG_ 1112 BattTracDcdcDis_B_Rq 1;
BA_ "U_CD542_MY2021_Tx" SG_ 1112 BattTracDcdcDis_B_Rq 1;
BA_ "GenSigSendType" SG_ 1112 BattTracDiagClr_B_Rq 3;
BA_ "U_CX727_MY2021_Tx" SG_ 1112 BattTracDiagClr_B_Rq 1;
BA_ "U_P702_MY2021_Tx" SG_ 1112 BattTracDiagClr_B_Rq 1;
BA_ "U_CD542_MY2021_Tx" SG_ 1112 BattTracDiagClr_B_Rq 1;
BA_ "GenSigSendType" SG_ 1112 BattTracHazrd_D_Stat 3;
BA_ "U_CD542_MY2021_Tx" SG_ 1112 BattTracHazrd_D_Stat 1;
BA_ "GenSigSendType" SG_ 1112 HtrnClntPump_D_Stat 3;
BA_ "U_CX727_MY2021_Rx" SG_ 1112 HtrnClntPump_D_Stat 1;
BA_ "U_CD542_MY2021_Rx" SG_ 1112 HtrnClntPump_D_Stat 1;
BA_ "U_P702_MY2021_Rx" SG_ 1112 HtrnClntPump_D_Stat 1;
BA_ "U_CX727_MY2021_Tx" SG_ 1112 HtrnClntPump_D_Stat 1;
BA_ "U_P702_MY2021_Tx" SG_ 1112 HtrnClntPump_D_Stat 1;
BA_ "U_CD542_MY2021_Tx" SG_ 1112 HtrnClntPump_D_Stat 1;
BA_ "GenSigStartValueInteger" SG_ 1112 BattTracDelta_Te_Actl 164;
BA_ "GenSigStartValue" SG_ 1112 BattTracDelta_Te_Actl 254;
BA_ "U_CX727_MY2021_Tx" SG_ 1112 BattTracDelta_Te_Actl 1;
BA_ "U_P702_MY2021_Tx" SG_ 1112 BattTracDelta_Te_Actl 1;
BA_ "U_CD542_MY2021_Tx" SG_ 1112 BattTracDelta_Te_Actl 1;
BA_ "ContentDependant" SG_ 1112 BattTracClntPmp_D_Stat 1;
BA_ "GenSigSendType" SG_ 1112 BattTracClntPmp_D_Stat 3;
BA_ "U_CX727_MY2021_Tx" SG_ 1112 BattTracClntPmp_D_Stat 1;
BA_ "U_P702_MY2021_Tx" SG_ 1112 BattTracClntPmp_D_Stat 1;
BA_ "U_CD542_MY2021_Tx" SG_ 1112 BattTracClntPmp_D_Stat 1;
BA_ "U_CX727_MY2021_Rx" SG_ 1144 BattChrgTrgtSoC_D_Rq 1;
BA_ "U_CD542_MY2021_Rx" SG_ 1144 BattChrgTrgtSoC_D_Rq 1;
BA_ "GenSigSendType" SG_ 1144 PreCondBatt_B_Actl 3;
BA_ "WakeupSignal" SG_ 1144 CabnEvapSovFront_B_Rq 1;
BA_ "GenSigSendType" SG_ 1144 CabnEvapSovFront_B_Rq 3;
BA_ "U_CX727_MY2021_Rx" SG_ 1144 CabnEvapSovFront_B_Rq 1;
BA_ "U_P702_MY2021_Rx" SG_ 1144 CabnEvapSovFront_B_Rq 1;
BA_ "U_CD542_MY2021_Rx" SG_ 1144 CabnEvapSovFront_B_Rq 1;
BA_ "U_U55X_MY2022_Rx" SG_ 1144 CabnEvapSovFront_B_Rq 1;
BA_ "WakeupSignal" SG_ 1144 HeatCoreSovRear_B_Rq 1;
BA_ "GenSigSendType" SG_ 1144 HeatCoreSovRear_B_Rq 3;
BA_ "WakeupSignal" SG_ 1144 BattChlrSov_B_Rq 1;
BA_ "GenSigSendType" SG_ 1144 BattChlrSov_B_Rq 3;
BA_ "U_CX727_MY2021_Rx" SG_ 1144 BattChlrSov_B_Rq 1;
BA_ "U_P702_MY2021_Rx" SG_ 1144 BattChlrSov_B_Rq 1;
BA_ "U_CD542_MY2021_Rx" SG_ 1144 BattChlrSov_B_Rq 1;
BA_ "U_U55X_MY2022_Rx" SG_ 1144 BattChlrSov_B_Rq 1;
BA_ "WakeupSignal" SG_ 1144 CabnEvapSovRear_B_Rq 1;
BA_ "GenSigSendType" SG_ 1144 CabnEvapSovRear_B_Rq 3;
BA_ "GenSigSendType" SG_ 1144 BrkAppl_D_RqPt 3;
BA_ "GenSigSendType" SG_ 1144 BattClntVlvOvrrd_D_Rq 3;
BA_ "GenSigSendType" SG_ 1144 BattTracChillerOn_B_Rq 3;
BA_ "GenSigSendType" SG_ 1144 BattTracChiller_D_Stat 3;
BA_ "GenSigSendType" SG_ 1144 ULoBattTrnsfrSustn_B_Rq 3;
BA_ "U_CD542_MY2021_Rx" SG_ 1144 ULoBattTrnsfrSustn_B_Rq 1;
BA_ "U_U55X_MY2022_Rx" SG_ 1144 ULoBattTrnsfrSustn_B_Rq 1;
BA_ "U_CD764_MY2022_Rx" SG_ 1144 ULoBattTrnsfrSustn_B_Rq 1;
BA_ "GenSigSendType" SG_ 1144 ULoBattTransfer_D_Stat 3;
BA_ "U_CD542_MY2021_Rx" SG_ 1144 ULoBattTransfer_D_Stat 1;
BA_ "U_U55X_MY2022_Rx" SG_ 1144 ULoBattTransfer_D_Stat 1;
BA_ "U_CD764_MY2022_Rx" SG_ 1144 ULoBattTransfer_D_Stat 1;
BA_ "GenSigSendType" SG_ 1144 HtrnDcdcDis_B_Rq 3;
BA_ "GenSigSendType" SG_ 1144 HtrnCnnctPwr_B_Stat 3;
BA_ "U_CX727_MY2021_Rx" SG_ 1144 HtrnCnnctPwr_B_Stat 1;
BA_ "U_CD542_MY2021_Rx" SG_ 1144 HtrnCnnctPwr_B_Stat 1;
BA_ "U_P702_MY2021_Rx" SG_ 1144 HtrnCnnctPwr_B_Stat 1;
BA_ "GenSigSendType" SG_ 1144 PtcHtr_D_Stat 3;
BA_ "GenSigStartValue" SG_ 1144 BattChrgInhbt_D2_Rq 1;
BA_ "GenSigSendType" SG_ 1144 WakeAlarm0_B_Typ 3;
BA_ "U_CX727_MY2021_Rx" SG_ 1144 WakeAlarm0_B_Typ 1;
BA_ "U_P702_MY2021_Rx" SG_ 1144 WakeAlarm0_B_Typ 1;
BA_ "U_T6_MCA_MY2020_Rx" SG_ 1144 WakeAlarm0_B_Typ 1;
BA_ "U_CD542_MY2021_Rx" SG_ 1144 WakeAlarm0_B_Typ 1;
BA_ "U_U55X_MY2022_Rx" SG_ 1144 WakeAlarm0_B_Typ 1;
BA_ "U_CD764_MY2022_Rx" SG_ 1144 WakeAlarm0_B_Typ 1;
BA_ "GenSigStartValueInteger" SG_ 1144 WakeAlarm0_T_Rq 32767;
BA_ "GenSigStartValue" SG_ 1144 WakeAlarm0_T_Rq 32767;
BA_ "U_CX727_MY2021_Rx" SG_ 1144 WakeAlarm0_T_Rq 1;
BA_ "U_P702_MY2021_Rx" SG_ 1144 WakeAlarm0_T_Rq 1;
BA_ "U_T6_MCA_MY2020_Rx" SG_ 1144 WakeAlarm0_T_Rq 1;
BA_ "U_CD542_MY2021_Rx" SG_ 1144 WakeAlarm0_T_Rq 1;
BA_ "U_U55X_MY2022_Rx" SG_ 1144 WakeAlarm0_T_Rq 1;
BA_ "U_CD764_MY2022_Rx" SG_ 1144 WakeAlarm0_T_Rq 1;
BA_ "GenSigSendType" SG_ 1144 BattTracClimtDis_B_Stat 3;
BA_ "GenSigSendType" SG_ 1144 HtrnClntFlw_D_Rq 3;
BA_ "U_CX727_MY2021_Rx" SG_ 1144 HtrnClntFlw_D_Rq 1;
BA_ "U_P702_MY2021_Rx" SG_ 1144 HtrnClntFlw_D_Rq 1;
BA_ "U_CD542_MY2021_Rx" SG_ 1144 HtrnClntFlw_D_Rq 1;
BA_ "GenSigSendType" SG_ 1144 BattTracDrvSustn_B_Rq 3;
BA_ "U_CX727_MY2021_Rx" SG_ 1144 BattTracDrvSustn_B_Rq 1;
BA_ "U_CD542_MY2021_Rx" SG_ 1144 BattTracDrvSustn_B_Rq 1;
BA_ "U_P702_MY2021_Rx" SG_ 1144 BattTracDrvSustn_B_Rq 1;
BA_ "U_T6_MCA_MY2020_Rx" SG_ 1144 BattTracDrvSustn_B_Rq 1;
BA_ "U_U55X_MY2022_Rx" SG_ 1144 BattTracDrvSustn_B_Rq 1;
BA_ "U_CD764_MY2022_Rx" SG_ 1144 BattTracDrvSustn_B_Rq 1;
BA_ "GenSigSendType" SG_ 1144 CabinDrvSustn_B_Rq 3;
BA_ "U_CX727_MY2021_Rx" SG_ 1144 CabinDrvSustn_B_Rq 1;
BA_ "U_CD542_MY2021_Rx" SG_ 1144 CabinDrvSustn_B_Rq 1;
BA_ "U_P702_MY2021_Rx" SG_ 1144 CabinDrvSustn_B_Rq 1;
BA_ "U_T6_MCA_MY2020_Rx" SG_ 1144 CabinDrvSustn_B_Rq 1;
BA_ "U_U55X_MY2022_Rx" SG_ 1144 CabinDrvSustn_B_Rq 1;
BA_ "U_CD764_MY2022_Rx" SG_ 1144 CabinDrvSustn_B_Rq 1;
BA_ "GenSigSendType" SG_ 1144 BattTracClntVlv_B_Rq 3;
BA_ "U_P702_MY2021_Rx" SG_ 1144 BattTracClntVlv_B_Rq 1;
BA_ "U_CD542_MY2021_Rx" SG_ 1144 BattTracClntVlv_B_Rq 1;
BA_ "U_U55X_MY2022_Rx" SG_ 1144 BattTracClntVlv_B_Rq 1;
BA_ "GenSigSendType" SG_ 1144 ChrgNowEvnt_B_Stat 3;
BA_ "U_CX727_MY2021_Rx" SG_ 1144 ChrgNowEvnt_B_Stat 1;
BA_ "U_CD542_MY2021_Rx" SG_ 1144 ChrgNowEvnt_B_Stat 1;
BA_ "U_CX727_MY2021_Tx" SG_ 589 BattTrac2_Pw_LimChrg 1;
BA_ "U_P702_MY2021_Tx" SG_ 589 BattTrac2_Pw_LimChrg 1;
BA_ "U_CD542_MY2021_Tx" SG_ 589 BattTrac2_Pw_LimChrg 1;
BA_ "U_CX727_MY2021_Tx" SG_ 589 BattTrac2_Pw_LimDchrg 1;
BA_ "U_P702_MY2021_Tx" SG_ 589 BattTrac2_Pw_LimDchrg 1;
BA_ "U_CD542_MY2021_Tx" SG_ 589 BattTrac2_Pw_LimDchrg 1;
BA_ "U_CX727_MY2021_Tx" SG_ 589 BattTrac2_Pw_DchrgInst 1;
BA_ "U_P702_MY2021_Tx" SG_ 589 BattTrac2_Pw_DchrgInst 1;
BA_ "U_CD542_MY2021_Tx" SG_ 589 BattTrac2_Pw_DchrgInst 1;
BA_ "U_CX727_MY2021_Tx" SG_ 589 BattTrac2_Pw_ChrgInst 1;
BA_ "U_P702_MY2021_Tx" SG_ 589 BattTrac2_Pw_ChrgInst 1;
BA_ "U_CD542_MY2021_Tx" SG_ 589 BattTrac2_Pw_ChrgInst 1;
BA_ "U_CX727_MY2021_Rx" SG_ 1081 ChirpRq_No_ActlTrlr_UB 1;
BA_ "U_P702_MY2021_Rx" SG_ 1081 ChirpRq_No_ActlTrlr_UB 1;
BA_ "U_T6_MCA_MY2020_Rx" SG_ 1081 ChirpRq_No_ActlTrlr_UB 1;
BA_ "U_CD542_MY2021_Rx" SG_ 1081 ChirpRq_No_ActlTrlr_UB 1;
BA_ "U_U55X_MY2022_Rx" SG_ 1081 ChirpRq_No_ActlTrlr_UB 1;
BA_ "U_CD764_MY2022_Rx" SG_ 1081 ChirpRq_No_ActlTrlr_UB 1;
BA_ "U_CX727_MY2021_Rx" SG_ 1081 ChirpRq_No_ActlTrlr 1;
BA_ "U_P702_MY2021_Rx" SG_ 1081 ChirpRq_No_ActlTrlr 1;
BA_ "U_T6_MCA_MY2020_Rx" SG_ 1081 ChirpRq_No_ActlTrlr 1;
BA_ "U_CD542_MY2021_Rx" SG_ 1081 ChirpRq_No_ActlTrlr 1;
BA_ "U_U55X_MY2022_Rx" SG_ 1081 ChirpRq_No_ActlTrlr 1;
BA_ "U_CD764_MY2022_Rx" SG_ 1081 ChirpRq_No_ActlTrlr 1;
BA_ "U_CX727_MY2021_Rx" SG_ 1081 Chirp_D_RqTrlr_UB 1;
BA_ "U_P702_MY2021_Rx" SG_ 1081 Chirp_D_RqTrlr_UB 1;
BA_ "U_T6_MCA_MY2020_Rx" SG_ 1081 Chirp_D_RqTrlr_UB 1;
BA_ "U_CD542_MY2021_Rx" SG_ 1081 Chirp_D_RqTrlr_UB 1;
BA_ "U_U55X_MY2022_Rx" SG_ 1081 Chirp_D_RqTrlr_UB 1;
BA_ "U_CD764_MY2022_Rx" SG_ 1081 Chirp_D_RqTrlr_UB 1;
BA_ "GenSigSendType" SG_ 1081 Chirp_D_RqTrlr 3;
BA_ "U_CX727_MY2021_Rx" SG_ 1081 Chirp_D_RqTrlr 1;
BA_ "U_P702_MY2021_Rx" SG_ 1081 Chirp_D_RqTrlr 1;
BA_ "U_T6_MCA_MY2020_Rx" SG_ 1081 Chirp_D_RqTrlr 1;
BA_ "U_CD542_MY2021_Rx" SG_ 1081 Chirp_D_RqTrlr 1;
BA_ "U_U55X_MY2022_Rx" SG_ 1081 Chirp_D_RqTrlr 1;
BA_ "U_CD764_MY2022_Rx" SG_ 1081 Chirp_D_RqTrlr 1;
BA_ "U_CX727_MY2021_Rx" SG_ 1081 RearPassWindowPos_UB 1;
BA_ "U_P702_MY2021_Rx" SG_ 1081 RearPassWindowPos_UB 1;
BA_ "U_T6_MCA_MY2020_Rx" SG_ 1081 RearPassWindowPos_UB 1;
BA_ "U_CD542_MY2021_Rx" SG_ 1081 RearPassWindowPos_UB 1;
BA_ "U_U55X_MY2022_Rx" SG_ 1081 RearPassWindowPos_UB 1;
BA_ "U_CD764_MY2022_Rx" SG_ 1081 RearPassWindowPos_UB 1;
BA_ "WakeupSignal" SG_ 1081 RearPassWindowPos 1;
BA_ "GenSigSendType" SG_ 1081 RearPassWindowPos 3;
BA_ "U_CX727_MY2021_Rx" SG_ 1081 RearPassWindowPos 1;
BA_ "U_P702_MY2021_Rx" SG_ 1081 RearPassWindowPos 1;
BA_ "U_T6_MCA_MY2020_Rx" SG_ 1081 RearPassWindowPos 1;
BA_ "U_CD542_MY2021_Rx" SG_ 1081 RearPassWindowPos 1;
BA_ "U_U55X_MY2022_Rx" SG_ 1081 RearPassWindowPos 1;
BA_ "U_CD764_MY2022_Rx" SG_ 1081 RearPassWindowPos 1;
BA_ "U_CX727_MY2021_Rx" SG_ 1081 RearDriverWindowPos_UB 1;
BA_ "U_P702_MY2021_Rx" SG_ 1081 RearDriverWindowPos_UB 1;
BA_ "U_T6_MCA_MY2020_Rx" SG_ 1081 RearDriverWindowPos_UB 1;
BA_ "U_CD542_MY2021_Rx" SG_ 1081 RearDriverWindowPos_UB 1;
BA_ "U_U55X_MY2022_Rx" SG_ 1081 RearDriverWindowPos_UB 1;
BA_ "U_CD764_MY2022_Rx" SG_ 1081 RearDriverWindowPos_UB 1;
BA_ "WakeupSignal" SG_ 1081 RearDriverWindowPos 1;
BA_ "GenSigSendType" SG_ 1081 RearDriverWindowPos 3;
BA_ "U_CX727_MY2021_Rx" SG_ 1081 RearDriverWindowPos 1;
BA_ "U_P702_MY2021_Rx" SG_ 1081 RearDriverWindowPos 1;
BA_ "U_T6_MCA_MY2020_Rx" SG_ 1081 RearDriverWindowPos 1;
BA_ "U_CD542_MY2021_Rx" SG_ 1081 RearDriverWindowPos 1;
BA_ "U_U55X_MY2022_Rx" SG_ 1081 RearDriverWindowPos 1;
BA_ "U_CD764_MY2022_Rx" SG_ 1081 RearDriverWindowPos 1;
BA_ "U_CX727_MY2021_Rx" SG_ 1081 PassWindowPosition_UB 1;
BA_ "U_P702_MY2021_Rx" SG_ 1081 PassWindowPosition_UB 1;
BA_ "U_T6_MCA_MY2020_Rx" SG_ 1081 PassWindowPosition_UB 1;
BA_ "U_CD542_MY2021_Rx" SG_ 1081 PassWindowPosition_UB 1;
BA_ "U_U55X_MY2022_Rx" SG_ 1081 PassWindowPosition_UB 1;
BA_ "U_CD764_MY2022_Rx" SG_ 1081 PassWindowPosition_UB 1;
BA_ "WakeupSignal" SG_ 1081 PassWindowPosition 1;
BA_ "GenSigSendType" SG_ 1081 PassWindowPosition 3;
BA_ "U_CX727_MY2021_Rx" SG_ 1081 PassWindowPosition 1;
BA_ "U_P702_MY2021_Rx" SG_ 1081 PassWindowPosition 1;
BA_ "U_T6_MCA_MY2020_Rx" SG_ 1081 PassWindowPosition 1;
BA_ "U_CD542_MY2021_Rx" SG_ 1081 PassWindowPosition 1;
BA_ "U_U55X_MY2022_Rx" SG_ 1081 PassWindowPosition 1;
BA_ "U_CD764_MY2022_Rx" SG_ 1081 PassWindowPosition 1;
BA_ "U_CX727_MY2021_Rx" SG_ 1081 DriverWindowPosition_UB 1;
BA_ "U_P702_MY2021_Rx" SG_ 1081 DriverWindowPosition_UB 1;
BA_ "U_T6_MCA_MY2020_Rx" SG_ 1081 DriverWindowPosition_UB 1;
BA_ "U_CD542_MY2021_Rx" SG_ 1081 DriverWindowPosition_UB 1;
BA_ "U_U55X_MY2022_Rx" SG_ 1081 DriverWindowPosition_UB 1;
BA_ "U_CD764_MY2022_Rx" SG_ 1081 DriverWindowPosition_UB 1;
BA_ "WakeupSignal" SG_ 1081 DriverWindowPosition 1;
BA_ "GenSigSendType" SG_ 1081 DriverWindowPosition 3;
BA_ "U_CX727_MY2021_Rx" SG_ 1081 DriverWindowPosition 1;
BA_ "U_P702_MY2021_Rx" SG_ 1081 DriverWindowPosition 1;
BA_ "U_T6_MCA_MY2020_Rx" SG_ 1081 DriverWindowPosition 1;
BA_ "U_CD542_MY2021_Rx" SG_ 1081 DriverWindowPosition 1;
BA_ "U_U55X_MY2022_Rx" SG_ 1081 DriverWindowPosition 1;
BA_ "U_CD764_MY2022_Rx" SG_ 1081 DriverWindowPosition 1;
BA_ "GenSigSendType" SG_ 1081 ChrgCrdLckEnbl_B_Stat 3;
BA_ "U_CX727_MY2021_Rx" SG_ 1081 EcoInhbt_B_RqHvac_UB 1;
BA_ "U_P702_MY2021_Rx" SG_ 1081 EcoInhbt_B_RqHvac_UB 1;
BA_ "U_T6_MCA_MY2020_Rx" SG_ 1081 EcoInhbt_B_RqHvac_UB 1;
BA_ "U_CD542_MY2021_Rx" SG_ 1081 EcoInhbt_B_RqHvac_UB 1;
BA_ "U_U55X_MY2022_Rx" SG_ 1081 EcoInhbt_B_RqHvac_UB 1;
BA_ "U_CD764_MY2022_Rx" SG_ 1081 EcoInhbt_B_RqHvac_UB 1;
BA_ "U_CX727_MY2021_Rx" SG_ 1081 EmgcyAsstActv_D_Stat_UB 1;
BA_ "U_P702_MY2021_Rx" SG_ 1081 EmgcyAsstActv_D_Stat_UB 1;
BA_ "U_T6_MCA_MY2020_Rx" SG_ 1081 EmgcyAsstActv_D_Stat_UB 1;
BA_ "U_CD542_MY2021_Rx" SG_ 1081 EmgcyAsstActv_D_Stat_UB 1;
BA_ "U_U55X_MY2022_Rx" SG_ 1081 EmgcyAsstActv_D_Stat_UB 1;
BA_ "U_CD764_MY2022_Rx" SG_ 1081 EmgcyAsstActv_D_Stat_UB 1;
BA_ "GenSigSendType" SG_ 1081 EmgcyAsstActv_D_Stat 3;
BA_ "U_CX727_MY2021_Rx" SG_ 1081 EmgcyAsstActv_D_Stat 1;
BA_ "U_P702_MY2021_Rx" SG_ 1081 EmgcyAsstActv_D_Stat 1;
BA_ "U_T6_MCA_MY2020_Rx" SG_ 1081 EmgcyAsstActv_D_Stat 1;
BA_ "U_CD542_MY2021_Rx" SG_ 1081 EmgcyAsstActv_D_Stat 1;
BA_ "U_U55X_MY2022_Rx" SG_ 1081 EmgcyAsstActv_D_Stat 1;
BA_ "U_CD764_MY2022_Rx" SG_ 1081 EmgcyAsstActv_D_Stat 1;
BA_ "U_CX727_MY2021_Rx" SG_ 1081 TrlrHitchLamp_D_Rq2_UB 1;
BA_ "U_P702_MY2021_Rx" SG_ 1081 TrlrHitchLamp_D_Rq2_UB 1;
BA_ "U_T6_MCA_MY2020_Rx" SG_ 1081 TrlrHitchLamp_D_Rq2_UB 1;
BA_ "U_U55X_MY2022_Rx" SG_ 1081 TrlrHitchLamp_D_Rq2_UB 1;
BA_ "U_CD764_MY2022_Rx" SG_ 1081 TrlrHitchLamp_D_Rq2_UB 1;
BA_ "GenSigSendType" SG_ 1081 TrlrHitchLamp_D_Rq2 3;
BA_ "U_CX727_MY2021_Rx" SG_ 1081 TrlrHitchLamp_D_Rq2 1;
BA_ "U_P702_MY2021_Rx" SG_ 1081 TrlrHitchLamp_D_Rq2 1;
BA_ "U_T6_MCA_MY2020_Rx" SG_ 1081 TrlrHitchLamp_D_Rq2 1;
BA_ "U_U55X_MY2022_Rx" SG_ 1081 TrlrHitchLamp_D_Rq2 1;
BA_ "U_CD764_MY2022_Rx" SG_ 1081 TrlrHitchLamp_D_Rq2 1;
BA_ "GenSigSendType" SG_ 1081 EcoInhbt_B_RqHvac 3;
BA_ "U_CX727_MY2021_Rx" SG_ 1081 EcoInhbt_B_RqHvac 1;
BA_ "U_P702_MY2021_Rx" SG_ 1081 EcoInhbt_B_RqHvac 1;
BA_ "U_T6_MCA_MY2020_Rx" SG_ 1081 EcoInhbt_B_RqHvac 1;
BA_ "U_CD542_MY2021_Rx" SG_ 1081 EcoInhbt_B_RqHvac 1;
BA_ "U_U55X_MY2022_Rx" SG_ 1081 EcoInhbt_B_RqHvac 1;
BA_ "U_CD764_MY2022_Rx" SG_ 1081 EcoInhbt_B_RqHvac 1;
BA_ "WakeupSignal" SG_ 810 VehHorn_B_RqOccAlrt 1;
BA_ "GenSigSendType" SG_ 810 VehHorn_B_RqOccAlrt 3;
BA_ "ECGUsedTxSignal" SG_ 810 VehHorn_B_RqOccAlrt 1;
BA_ "U_CD764_MY2022_Tx" SG_ 810 VehHorn_B_RqOccAlrt 1;
BA_ "GenSigSendType" SG_ 810 DteCldAcceptData_B_Rq 3;
BA_ "ECGUsedTxSignal" SG_ 810 DteCldAcceptData_B_Rq 1;
BA_ "U_CD542_MY2021_Tx" SG_ 810 DteCldAcceptData_B_Rq 1;
BA_ "U_CD764_MY2022_Tx" SG_ 810 DteCldAcceptData_B_Rq 1;
BA_ "GenSigSendType" SG_ 810 RmtViewMde_B_Rq 3;
BA_ "U_CD764_MY2022_Rx" SG_ 810 RmtViewMde_B_Rq 1;
BA_ "ECGUsedTxSignal" SG_ 810 RmtViewMde_B_Rq 1;
BA_ "U_CD542_MY2021_Tx" SG_ 810 RmtViewMde_B_Rq 1;
BA_ "U_CD764_MY2022_Tx" SG_ 810 RmtViewMde_B_Rq 1;
BA_ "WakeupSignal" SG_ 810 ExtLghtDsply_B_StatArb 1;
BA_ "GenSigSendType" SG_ 810 ExtLghtDsply_B_StatArb 3;
BA_ "U_T6_MCA_MY2020_Rx" SG_ 810 ExtLghtDsply_B_StatArb 1;
BA_ "U_U55X_MY2022_Rx" SG_ 810 ExtLghtDsply_B_StatArb 1;
BA_ "U_T6_MCA_MY2020_Tx" SG_ 810 ExtLghtDsply_B_StatArb 1;
BA_ "ECGUsedTxSignal" SG_ 810 ExtLghtDsply_B_StatArb 1;
BA_ "U_CD542_MY2021_Tx" SG_ 810 ExtLghtDsply_B_StatArb 1;
BA_ "U_U55X_MY2022_Tx" SG_ 810 ExtLghtDsply_B_StatArb 1;
BA_ "U_CD764_MY2022_Tx" SG_ 810 ExtLghtDsply_B_StatArb 1;
BA_ "WakeupSignal" SG_ 810 ExtLghtRight_D_RqOta 1;
BA_ "GenSigSendType" SG_ 810 ExtLghtRight_D_RqOta 3;
BA_ "U_T6_MCA_MY2020_Rx" SG_ 810 ExtLghtRight_D_RqOta 1;
BA_ "U_U55X_MY2022_Rx" SG_ 810 ExtLghtRight_D_RqOta 1;
BA_ "U_T6_MCA_MY2020_Tx" SG_ 810 ExtLghtRight_D_RqOta 1;
BA_ "ECGUsedTxSignal" SG_ 810 ExtLghtRight_D_RqOta 1;
BA_ "U_CD542_MY2021_Tx" SG_ 810 ExtLghtRight_D_RqOta 1;
BA_ "U_U55X_MY2022_Tx" SG_ 810 ExtLghtRight_D_RqOta 1;
BA_ "U_CD764_MY2022_Tx" SG_ 810 ExtLghtRight_D_RqOta 1;
BA_ "WakeupSignal" SG_ 810 ExtLghtRear_D_RqOta 1;
BA_ "GenSigSendType" SG_ 810 ExtLghtRear_D_RqOta 3;
BA_ "U_T6_MCA_MY2020_Rx" SG_ 810 ExtLghtRear_D_RqOta 1;
BA_ "U_U55X_MY2022_Rx" SG_ 810 ExtLghtRear_D_RqOta 1;
BA_ "U_T6_MCA_MY2020_Tx" SG_ 810 ExtLghtRear_D_RqOta 1;
BA_ "ECGUsedTxSignal" SG_ 810 ExtLghtRear_D_RqOta 1;
BA_ "U_CD542_MY2021_Tx" SG_ 810 ExtLghtRear_D_RqOta 1;
BA_ "U_U55X_MY2022_Tx" SG_ 810 ExtLghtRear_D_RqOta 1;
BA_ "U_CD764_MY2022_Tx" SG_ 810 ExtLghtRear_D_RqOta 1;
BA_ "GenSigSendType" SG_ 810 DteCldCnclRoute_B_Rq 3;
BA_ "ECGUsedTxSignal" SG_ 810 DteCldCnclRoute_B_Rq 1;
BA_ "U_CD542_MY2021_Tx" SG_ 810 DteCldCnclRoute_B_Rq 1;
BA_ "U_U55X_MY2022_Tx" SG_ 810 DteCldCnclRoute_B_Rq 1;
BA_ "U_CD764_MY2022_Tx" SG_ 810 DteCldCnclRoute_B_Rq 1;
BA_ "WakeupSignal" SG_ 810 PtRmtRprt_D_Stat 1;
BA_ "GenSigSendType" SG_ 810 PtRmtRprt_D_Stat 3;
BA_ "ECGUsedTxSignal" SG_ 810 PtRmtRprt_D_Stat 1;
BA_ "U_CD542_MY2021_Tx" SG_ 810 PtRmtRprt_D_Stat 1;
BA_ "U_U55X_MY2022_Tx" SG_ 810 PtRmtRprt_D_Stat 1;
BA_ "U_CD764_MY2022_Tx" SG_ 810 PtRmtRprt_D_Stat 1;
BA_ "WakeupSignal" SG_ 810 NtfyDrvTrgtDist_L_Rq 1;
BA_ "GenSigStartValueInteger" SG_ 810 NtfyDrvTrgtDist_L_Rq 1;
BA_ "GenSigStartValue" SG_ 810 NtfyDrvTrgtDist_L_Rq 4095;
BA_ "GenSigSendType" SG_ 810 NtfyDrvTrgtDist_L_Rq 3;
BA_ "ECGUsedTxSignal" SG_ 810 NtfyDrvTrgtDist_L_Rq 1;
BA_ "U_CD542_MY2021_Tx" SG_ 810 NtfyDrvTrgtDist_L_Rq 1;
BA_ "U_U55X_MY2022_Tx" SG_ 810 NtfyDrvTrgtDist_L_Rq 1;
BA_ "U_CD764_MY2022_Tx" SG_ 810 NtfyDrvTrgtDist_L_Rq 1;
BA_ "WakeupSignal" SG_ 810 NtfyDrvSocLvl1_Pc_Rq 1;
BA_ "GenSigStartValueInteger" SG_ 810 NtfyDrvSocLvl1_Pc_Rq 1;
BA_ "GenSigStartValue" SG_ 810 NtfyDrvSocLvl1_Pc_Rq 127;
BA_ "GenSigSendType" SG_ 810 NtfyDrvSocLvl1_Pc_Rq 3;
BA_ "ECGUsedTxSignal" SG_ 810 NtfyDrvSocLvl1_Pc_Rq 1;
BA_ "U_CD542_MY2021_Tx" SG_ 810 NtfyDrvSocLvl1_Pc_Rq 1;
BA_ "U_U55X_MY2022_Tx" SG_ 810 NtfyDrvSocLvl1_Pc_Rq 1;
BA_ "U_CD764_MY2022_Tx" SG_ 810 NtfyDrvSocLvl1_Pc_Rq 1;
BA_ "GenSigStartValueInteger" SG_ 810 ChrgrPncEnbl_D_Rq 3;
BA_ "GenSigStartValue" SG_ 810 ChrgrPncEnbl_D_Rq 3;
BA_ "GenSigSendType" SG_ 810 ChrgrPncEnbl_D_Rq 3;
BA_ "ECGUsedTxSignal" SG_ 810 ChrgrPncEnbl_D_Rq 1;
BA_ "U_CD542_MY2021_Tx" SG_ 810 ChrgrPncEnbl_D_Rq 1;
BA_ "U_U55X_MY2022_Tx" SG_ 810 ChrgrPncEnbl_D_Rq 1;
BA_ "U_CD764_MY2022_Tx" SG_ 810 ChrgrPncEnbl_D_Rq 1;
BA_ "GenSigSendType" SG_ 810 OBCCSerial_D_Rq 3;
BA_ "ECGUsedTxSignal" SG_ 810 OBCCSerial_D_Rq 1;
BA_ "U_CD542_MY2021_Tx" SG_ 810 OBCCSerial_D_Rq 1;
BA_ "U_U55X_MY2022_Tx" SG_ 810 OBCCSerial_D_Rq 1;
BA_ "U_CD764_MY2022_Tx" SG_ 810 OBCCSerial_D_Rq 1;
BA_ "WakeupSignal" SG_ 810 ExtLghtLeft_D_RqOta 1;
BA_ "GenSigSendType" SG_ 810 ExtLghtLeft_D_RqOta 3;
BA_ "U_T6_MCA_MY2020_Rx" SG_ 810 ExtLghtLeft_D_RqOta 1;
BA_ "U_U55X_MY2022_Rx" SG_ 810 ExtLghtLeft_D_RqOta 1;
BA_ "U_T6_MCA_MY2020_Tx" SG_ 810 ExtLghtLeft_D_RqOta 1;
BA_ "ECGUsedTxSignal" SG_ 810 ExtLghtLeft_D_RqOta 1;
BA_ "U_CD542_MY2021_Tx" SG_ 810 ExtLghtLeft_D_RqOta 1;
BA_ "U_U55X_MY2022_Tx" SG_ 810 ExtLghtLeft_D_RqOta 1;
BA_ "U_CD764_MY2022_Tx" SG_ 810 ExtLghtLeft_D_RqOta 1;
BA_ "WakeupSignal" SG_ 810 ExtLghtFront_D_RqOta 1;
BA_ "GenSigSendType" SG_ 810 ExtLghtFront_D_RqOta 3;
BA_ "U_T6_MCA_MY2020_Rx" SG_ 810 ExtLghtFront_D_RqOta 1;
BA_ "U_U55X_MY2022_Rx" SG_ 810 ExtLghtFront_D_RqOta 1;
BA_ "U_T6_MCA_MY2020_Tx" SG_ 810 ExtLghtFront_D_RqOta 1;
BA_ "ECGUsedTxSignal" SG_ 810 ExtLghtFront_D_RqOta 1;
BA_ "U_CD542_MY2021_Tx" SG_ 810 ExtLghtFront_D_RqOta 1;
BA_ "U_U55X_MY2022_Tx" SG_ 810 ExtLghtFront_D_RqOta 1;
BA_ "U_CD764_MY2022_Tx" SG_ 810 ExtLghtFront_D_RqOta 1;
BA_ "GenSigSendType" SG_ 810 TlghtTest_D_RqArb 3;
BA_ "U_T6_MCA_MY2020_Rx" SG_ 810 TlghtTest_D_RqArb 1;
BA_ "U_U55X_MY2022_Rx" SG_ 810 TlghtTest_D_RqArb 1;
BA_ "U_T6_MCA_MY2020_Tx" SG_ 810 TlghtTest_D_RqArb 1;
BA_ "ECGUsedTxSignal" SG_ 810 TlghtTest_D_RqArb 1;
BA_ "U_CD542_MY2021_Tx" SG_ 810 TlghtTest_D_RqArb 1;
BA_ "U_U55X_MY2022_Tx" SG_ 810 TlghtTest_D_RqArb 1;
BA_ "U_CD764_MY2022_Tx" SG_ 810 TlghtTest_D_RqArb 1;
BA_ "GenSigStartValueInteger" SG_ 810 ChrgrPncSustn_B_Rq 3;
BA_ "GenSigSendType" SG_ 810 ChrgrPncSustn_B_Rq 3;
BA_ "ECGUsedTxSignal" SG_ 810 ChrgrPncSustn_B_Rq 1;
BA_ "U_CD542_MY2021_Tx" SG_ 810 ChrgrPncSustn_B_Rq 1;
BA_ "U_U55X_MY2022_Tx" SG_ 810 ChrgrPncSustn_B_Rq 1;
BA_ "U_CD764_MY2022_Tx" SG_ 810 ChrgrPncSustn_B_Rq 1;
BA_ "GenSigSendType" SG_ 1082 VdmSustnActv_B_Rq 3;
BA_ "U_CX727_MY2021_Rx" SG_ 1082 ChrgStatDsply_D_Rq_UB 1;
BA_ "U_CD542_MY2021_Rx" SG_ 1082 ChrgStatDsply_D_Rq_UB 1;
BA_ "GenSigStartValueInteger" SG_ 1082 ChrgStatDsply_D_Rq 1;
BA_ "GenSigStartValue" SG_ 1082 ChrgStatDsply_D_Rq 1;
BA_ "GenSigSendType" SG_ 1082 ChrgStatDsply_D_Rq 3;
BA_ "U_CX727_MY2021_Rx" SG_ 1082 ChrgStatDsply_D_Rq 1;
BA_ "U_CD542_MY2021_Rx" SG_ 1082 ChrgStatDsply_D_Rq 1;
BA_ "U_CX727_MY2021_Rx" SG_ 1082 ChrgCordUnlock_B_Rq_UB 1;
BA_ "U_CD542_MY2021_Rx" SG_ 1082 ChrgCordUnlock_B_Rq_UB 1;
BA_ "GenSigSendType" SG_ 1082 ChrgCordUnlock_B_Rq 3;
BA_ "U_CX727_MY2021_Rx" SG_ 1082 ChrgCordUnlock_B_Rq 1;
BA_ "U_CD542_MY2021_Rx" SG_ 1082 ChrgCordUnlock_B_Rq 1;
BA_ "U_P702_MY2021_Rx" SG_ 1082 FldngSeatPwOffOk_B_Stat_UB 1;
BA_ "U_T6_MCA_MY2020_Rx" SG_ 1082 FldngSeatPwOffOk_B_Stat_UB 1;
BA_ "WakeupSignal" SG_ 1082 FldngSeatPwOffOk_B_Stat 1;
BA_ "GenSigSendType" SG_ 1082 FldngSeatPwOffOk_B_Stat 3;
BA_ "U_P702_MY2021_Rx" SG_ 1082 FldngSeatPwOffOk_B_Stat 1;
BA_ "U_T6_MCA_MY2020_Rx" SG_ 1082 FldngSeatPwOffOk_B_Stat 1;
BA_ "GenSigSendType" SG_ 1082 EngAirFilt_B_RqReset 3;
BA_ "GenSigSendType" SG_ 1082 TrailCtl_D_Stat 3;
BA_ "U_P702_MY2021_Rx" SG_ 1082 DrLckActv_B_RqBalrr_UB 1;
BA_ "U_T6_MCA_MY2020_Rx" SG_ 1082 DrLckActv_B_RqBalrr_UB 1;
BA_ "U_U55X_MY2022_Rx" SG_ 1082 DrLckActv_B_RqBalrr_UB 1;
BA_ "U_P702_MY2021_Rx" SG_ 1082 DrLckActv_B_RqBalrl_UB 1;
BA_ "U_T6_MCA_MY2020_Rx" SG_ 1082 DrLckActv_B_RqBalrl_UB 1;
BA_ "U_U55X_MY2022_Rx" SG_ 1082 DrLckActv_B_RqBalrl_UB 1;
BA_ "U_P702_MY2021_Rx" SG_ 1082 DrLckCnt_No_ActlBalrr 1;
BA_ "U_T6_MCA_MY2020_Rx" SG_ 1082 DrLckCnt_No_ActlBalrr 1;
BA_ "U_U55X_MY2022_Rx" SG_ 1082 DrLckCnt_No_ActlBalrr 1;
BA_ "U_P702_MY2021_Rx" SG_ 1082 DrLckCnt_No_ActlBalrl 1;
BA_ "U_T6_MCA_MY2020_Rx" SG_ 1082 DrLckCnt_No_ActlBalrl 1;
BA_ "U_U55X_MY2022_Rx" SG_ 1082 DrLckCnt_No_ActlBalrl 1;
BA_ "GenSigSendType" SG_ 1082 DrLckActv_B_RqBalrr 3;
BA_ "U_P702_MY2021_Rx" SG_ 1082 DrLckActv_B_RqBalrr 1;
BA_ "U_T6_MCA_MY2020_Rx" SG_ 1082 DrLckActv_B_RqBalrr 1;
BA_ "U_U55X_MY2022_Rx" SG_ 1082 DrLckActv_B_RqBalrr 1;
BA_ "GenSigSendType" SG_ 1082 DrLckActv_B_RqBalrl 3;
BA_ "U_P702_MY2021_Rx" SG_ 1082 DrLckActv_B_RqBalrl 1;
BA_ "U_T6_MCA_MY2020_Rx" SG_ 1082 DrLckActv_B_RqBalrl 1;
BA_ "U_U55X_MY2022_Rx" SG_ 1082 DrLckActv_B_RqBalrl 1;
BA_ "GenSigSendType" SG_ 1082 EmgcyCall_D_Stat 3;
BA_ "U_CX727_MY2021_Rx" SG_ 1082 EmgcyCall_D_Stat 1;
BA_ "U_P702_MY2021_Rx" SG_ 1082 EmgcyCall_D_Stat 1;
BA_ "U_T6_MCA_MY2020_Rx" SG_ 1082 EmgcyCall_D_Stat 1;
BA_ "U_CD542_MY2021_Rx" SG_ 1082 EmgcyCall_D_Stat 1;
BA_ "U_U55X_MY2022_Rx" SG_ 1082 EmgcyCall_D_Stat 1;
BA_ "U_CD764_MY2022_Rx" SG_ 1082 EmgcyCall_D_Stat 1;
BA_ "U_CX727_MY2021_Rx" SG_ 1082 EmgcyCall_D_Stat_UB 1;
BA_ "U_P702_MY2021_Rx" SG_ 1082 EmgcyCall_D_Stat_UB 1;
BA_ "U_T6_MCA_MY2020_Rx" SG_ 1082 EmgcyCall_D_Stat_UB 1;
BA_ "U_CD542_MY2021_Rx" SG_ 1082 EmgcyCall_D_Stat_UB 1;
BA_ "U_U55X_MY2022_Rx" SG_ 1082 EmgcyCall_D_Stat_UB 1;
BA_ "U_CD764_MY2022_Rx" SG_ 1082 EmgcyCall_D_Stat_UB 1;
BA_ "U_CX727_MY2021_Rx" SG_ 1082 EmPrflNo_D_Rq_UB 1;
BA_ "U_P702_MY2021_Rx" SG_ 1082 EmPrflNo_D_Rq_UB 1;
BA_ "U_T6_MCA_MY2020_Rx" SG_ 1082 EmPrflNo_D_Rq_UB 1;
BA_ "U_CD542_MY2021_Rx" SG_ 1082 EmPrflNo_D_Rq_UB 1;
BA_ "U_U55X_MY2022_Rx" SG_ 1082 EmPrflNo_D_Rq_UB 1;
BA_ "U_CD764_MY2022_Rx" SG_ 1082 EmPrflNo_D_Rq_UB 1;
BA_ "U_CX727_MY2021_Rx" SG_ 1082 EmPrflKeyAssoc_D_Rq_UB 1;
BA_ "U_P702_MY2021_Rx" SG_ 1082 EmPrflKeyAssoc_D_Rq_UB 1;
BA_ "U_T6_MCA_MY2020_Rx" SG_ 1082 EmPrflKeyAssoc_D_Rq_UB 1;
BA_ "U_CD542_MY2021_Rx" SG_ 1082 EmPrflKeyAssoc_D_Rq_UB 1;
BA_ "U_U55X_MY2022_Rx" SG_ 1082 EmPrflKeyAssoc_D_Rq_UB 1;
BA_ "U_CD764_MY2022_Rx" SG_ 1082 EmPrflKeyAssoc_D_Rq_UB 1;
BA_ "GenSigSendType" SG_ 1082 EmPrflNo_D_Rq 3;
BA_ "U_CX727_MY2021_Rx" SG_ 1082 EmPrflNo_D_Rq 1;
BA_ "U_P702_MY2021_Rx" SG_ 1082 EmPrflNo_D_Rq 1;
BA_ "U_T6_MCA_MY2020_Rx" SG_ 1082 EmPrflNo_D_Rq 1;
BA_ "U_CD542_MY2021_Rx" SG_ 1082 EmPrflNo_D_Rq 1;
BA_ "U_U55X_MY2022_Rx" SG_ 1082 EmPrflNo_D_Rq 1;
BA_ "U_CD764_MY2022_Rx" SG_ 1082 EmPrflNo_D_Rq 1;
BA_ "GenSigSendType" SG_ 1082 EmPrflKeyAssoc_D_Rq 3;
BA_ "U_CX727_MY2021_Rx" SG_ 1082 EmPrflKeyAssoc_D_Rq 1;
BA_ "U_P702_MY2021_Rx" SG_ 1082 EmPrflKeyAssoc_D_Rq 1;
BA_ "U_T6_MCA_MY2020_Rx" SG_ 1082 EmPrflKeyAssoc_D_Rq 1;
BA_ "U_CD542_MY2021_Rx" SG_ 1082 EmPrflKeyAssoc_D_Rq 1;
BA_ "U_U55X_MY2022_Rx" SG_ 1082 EmPrflKeyAssoc_D_Rq 1;
BA_ "U_CD764_MY2022_Rx" SG_ 1082 EmPrflKeyAssoc_D_Rq 1;
BA_ "U_CX727_MY2021_Rx" SG_ 1082 CamraViewSplit_B_Rq_UB 1;
BA_ "U_P702_MY2021_Rx" SG_ 1082 CamraViewSplit_B_Rq_UB 1;
BA_ "U_T6_MCA_MY2020_Rx" SG_ 1082 CamraViewSplit_B_Rq_UB 1;
BA_ "U_CD542_MY2021_Rx" SG_ 1082 CamraViewSplit_B_Rq_UB 1;
BA_ "U_U55X_MY2022_Rx" SG_ 1082 CamraViewSplit_B_Rq_UB 1;
BA_ "U_CD764_MY2022_Rx" SG_ 1082 CamraViewSplit_B_Rq_UB 1;
BA_ "WakeupSignal" SG_ 1082 HMI_HMIMode_St 1;
BA_ "GenSigSendType" SG_ 1082 HMI_HMIMode_St 3;
BA_ "U_CX727_MY2021_Rx" SG_ 1082 HMI_HMIMode_St 1;
BA_ "U_P702_MY2021_Rx" SG_ 1082 HMI_HMIMode_St 1;
BA_ "U_T6_MCA_MY2020_Rx" SG_ 1082 HMI_HMIMode_St 1;
BA_ "U_CD542_MY2021_Rx" SG_ 1082 HMI_HMIMode_St 1;
BA_ "U_U55X_MY2022_Rx" SG_ 1082 HMI_HMIMode_St 1;
BA_ "U_CD764_MY2022_Rx" SG_ 1082 HMI_HMIMode_St 1;
BA_ "GenSigSendType" SG_ 1082 CamraViewSplit_B_Rq 3;
BA_ "U_CX727_MY2021_Rx" SG_ 1082 CamraViewSplit_B_Rq 1;
BA_ "U_P702_MY2021_Rx" SG_ 1082 CamraViewSplit_B_Rq 1;
BA_ "U_T6_MCA_MY2020_Rx" SG_ 1082 CamraViewSplit_B_Rq 1;
BA_ "U_CD542_MY2021_Rx" SG_ 1082 CamraViewSplit_B_Rq 1;
BA_ "U_U55X_MY2022_Rx" SG_ 1082 CamraViewSplit_B_Rq 1;
BA_ "U_CD764_MY2022_Rx" SG_ 1082 CamraViewSplit_B_Rq 1;
BA_ "U_CX727_MY2021_Rx" SG_ 1082 HMI_HMIMode_St_UB 1;
BA_ "U_P702_MY2021_Rx" SG_ 1082 HMI_HMIMode_St_UB 1;
BA_ "U_T6_MCA_MY2020_Rx" SG_ 1082 HMI_HMIMode_St_UB 1;
BA_ "U_CD542_MY2021_Rx" SG_ 1082 HMI_HMIMode_St_UB 1;
BA_ "U_U55X_MY2022_Rx" SG_ 1082 HMI_HMIMode_St_UB 1;
BA_ "U_CD764_MY2022_Rx" SG_ 1082 HMI_HMIMode_St_UB 1;
VAL_ 1189 BattTracCellUMx_No_Actl 255 "Faulty" 254 "NoDataExists" ;
VAL_ 1189 BattChrgUMx_B_Falt 1 "Yes" 0 "No" ;
VAL_ 1189 BattTracCellUMn_No_Actl 255 "Faulty" 254 "NoDataExists" ;
VAL_ 1189 BattTracCellCnt_No_Actl 255 "Faulty" 254 "NoDataExists" ;
VAL_ 1189 BattTracCellDiff_B_Falt 1 "Yes" 0 "No" ;
VAL_ 1189 BattChrgSocMx_B_Falt 1 "Yes" 0 "No" ;
VAL_ 1189 BattChrgSocMn_B_Falt 1 "Yes" 0 "No" ;
VAL_ 1189 BattChrgSocErrtc_B_Falt 1 "Yes" 0 "No" ;
VAL_ 1189 BattTracUMx_B_Falt 1 "Yes" 0 "No" ;
VAL_ 1189 BattTracUMn_B_Falt 1 "Yes" 0 "No" ;
VAL_ 1189 BattTracTeMx_No_Actl 255 "Faulty" 254 "NoDataExists" ;
VAL_ 1189 BattTracTeMx_B_Falt 1 "Yes" 0 "No" ;
VAL_ 1189 BattTracTeMn_No_Actl 255 "Faulty" 254 "NoDataExists" ;
VAL_ 1189 BattTracTeDelta_B_Falt 1 "Yes" 0 "No" ;
VAL_ 1189 BattTracTeCnt_No_Actl 255 "Faulty" 254 "NoDataExists" ;
VAL_ 1189 BattTracSoftware_B_Falt 1 "Yes" 0 "No" ;
VAL_ 1188 BattTracTe13_Te_Actl 255 "Faulty" 254 "NoDataExists" ;
VAL_ 1188 BattTracTe12_Te_Actl 255 "Faulty" 254 "NoDataExists" ;
VAL_ 1188 BattTracTe11_Te_Actl 255 "Faulty" 254 "NoDataExists" ;
VAL_ 1188 BattTracTe10_Te_Actl 255 "Faulty" 254 "NoDataExists" ;
VAL_ 1188 BattTracTe09_Te_Actl 255 "Faulty" 254 "NoDataExists" ;
VAL_ 1188 BattTracTe08_Te_Actl 255 "Faulty" 254 "NoDataExists" ;
VAL_ 1188 BattTracTe07_Te_Actl 255 "Faulty" 254 "NoDataExists" ;
VAL_ 1187 BattTracTe06_Te_Actl 255 "Faulty" 254 "NoDataExists" ;
VAL_ 1187 BattTracTe05_Te_Actl 255 "Faulty" 254 "NoDataExists" ;
VAL_ 1187 BattTracTe04_Te_Actl 255 "Faulty" 254 "NoDataExists" ;
VAL_ 1187 BattTracTe03_Te_Actl 255 "Faulty" 254 "NoDataExists" ;
VAL_ 1187 BattTracTe02_Te_Actl 255 "Faulty" 254 "NoDataExists" ;
VAL_ 1187 BattTracTe01_Te_Actl 255 "Faulty" 254 "NoDataExists" ;
VAL_ 1187 BattTracCell96_U_Actl 4095 "Fault" 4094 "NoDataExists" ;
VAL_ 1169 BattTracCell10_U_Actl 4095 "Fault" 4094 "NoDataExists" ;
VAL_ 1169 BattTracCell09_U_Actl 4095 "Fault" 4094 "NoDataExists" ;
VAL_ 1169 BattTracCell08_U_Actl 4095 "Fault" 4094 "NoDataExists" ;
VAL_ 1169 BattTracCell07_U_Actl 4095 "Fault" 4094 "NoDataExists" ;
VAL_ 1169 BattTracCell06_U_Actl 4095 "Fault" 4094 "NoDataExists" ;
VAL_ 1186 BattTracCell95_U_Actl 4095 "Fault" 4094 "NoDataExists" ;
VAL_ 1186 BattTracCell94_U_Actl 4095 "Fault" 4094 "NoDataExists" ;
VAL_ 1186 BattTracCell93_U_Actl 4095 "Fault" 4094 "NoDataExists" ;
VAL_ 1186 BattTracCell92_U_Actl 4095 "Fault" 4094 "NoDataExists" ;
VAL_ 1186 BattTracCell91_U_Actl 4095 "Fault" 4094 "NoDataExists" ;
VAL_ 1185 BattTracCell90_U_Actl 4095 "Fault" 4094 "NoDataExists" ;
VAL_ 1185 BattTracCell89_U_Actl 4095 "Fault" 4094 "NoDataExists" ;
VAL_ 1185 BattTracCell88_U_Actl 4095 "Fault" 4094 "NoDataExists" ;
VAL_ 1185 BattTracCell87_U_Actl 4095 "Fault" 4094 "NoDataExists" ;
VAL_ 1185 BattTracCell86_U_Actl 4095 "Fault" 4094 "NoDataExists" ;
VAL_ 1184 BattTracCell85_U_Actl 4095 "Fault" 4094 "NoDataExists" ;
VAL_ 1184 BattTracCell84_U_Actl 4095 "Fault" 4094 "NoDataExists" ;
VAL_ 1184 BattTracCell83_U_Actl 4095 "Fault" 4094 "NoDataExists" ;
VAL_ 1184 BattTracCell82_U_Actl 4095 "Fault" 4094 "NoDataExists" ;
VAL_ 1184 BattTracCell81_U_Actl 4095 "Fault" 4094 "NoDataExists" ;
VAL_ 1183 BattTracCell80_U_Actl 4095 "Fault" 4094 "NoDataExists" ;
VAL_ 1183 BattTracCell79_U_Actl 4095 "Fault" 4094 "NoDataExists" ;
VAL_ 1183 BattTracCell78_U_Actl 4095 "Fault" 4094 "NoDataExists" ;
VAL_ 1183 BattTracCell77_U_Actl 4095 "Fault" 4094 "NoDataExists" ;
VAL_ 1183 BattTracCell76_U_Actl 4095 "Fault" 4094 "NoDataExists" ;
VAL_ 1182 BattTracCell75_U_Actl 4095 "Fault" 4094 "NoDataExists" ;
VAL_ 1182 BattTracCell74_U_Actl 4095 "Fault" 4094 "NoDataExists" ;
VAL_ 1182 BattTracCell73_U_Actl 4095 "Fault" 4094 "NoDataExists" ;
VAL_ 1182 BattTracCell72_U_Actl 4095 "Fault" 4094 "NoDataExists" ;
VAL_ 1182 BattTracCell71_U_Actl 4095 "Fault" 4094 "NoDataExists" ;
VAL_ 1181 BattTracCell70_U_Actl 4095 "Fault" 4094 "NoDataExists" ;
VAL_ 1181 BattTracCell69_U_Actl 4095 "Fault" 4094 "NoDataExists" ;
VAL_ 1181 BattTracCell68_U_Actl 4095 "Fault" 4094 "NoDataExists" ;
VAL_ 1181 BattTracCell67_U_Actl 4095 "Fault" 4094 "NoDataExists" ;
VAL_ 1181 BattTracCell66_U_Actl 4095 "Fault" 4094 "NoDataExists" ;
VAL_ 1180 BattTracCell65_U_Actl 4095 "Fault" 4094 "NoDataExists" ;
VAL_ 1180 BattTracCell64_U_Actl 4095 "Fault" 4094 "NoDataExists" ;
VAL_ 1180 BattTracCell63_U_Actl 4095 "Fault" 4094 "NoDataExists" ;
VAL_ 1180 BattTracCell62_U_Actl 4095 "Fault" 4094 "NoDataExists" ;
VAL_ 1180 BattTracCell61_U_Actl 4095 "Fault" 4094 "NoDataExists" ;
VAL_ 1179 BattTracCell60_U_Actl 4095 "Fault" 4094 "NoDataExists" ;
VAL_ 1179 BattTracCell59_U_Actl 4095 "Fault" 4094 "NoDataExists" ;
VAL_ 1179 BattTracCell58_U_Actl 4095 "Fault" 4094 "NoDataExists" ;
VAL_ 1179 BattTracCell57_U_Actl 4095 "Fault" 4094 "NoDataExists" ;
VAL_ 1179 BattTracCell56_U_Actl 4095 "Fault" 4094 "NoDataExists" ;
VAL_ 1178 BattTracCell55_U_Actl 4095 "Fault" 4094 "NoDataExists" ;
VAL_ 1178 BattTracCell54_U_Actl 4095 "Fault" 4094 "NoDataExists" ;
VAL_ 1178 BattTracCell53_U_Actl 4095 "Fault" 4094 "NoDataExists" ;
VAL_ 1178 BattTracCell52_U_Actl 4095 "Fault" 4094 "NoDataExists" ;
VAL_ 1178 BattTracCell51_U_Actl 4095 "Fault" 4094 "NoDataExists" ;
VAL_ 1177 BattTracCell50_U_Actl 4095 "Fault" 4094 "NoDataExists" ;
VAL_ 1177 BattTracCell49_U_Actl 4095 "Fault" 4094 "NoDataExists" ;
VAL_ 1177 BattTracCell48_U_Actl 4095 "Fault" 4094 "NoDataExists" ;
VAL_ 1177 BattTracCell47_U_Actl 4095 "Fault" 4094 "NoDataExists" ;
VAL_ 1177 BattTracCell46_U_Actl 4095 "Fault" 4094 "NoDataExists" ;
VAL_ 1168 BattTracCell05_U_Actl 4095 "Fault" 4094 "NoDataExists" ;
VAL_ 1168 BattTracCell04_U_Actl 4095 "Fault" 4094 "NoDataExists" ;
VAL_ 1168 BattTracCell03_U_Actl 4095 "Fault" 4094 "NoDataExists" ;
VAL_ 1168 BattTracCell02_U_Actl 4095 "Fault" 4094 "NoDataExists" ;
VAL_ 1168 BattTracCell01_U_Actl 4095 "Fault" 4094 "NoDataExists" ;
VAL_ 1092 BattTracCell_U_Mx 16383 "Faulty" ;
VAL_ 1092 BattTracMnCell_Te_Actl 255 "Faulty" 254 "NoDataExists" ;
VAL_ 1092 BattTracInsAlrm_B_Stat 1 "Active" 0 "Inactive" ;
VAL_ 1092 BattTracUMx_B_Stat 1 "Active" 0 "Inactive" ;
VAL_ 1092 BattTracMxCell_Te_Actl 255 "Faulty" 254 "NoDataExists" ;
VAL_ 1092 BattTracEq_B_Actl 1 "Active" 0 "Inactive" ;
VAL_ 1092 BattTracCell_U_Mn 16383 "Faulty" ;
VAL_ 1092 BattTracUMn_B_Stat 1 "Active" 0 "Inactive" ;
VAL_ 1092 BattTracUAlrm_B_Stat 1 "Active" 0 "Inactive" ;
VAL_ 1092 BattTracInsltn_R_Actl 255 "Faulty" ;
VAL_ 513 BptRngeRsrvMet_B_Stat 1 "Yes" 0 "No" ;
VAL_ 513 BptPwOut_B_Dsply 1 "Yes" 0 "No" ;
VAL_ 513 BptStrtStop_D_Stat 3 "NotUsed_1" 2 "Start" 1 "Stop" 0 "NoRequest" ;
VAL_ 513 BptComm_D_RqHtrn 9 "EnergyTransferFault" 8 "EnergyTransferEnd" 7 "VehicleEnergyTransferActv" 6 "VehicleEnergyTransferReady" 5 "VehiclePreChargeReady" 4 "VehicleEnergyTransferWait" 3 "ConfirmConnection" 2 "VehicleReadyToToggle" 1 "AttemptDgtlCommunication" 0 "NoDigitalCommunication" 15 "NotUsed_6" 14 "NotUsed_5" 13 "NotUsed_4" 12 "NotUsed_3" 11 "NotUsed_2" 10 "NotUsed_1" ;
VAL_ 513 BptSustn_B_Rq 1 "Active" 0 "Inactive" ;
VAL_ 513 GridSrvc01_B_Stat 1 "On" 0 "Off" ;
VAL_ 513 BptMde_D_Stat 7 "NotUsed_4" 6 "NotUsed_3" 5 "NotUsed_2" 4 "NotUsed_1" 3 "Automatic" 2 "Manual" 1 "Off" 0 "Null" ;
VAL_ 513 Bpt_D_StatHtrn 15 "Faulty" 14 "NotUsed_8" 13 "NotUsed_7" 12 "NotUsed_6" 11 "NotUsed_5" 10 "NotUsed_4" 9 "NotUsed_3" 8 "NotUsed_2" 7 "NotUsed_1" 6 "VehicleFault" 5 "EvseFault" 4 "BptActive" 3 "Precharge" 2 "BptReady" 1 "Initialization" 0 "NotReady" ;
VAL_ 513 BattTracTeColr_D_Dsply 3 "NotUsed" 2 "ColorForSeverlyLimited" 1 "ColorForLimited" 0 "ColorForNormal" ;
VAL_ 513 MtrTracTeColr_D_Dsply 3 "NotUsed" 2 "ColorForSeverlyLimited" 1 "ColorForLimited" 0 "ColorForNormal" ;
VAL_ 650 BptTglCnt_No_Rq 15 "Faulty" 14 "NoDataExists" ;
VAL_ 650 BptIsol_D_Stat 7 "Faulty" 6 "NoDataExists" 5 "NotUsed_3" 4 "NotUsed_2" 3 "NotUsed_1" 2 "Valid" 1 "Warning" 0 "Invalid" ;
VAL_ 650 Bpt_D_StatEvse 15 "Faulty" 14 "NoDataExists" 13 "NotUsed_6" 12 "NotUsed_5" 11 "NotUsed_4" 10 "NotUsed_3" 9 "NotUsed_2" 8 "NotUsed_1" 7 "EvseFault" 6 "EvseEnergyTransferActive" 5 "EvsePreChargeReady" 4 "EvseBptReady" 3 "ConnectionTglNotConfirmed" 2 "ConnectionTglConfirmed" 1 "Initialization" 0 "NotReady" ;
VAL_ 650 BptTgl_D_Rq 3 "Faulty" 2 "NoDataExists" 1 "Request" 0 "NoRequest" ;
VAL_ 650 BattTracIsoDis_D_RqBpt 3 "Faulty" 2 "NoDataExists" 1 "Yes" 0 "No" ;
VAL_ 655 EvseChrgOutHi_U_ActlBpt 1023 "Faulty" 1022 "NoDataExists" ;
VAL_ 655 EvseChrgOutHi_I_ActlBpt 32767 "Faulty" 32766 "NoDataExists" ;
VAL_ 655 EvseDchrg_Pw_Mx 32767 "Faulty" 32766 "NoDataExists" ;
VAL_ 655 EvseDchrg_I_Mx 32767 "Faulty" 32766 "NoDataExists" ;
VAL_ 599 Bpt_D_StatBattTrac 7 "Faulty" 6 "NotUsed_3" 5 "NotUsed_2" 4 "NotUsed_1" 3 "Active" 2 "Ready" 1 "Wait" 0 "NotReady" ;
VAL_ 749 ChrgrSysFalt18_D_Stat 3 "NotUsed" 2 "Pass" 1 "Fail" 0 "NotDiagnoseYet" ;
VAL_ 749 ChrgrSysFalt17_D_Stat 3 "NotUsed" 2 "Pass" 1 "Fail" 0 "NotDiagnoseYet" ;
VAL_ 749 ChrgrSysFalt16_D_Stat 3 "NotUsed" 2 "Pass" 1 "Fail" 0 "NotDiagnoseYet" ;
VAL_ 749 ChrgrSysFalt15_D_Stat 3 "NotUsed" 2 "Pass" 1 "Fail" 0 "NotDiagnoseYet" ;
VAL_ 749 ChrgrSysFalt14_D_Stat 3 "NotUsed" 2 "Pass" 1 "Fail" 0 "NotDiagnoseYet" ;
VAL_ 749 ChrgrSysFalt13_D_Stat 3 "NotUsed" 2 "Pass" 1 "Fail" 0 "NotDiagnoseYet" ;
VAL_ 749 ChrgrSysFalt12_D_Stat 3 "NotUsed" 2 "Pass" 1 "Fail" 0 "NotDiagnoseYet" ;
VAL_ 749 ChrgrSysFalt11_D_Stat 3 "NotUsed" 2 "Pass" 1 "Fail" 0 "NotDiagnoseYet" ;
VAL_ 749 ChrgrSysFalt9_D_Stat 3 "NotUsed" 2 "Pass" 1 "Fail" 0 "NotDiagnoseYet" ;
VAL_ 749 ChrgrSysFalt8_D_Stat 3 "NotUsed" 2 "Pass" 1 "Fail" 0 "NotDiagnoseYet" ;
VAL_ 749 ChrgrSysFalt7_D_Stat 3 "NotUsed" 2 "Pass" 1 "Fail" 0 "NotDiagnoseYet" ;
VAL_ 749 ChrgrSysFalt6_D_Stat 3 "NotUsed" 2 "Pass" 1 "Fail" 0 "NotDiagnoseYet" ;
VAL_ 749 ChrgrSysFalt5_D_Stat 3 "NotUsed" 2 "Pass" 1 "Fail" 0 "NotDiagnoseYet" ;
VAL_ 749 ChrgrSysFalt4_D_Stat 3 "NotUsed" 2 "Pass" 1 "Fail" 0 "NotDiagnoseYet" ;
VAL_ 749 ChrgrSysFalt3_D_Stat 3 "NotUsed" 2 "Pass" 1 "Fail" 0 "NotDiagnoseYet" ;
VAL_ 749 ChrgrSysFalt2_D_Stat 3 "NotUsed" 2 "Pass" 1 "Fail" 0 "NotDiagnoseYet" ;
VAL_ 749 ChrgrSysFalt1_D_Stat 3 "NotUsed" 2 "Pass" 1 "Fail" 0 "NotDiagnoseYet" ;
VAL_ 749 ChrgrSysFalt10_D_Stat 3 "NotUsed" 2 "Pass" 1 "Fail" 0 "NotDiagnoseYet" ;
VAL_ 580 BattTracVrtOck_B_Rq 1 "Yes" 0 "No" ;
VAL_ 1012 ChrgLocSaved_B_Dsply 1 "Yes" 0 "No" ;
VAL_ 1012 ChrgLocLongPostv_B_Sav 1 "Yes" 0 "No" ;
VAL_ 1012 ChrgLocLattPostv_B_Sav 1 "Yes" 0 "No" ;
VAL_ 1012 AirCondRec_B_RqVehEl 1 "Yes" 0 "No" ;
VAL_ 1012 ChrgNowCurnt_B_Dsply 1 "On" 0 "Off" ;
VAL_ 1149 BattTracPerf_Pc_Dsply 255 "Faulty" 254 "NoDataExists" ;
VAL_ 1149 BattTracPerf_Pc_Actl 255 "Faulty" 254 "NoDataExists" ;
VAL_ 770 BattTracVrtOck_B_Stat 1 "Yes" 0 "No" ;
VAL_ 770 ScEnbl_B_Stat 1 "On" 0 "Off" ;
VAL_ 123 BattTrac_U2_Actl 4095 "Faulty" 4094 "NoDataExists" ;
VAL_ 123 BattTrac_I2_Actl 262143 "Faulty" 262142 "NoDataExists" ;
VAL_ 1160 ReFuelSwtchStat_D_Actl2 3 "NotUsed_2" 2 "NotUsed_1" 1 "On" 0 "Off" ;
VAL_ 1160 DgtlCommPncReset_B_Req 1 "Yes" 0 "No" ;
VAL_ 1160 DgtlCommPnc_D_Rq 3 "DeleteAll" 2 "Disable" 1 "Reset" 0 "NoRequest" ;
VAL_ 1160 PwSustnRdata_B_RqTelem 1 "Active" 0 "Inactive" ;
VAL_ 1160 DataMntrSustn_B_Rq 1 "Active" 0 "Inactive" ;
VAL_ 1119 CoolFanDcdc_D_Rq 3 "High" 2 "Medium" 1 "Low" 0 "Off" ;
VAL_ 1119 DcdcClntFlw_D_Rq 3 "High" 2 "Medium" 1 "Low" 0 "Off" ;
VAL_ 1152 PwOutlet8EnblScnd_B_Rq 1 "Enable" 0 "Disable" ;
VAL_ 1152 PwOutlet8Enbl_B_Rq 1 "Enable" 0 "Disable" ;
VAL_ 1152 PwOutlet7EnblScnd_B_Rq 1 "Enable" 0 "Disable" ;
VAL_ 1152 PwOutlet7Enbl_B_Rq 1 "Enable" 0 "Disable" ;
VAL_ 1152 PwOutlet6EnblScnd_B_Rq 1 "Enable" 0 "Disable" ;
VAL_ 1152 PwOutlet6Enbl_B_Rq 1 "Enable" 0 "Disable" ;
VAL_ 1152 PwCabinEnblScnd_B_Rq 1 "Enable" 0 "Disable" ;
VAL_ 1152 PwCabinEnbl_B_Rq 1 "Enable" 0 "Disable" ;
VAL_ 1152 PwTrnkFrntEnblScnd_B_Rq 1 "Enable" 0 "Disable" ;
VAL_ 1152 PwTrnkFrntEnbl_B_Rq 1 "Enable" 0 "Disable" ;
VAL_ 1152 OnePdlDrvLamp_B_Rq 1 "On" 0 "Off" ;
VAL_ 1152 OnePdlDrv_D_Dsply 3 "Faulty" 2 "Suspended" 1 "On" 0 "Off" ;
VAL_ 1152 HybPwULoLamp_B_Rq 1 "On" 0 "Off" ;
VAL_ 1152 GrdAsstActv_B_Stat 1 "On" 0 "Off" ;
VAL_ 1152 StopStrtVThres_D_Stat 3 "High" 2 "Medium" 1 "Low" 0 "NoSelection" ;
VAL_ 1152 VehElEff_No_Avg 127 "Faulty" 126 "NoDataExists" ;
VAL_ 1152 EngTeHi_B_Actl 1 "EngineTempHigh" 0 "Normal" ;
VAL_ 1152 DcdcOn_B_Rq 1 "On" 0 "Off" ;
VAL_ 1152 BattTracDiagClr_B_Stat 1 "On" 0 "Off" ;
VAL_ 1152 ULoBattSpprtSustn_B_Rq 1 "Active" 0 "Inactive" ;
VAL_ 1118 AcChrgRdy_B_Stat 1 "True" 0 "False" ;
VAL_ 1118 ExtChrgNowButtn_B_Rq 1 "Request" 0 "NoRequest" ;
VAL_ 1118 CoolFanChrgr_D_Rq 3 "High" 2 "Medium" 1 "Low" 0 "Off" ;
VAL_ 1118 ChrgrClntFlw_D_Rq 3 "High" 2 "Medium" 1 "Low" 0 "Off" ;
VAL_ 1118 PlgStatEvnt_B_Stat 1 "Active" 0 "Inactive" ;
VAL_ 1118 ChrgrCnnctPwr_B_Stat 1 "Asserted" 0 "NotAsserted" ;
VAL_ 1118 ChrgrAvailEvnt_B_Stat 1 "Active" 0 "Inactive" ;
VAL_ 1118 ChrgrSrvcRqd_B_Rq 1 "On" 0 "Off" ;
VAL_ 1118 ChrgrS2Swtch_B_Stat 1 "Close" 0 "Open" ;
VAL_ 1118 ChrgChngEvnt_B_Stat 1 "Active" 0 "Inactive" ;
VAL_ 1118 ChrgCordLck_D_Stat 7 "Faulty" 6 "LockFail" 5 "UnlockFail" 4 "LockInProgress" 3 "UnlockInProgress" 2 "Lock" 1 "Unlock" 0 "Retain" ;
VAL_ 1118 ChrgrInPwMde_D_Actl 15 "NotUsed_5" 14 "NotUsed_4" 13 "NotUsed_3" 12 "NotUsed_2" 11 "NotUsed_1" 10 "DcBpt" 9 "DigitalCommEnd" 8 "EvseFault" 7 "EvseNotCompatible" 6 "IcCharging" 5 "DcCharging" 4 "AcDigital" 3 "AcBasic" 2 "DigitalCommDetected" 1 "EvsePaused" 0 "EvseNotDetected" ;
VAL_ 1118 ChrgPortDrOpen_B_Stat 1 "True" 0 "False" ;
VAL_ 1118 ChrgCrdLck_D_Falt 3 "NotUsed" 2 "HardwareFault" 1 "CsiFault" 0 "NoFault" ;
VAL_ 953 PaakMyKeySearch_D_Stat 7 "PhoneErased" 6 "LockButtonTimeOut" 5 "PressLockButton" 4 "ConfirmHmi" 3 "MyKeyPaakFound" 2 "StandardPaakFound" 1 "NoValidPaakFound" 0 "Null" ;
VAL_ 953 BattULoChrgHyb_D_Stat 7 "NotUsed_4" 6 "NotUsed_3" 5 "NotUsed_2" 4 "NotUsed_1" 3 "VehicleServiceRequired" 2 "EvRangeLossDueToLoadActive" 1 "BatteryServiceRequired" 0 "Null" ;
VAL_ 953 BattULoChrgHyb_B_Rq 1 "True" 0 "False" ;
VAL_ 953 ChrgCordLck_B_Stat 1 "Unlock" 0 "Null" ;
VAL_ 953 WakeAlarm3_D_Stat 3 "PublisherReset" 2 "Wake" 1 "AlarmRunning" 0 "AlarmOff" ;
VAL_ 953 WakeAlarm2_D_Stat 3 "PublisherReset" 2 "Wake" 1 "AlarmRunning" 0 "AlarmOff" ;
VAL_ 953 WakeAlarm1_D_Stat 3 "PublisherReset" 2 "Wake" 1 "AlarmRunning" 0 "AlarmOff" ;
VAL_ 953 WakeAlarm0_D_Stat 3 "PublisherReset" 2 "Wake" 1 "AlarmRunning" 0 "AlarmOff" ;
VAL_ 1112 BattTrac2_E_Max 4095 "Faulty" 4094 "NoDataExists" ;
VAL_ 1112 BattTrac2_E_Avail 4095 "Faulty" 4094 "NoDataExists" ;
VAL_ 1112 BattTracTeEvnt_B_Stat 1 "Active" 0 "Inactive" ;
VAL_ 1112 BattChrgTrgtEvnt_B_Stat 1 "Active" 0 "Inactive" ;
VAL_ 1112 BattTracTeSustn_B_Rq 1 "Active" 0 "Inactive" ;
VAL_ 1112 BattTracChrgSustn_B_Rq 1 "Active" 0 "Inactive" ;
VAL_ 1112 BattTracHeat_D_Rq 3 "Faulty" 2 "NotUsed" 1 "On" 0 "Off" ;
VAL_ 1112 BattTracDcFstSustn_B_Rq 1 "Active" 0 "Inactive" ;
VAL_ 1112 BattTracCnnct_D_Cmd 7 "NotUsed_3" 6 "NotUsed_2" 5 "NotUsed_1" 4 "WeldCheck" 3 "OkToDischarge" 2 "Closed" 1 "Precharge" 0 "Open" ;
VAL_ 1112 BattTracHvilOpen_B_Stat 1 "Open" 0 "Closed" ;
VAL_ 1112 BattTracDcdcDis_B_Rq 1 "Yes" 0 "No" ;
VAL_ 1112 BattTracDiagClr_B_Rq 1 "On" 0 "Off" ;
VAL_ 1112 BattTracHazrd_D_Stat 3 "Disabled" 2 "HazardConfirmed" 1 "ExternalMonitoringRequired" 0 "NoHazardDetected" ;
VAL_ 1112 HtrnClntPump_D_Stat 3 "Faulty" 2 "No_Data_Exists" 1 "On" 0 "Off" ;
VAL_ 1112 BattTracDelta_Te_Actl 255 "Faulty" 254 "NoDataExists" ;
VAL_ 1112 BattTracClntPmp_D_Stat 3 "Faulty" 2 "No_Data_Exists" 1 "On" 0 "Off" ;
VAL_ 1144 AwdLckMde_D_Stat 7 "NotUsed_2" 6 "NotUsed_1" 5 "PrimaryAxleSpeedControl" 4 "DualAxleSpeedControl" 3 "EfficiencySplit" 2 "SecondaryAxleTorqueCtrl" 1 "SecondaryAxleSpeedCtrl" 0 "Off" ;
VAL_ 1144 BattTracCool_B_Actl 1 "On" 0 "Off" ;
VAL_ 1144 BattChrgTrgtSoC_D_Rq 7 "Percent_50" 6 "Percent_60" 5 "Percent_70" 4 "Percent_80" 3 "Percent_85" 2 "Percent_90" 1 "Percent_95" 0 "Percent_100" ;
VAL_ 1144 PreCondBatt_B_Actl 1 "On" 0 "Off" ;
VAL_ 1144 CabnEvapSovFront_B_Rq 1 "On" 0 "Off" ;
VAL_ 1144 HeatCoreSovRear_B_Rq 1 "On" 0 "Off" ;
VAL_ 1144 BattChlrSov_B_Rq 1 "On" 0 "Off" ;
VAL_ 1144 CabnEvapSovRear_B_Rq 1 "On" 0 "Off" ;
VAL_ 1144 BrkAppl_D_RqPt 3 "BrakesSlowRelease" 2 "BrakesFastRelease" 1 "BrakesEngage" 0 "NotActive" ;
VAL_ 1144 BattClntVlvOvrrd_D_Rq 3 "NotUsed" 2 "OverrideTbcvToChiller" 1 "OverrideTbcvToRadiator" 0 "NoOverrideToTbcvCLogic" ;
VAL_ 1144 BattTracChillerOn_B_Rq 1 "On" 0 "Off" ;
VAL_ 1144 BattTracChiller_D_Stat 3 "NotUsed" 2 "ChillerNotAvailable" 1 "ChillerBrieflyAvailable" 0 "ChillerAvailable" ;
VAL_ 1144 ULoBattTrnsfrSustn_B_Rq 1 "Active" 0 "Inactive" ;
VAL_ 1144 ULoBattTransfer_D_Stat 7 "NotUsed_2" 6 "NotUsed_1" 5 "TransferError" 4 "TransferComplete" 3 "TransferThroughGridEnergy" 2 "InsufficientEnergyToXfer" 1 "TransferInProgress" 0 "NoTransfer" ;
VAL_ 1144 HtrnDcdcDis_B_Rq 1 "Yes" 0 "No" ;
VAL_ 1144 HtrnCnnctPwr_B_Stat 1 "Asserted" 0 "NotAsserted" ;
VAL_ 1144 PtcHtr_D_Stat 3 "Faulty" 2 "NotUsed" 1 "On" 0 "Off" ;
VAL_ 1144 BattChrgInhbt_D2_Rq 7 "NotUsed_4" 6 "NotUsed_3" 5 "NotUsed_2" 4 "NotUsed_1" 3 "MaintainTargetSoc" 2 "EndAtTarget" 1 "InhibitCharging" 0 "Enable_Charging" ;
VAL_ 1144 WakeAlarm0_B_Typ 1 "CanAndEcuDriveCircuit" 0 "CanOnly" ;
VAL_ 1144 BattTracClimtDis_B_Stat 1 "Enable" 0 "Disable" ;
VAL_ 1144 HtrnClntFlw_D_Rq 3 "High" 2 "Medium" 1 "Low" 0 "Off" ;
VAL_ 1144 BattTracDrvSustn_B_Rq 1 "Active" 0 "Inactive" ;
VAL_ 1144 CabinDrvSustn_B_Rq 1 "Active" 0 "Inactive" ;
VAL_ 1144 BattTracClntVlv_B_Rq 1 "On" 0 "Off" ;
VAL_ 1144 ChrgNowEvnt_B_Stat 1 "Active" 0 "Inactive" ;
VAL_ 1081 ChirpRq_No_ActlTrlr_UB 1 "Fresh_data" 0 "Unchanged_data" ;
VAL_ 1081 Chirp_D_RqTrlr_UB 1 "Fresh_data" 0 "Unchanged_data" ;
VAL_ 1081 Chirp_D_RqTrlr 3 "NotUsed" 2 "Chirp_2" 1 "Chirp_1" 0 "NoRequest" ;
VAL_ 1081 RearPassWindowPos_UB 1 "Fresh_data" 0 "Unchanged_data" ;
VAL_ 1081 RearPassWindowPos 7 "Unused2" 6 "Unused1" 5 "Fully_Open" 4 "Bet60Percent_FullyOpen" 3 "Bet10Percent_60Percent" 2 "BetFully_10PercentOpen" 1 "Fully_Closed" 0 "Undefined" ;
VAL_ 1081 RearDriverWindowPos_UB 1 "Fresh_data" 0 "Unchanged_data" ;
VAL_ 1081 RearDriverWindowPos 7 "Unused2" 6 "Unused1" 5 "Fully_Open" 4 "Bet60Percent_FullyOpen" 3 "Bet10Percent_60Percent" 2 "BetFully_10PercentOpen" 1 "Fully_Closed" 0 "Undefined" ;
VAL_ 1081 PassWindowPosition_UB 1 "Fresh_data" 0 "Unchanged_data" ;
VAL_ 1081 PassWindowPosition 7 "Unused2" 6 "Unused1" 5 "Fully_Open" 4 "Bet60Percent_FullyOpen" 3 "Bet10Percent_60Percent" 2 "BetFully_10PercentOpen" 1 "Fully_Closed" 0 "Undefined" ;
VAL_ 1081 DriverWindowPosition_UB 1 "Fresh_data" 0 "Unchanged_data" ;
VAL_ 1081 DriverWindowPosition 7 "Unused2" 6 "Unused1" 5 "Fully_Open" 4 "Bet60Percent_FullyOpen" 3 "Bet10Percent_60Percent" 2 "BetFully_10PercentOpen" 1 "Fully_Closed" 0 "Undefined" ;
VAL_ 1081 ChrgCrdLckEnbl_B_Stat 1 "Enable" 0 "Disable" ;
VAL_ 1081 ChrgCrdLckEnbl_B_Stat_UB 1 "Fresh_data" 0 "Unchanged_data" ;
VAL_ 1081 EcoInhbt_B_RqHvac_UB 1 "Fresh_data" 0 "Unchanged_data" ;
VAL_ 1081 EmgcyAsstActv_D_Stat_UB 1 "Fresh_data" 0 "Unchanged_data" ;
VAL_ 1081 EmgcyAsstActv_D_Stat 3 "ConfiguredOff" 2 "Active" 1 "Inactive" 0 "Null" ;
VAL_ 1081 TrlrHitchLamp_D_Rq2_UB 1 "Fresh_data" 0 "Unchanged_data" ;
VAL_ 1081 TrlrHitchLamp_D_Rq2 1 "On" 0 "Off" ;
VAL_ 1081 EcoInhbt_B_RqHvac 1 "Yes" 0 "No" ;
VAL_ 810 VehHorn_B_RqOccAlrt 1 "On" 0 "Off" ;
VAL_ 810 DteCldAcceptData_B_Rq 1 "Yes" 0 "No" ;
VAL_ 810 RmtViewMde_B_Rq 1 "On" 0 "Off" ;
VAL_ 810 ExtLghtDsply_B_StatArb 1 "On" 0 "Off" ;
VAL_ 810 ExtLghtRight_D_RqOta 7 "NotUsed" 6 "PressToOn3" 5 "PressToOff3" 4 "PressToOn2" 3 "PressToOff2" 2 "PressToOn1" 1 "PressToOff1" 0 "Reset" ;
VAL_ 810 ExtLghtRear_D_RqOta 7 "NotUsed" 6 "PressToOn3" 5 "PressToOff3" 4 "PressToOn2" 3 "PressToOff2" 2 "PressToOn1" 1 "PressToOff1" 0 "Reset" ;
VAL_ 810 DteCldCnclRoute_B_Rq 1 "Yes" 0 "No" ;
VAL_ 810 PtRmtRprt_D_Stat 15 "NotUsed_4" 14 "NotUsed_3" 13 "NotUsed_2" 12 "PlugInToMaintain12vBattery" 11 "SettingUpdated" 10 "FastChargeComplete" 9 "ChargeNotOccurring" 8 "OneTimeSocReached" 7 "BatteryTemperatureRemind" 6 "ReducedPerformance" 5 "LimitedPerformance" 4 "ChargeFault" 3 "ChargeComplete" 2 "VehiclePreconditioned" 1 "TripDistanceAchieved" 0 "NoReportRequest" ;
VAL_ 810 ChrgrPncEnbl_D_Rq 3 "NotUsed" 2 "Enable" 1 "Disable" 0 "Null" ;
VAL_ 810 OBCCSerial_D_Rq 3 "PresentAndProvisioned" 2 "PresentAndProvAlertAck" 1 "PresentAndUnprovisioned" 0 "NotPresent" ;
VAL_ 810 ExtLghtLeft_D_RqOta 7 "NotUsed" 6 "PressToOn3" 5 "PressToOff3" 4 "PressToOn2" 3 "PressToOff2" 2 "PressToOn1" 1 "PressToOff1" 0 "Reset" ;
VAL_ 810 ExtLghtFront_D_RqOta 7 "NotUsed" 6 "PressToOn3" 5 "PressToOff3" 4 "PressToOn2" 3 "PressToOff2" 2 "PressToOn1" 1 "PressToOff1" 0 "Reset" ;
VAL_ 810 TlghtTest_D_RqArb 3 "TestEndAcknowledge" 2 "StartTest" 1 "StopTest" 0 "Null" ;
VAL_ 810 ChrgrPncSustn_B_Rq 1 "Active" 0 "Inactive" ;
VAL_ 1082 VdmSustnActv_B_Rq_UB 1 "Fresh_data" 0 "Unchanged_data" ;
VAL_ 1082 VdmSustnActv_B_Rq 1 "Active" 0 "Inactive" ;
VAL_ 1082 ChrgStatDsply_D_Rq_UB 1 "Fresh_data" 0 "Unchanged_data" ;
VAL_ 1082 ChrgStatDsply_D_Rq 3 "NotUsed_2" 2 "NotUsed_1" 1 "On" 0 "Off" ;
VAL_ 1082 ChrgCordUnlock_B_Rq_UB 1 "Fresh_data" 0 "Unchanged_data" ;
VAL_ 1082 ChrgCordUnlock_B_Rq 1 "Request" 0 "NoRequest" ;
VAL_ 1082 FldngSeatPwOffOk_B_Stat_UB 1 "Fresh_data" 0 "Unchanged_data" ;
VAL_ 1082 FldngSeatPwOffOk_B_Stat 1 "Yes" 0 "No" ;
VAL_ 1082 EngAirFilt_B_RqReset_UB 1 "Fresh_data" 0 "Unchanged_data" ;
VAL_ 1082 EngAirFilt_B_RqReset 1 "Yes" 0 "No" ;
VAL_ 1082 TrailCtl_D_Stat_UB 1 "Fresh_data" 0 "Unchanged_data" ;
VAL_ 1082 TrailCtl_D_Stat 7 "Faulty" 6 "DescentOnly" 5 "EnabledDeny" 4 "StandbyOverThreshold" 3 "StandbyOverride" 2 "Active" 1 "EnabledDescent" 0 "Off" ;
VAL_ 1082 DrLckActv_B_RqBalrr_UB 1 "Fresh_data" 0 "Unchanged_data" ;
VAL_ 1082 DrLckActv_B_RqBalrl_UB 1 "Fresh_data" 0 "Unchanged_data" ;
VAL_ 1082 DrLckActv_B_RqBalrr 1 "Active" 0 "Null" ;
VAL_ 1082 DrLckActv_B_RqBalrl 1 "Active" 0 "Null" ;
VAL_ 1082 EmgcyCall_D_Stat 7 "NotUsed_3" 6 "NotUsed_2" 5 "NotUsed_1" 4 "ManualEmergencyCall" 3 "AutoEmergencyCall" 2 "NoEvent" 1 "EmergencyCallNotSupported" 0 "Null" ;
VAL_ 1082 EmgcyCall_D_Stat_UB 1 "Fresh_data" 0 "Unchanged_data" ;
VAL_ 1082 EmPrflNo_D_Rq_UB 1 "Fresh_data" 0 "Unchanged_data" ;
VAL_ 1082 EmPrflKeyAssoc_D_Rq_UB 1 "Fresh_data" 0 "Unchanged_data" ;
VAL_ 1082 EmPrflNo_D_Rq 7 "NotUsed_3" 6 "NotUsed_2" 5 "NotUsed_1" 4 "Pers4" 3 "Pers3" 2 "Pers2" 1 "Pers1" 0 "Null" ;
VAL_ 1082 EmPrflKeyAssoc_D_Rq 7 "NotUsed_3" 6 "DisassociatePhone" 5 "EnterPhoneAssociation" 4 "OverwriteKey" 3 "DisassociateKey" 2 "ExitKeyAssociation" 1 "EnterKeyAssociation" 0 "Null" ;
VAL_ 1082 CamraViewSplit_B_Rq_UB 1 "Fresh_data" 0 "Unchanged_data" ;
VAL_ 1082 HMI_HMIMode_St 7 "NotUsed2" 6 "NotUsed1" 5 "Load_Shed_Active" 0 "Invalid" 1 "OffMode" 2 "On" 3 "Phone" 4 "Climate" ;
VAL_ 1082 CamraViewSplit_B_Rq 1 "On" 0 "Off" ;
VAL_ 1082 HMI_HMIMode_St_UB 1 "Fresh_data" 0 "Unchanged_data" ;
